VERSION ""

NS_ :

BS_:

BU_: ESM HIB HIP HIS SaGE CBC DASM DIAGNOST EBCM ECM EPS ESC ESL ETM HALF HCP IC OCM ORC PTS RF_HUB SCCM SGW

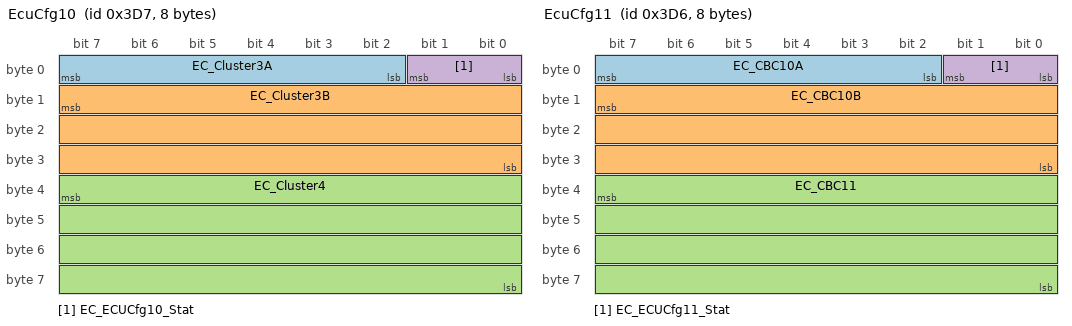
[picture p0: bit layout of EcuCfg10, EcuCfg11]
BO_ 983 EcuCfg10: 8 CBC
 SG_ EC_Cluster3A : 2|6@1+ (1,0) [0|0] ""  RF_HUB,SGW
 SG_ EC_Cluster3B : 15|24@0+ (1,0) [0|0] ""  RF_HUB,SGW
 SG_ EC_Cluster4 : 39|32@0+ (1,0) [0|0] ""  RF_HUB,SGW
 SG_ EC_ECUCfg10_Stat : 0|2@1+ (1,0) [0|0] ""  IC,RF_HUB,SGW

BO_ 982 EcuCfg11: 8 CBC
 SG_ EC_CBC10A : 2|6@1+ (1,0) [0|0] ""  RF_HUB,SGW
 SG_ EC_CBC10B : 15|24@0+ (1,0) [0|0] ""  RF_HUB,SGW
 SG_ EC_CBC11 : 39|32@0+ (1,0) [0|0] ""  RF_HUB,SGW
 SG_ EC_ECUCfg11_Stat : 0|2@1+ (1,0) [0|0] ""  RF_HUB,SGW

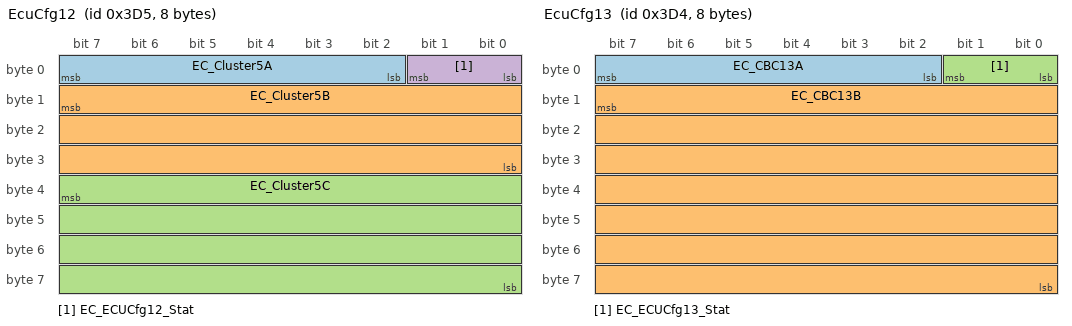
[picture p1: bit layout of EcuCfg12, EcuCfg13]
BO_ 981 EcuCfg12: 8 CBC
 SG_ EC_Cluster5A : 2|6@1+ (1,0) [0|0] ""  RF_HUB,SGW
 SG_ EC_Cluster5B : 15|24@0+ (1,0) [0|0] ""  RF_HUB,SGW
 SG_ EC_Cluster5C : 39|32@0+ (1,0) [0|0] ""  RF_HUB,SGW
 SG_ EC_ECUCfg12_Stat : 0|2@1+ (1,0) [0|0] ""  IC,RF_HUB,SGW

BO_ 980 EcuCfg13: 8 CBC
 SG_ EC_CBC13A : 2|6@1+ (1,0) [0|0] ""  RF_HUB,SGW
 SG_ EC_CBC13B : 15|56@0+ (1,0) [0|0] ""  RF_HUB,SGW
 SG_ EC_ECUCfg13_Stat : 0|2@1+ (1,0) [0|0] ""  RF_HUB,SGW

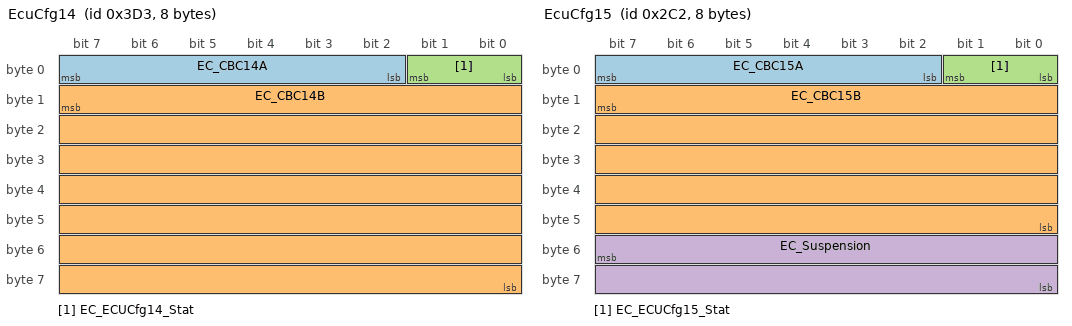
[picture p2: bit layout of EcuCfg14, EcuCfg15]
BO_ 979 EcuCfg14: 8 CBC
 SG_ EC_CBC14A : 2|6@1+ (1,0) [0|0] ""  RF_HUB,SGW
 SG_ EC_CBC14B : 15|56@0+ (1,0) [0|0] ""  RF_HUB,SGW
 SG_ EC_ECUCfg14_Stat : 0|2@1+ (1,0) [0|0] ""  RF_HUB,SGW

BO_ 706 EcuCfg15: 8 CBC
 SG_ EC_CBC15A : 2|6@1+ (1,0) [0|0] ""  RF_HUB,SGW
 SG_ EC_CBC15B : 15|40@0+ (1,0) [0|0] ""  RF_HUB,SGW
 SG_ EC_ECUCfg15_Stat : 0|2@1+ (1,0) [0|0] ""  RF_HUB,SGW
 SG_ EC_Suspension : 55|16@0+ (1,0) [0|0] ""  RF_HUB,SGW

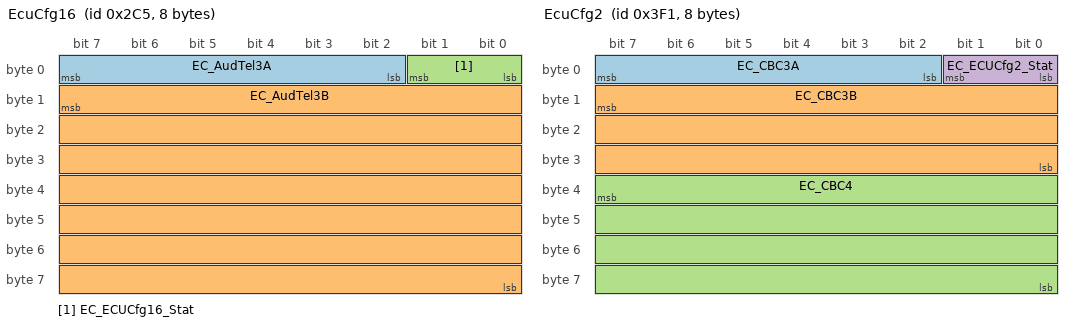
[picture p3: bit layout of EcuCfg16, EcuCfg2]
BO_ 709 EcuCfg16: 8 CBC
 SG_ EC_AudTel3A : 2|6@1+ (1,0) [0|0] ""  RF_HUB,SGW
 SG_ EC_AudTel3B : 15|56@0+ (1,0) [0|0] ""  RF_HUB,SGW
 SG_ EC_ECUCfg16_Stat : 0|2@1+ (1,0) [0|0] ""  RF_HUB,SGW

BO_ 710 EcuCfg17: 8 CBC
 SG_ EC_ECUCfg17_Stat : 0|2@1+ (1,0) [0|0] ""  PTS,RF_HUB,SGW
 SG_ EC_PTS : 56|8@1+ (1,0) [0|0] ""  PTS,RF_HUB,SGW

BO_ 1009 EcuCfg2: 8 CBC
 SG_ EC_CBC3A : 2|6@1+ (1,0) [0|0] ""  RF_HUB,SGW
 SG_ EC_CBC3B : 15|24@0+ (1,0) [0|0] ""  RF_HUB,SGW
 SG_ EC_CBC4 : 39|32@0+ (1,0) [0|0] ""  RF_HUB,SGW
 SG_ EC_ECUCfg2_Stat : 0|2@1+ (1,0) [0|0] ""  RF_HUB,SGW

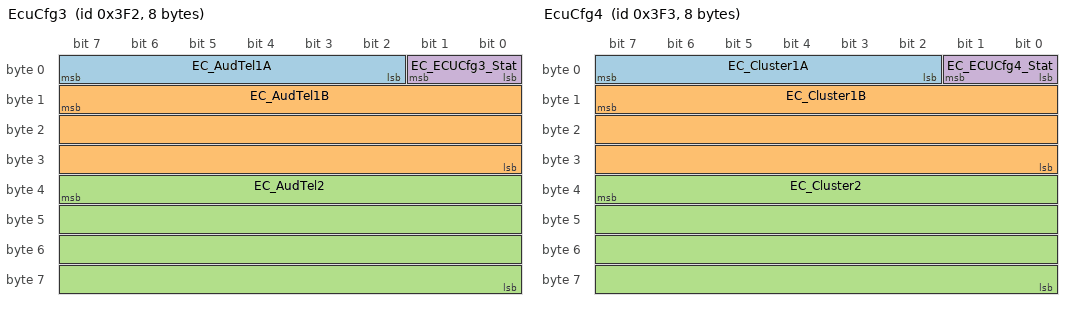
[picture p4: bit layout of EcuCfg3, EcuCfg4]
BO_ 1010 EcuCfg3: 8 CBC
 SG_ EC_AudTel1A : 2|6@1+ (1,0) [0|0] ""  RF_HUB,SGW
 SG_ EC_AudTel1B : 15|24@0+ (1,0) [0|0] ""  RF_HUB,SGW
 SG_ EC_AudTel2 : 39|32@0+ (1,0) [0|0] ""  RF_HUB,SGW
 SG_ EC_ECUCfg3_Stat : 0|2@1+ (1,0) [0|0] ""  RF_HUB,SGW

BO_ 1011 EcuCfg4: 8 CBC
 SG_ EC_Cluster1A : 2|6@1+ (1,0) [0|0] ""  IC,RF_HUB,SGW
 SG_ EC_Cluster1B : 15|24@0+ (1,0) [0|0] ""  IC,RF_HUB,SGW
 SG_ EC_Cluster2 : 39|32@0+ (1,0) [0|0] ""  RF_HUB,SGW
 SG_ EC_ECUCfg4_Stat : 0|2@1+ (1,0) [0|0] ""  IC,RF_HUB,SGW

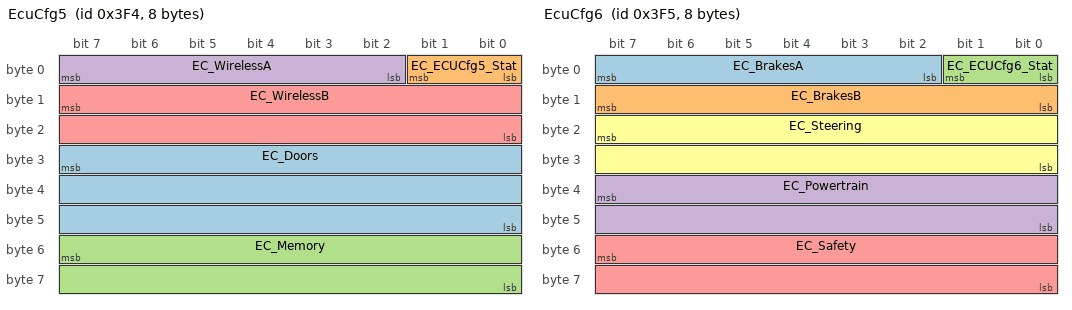
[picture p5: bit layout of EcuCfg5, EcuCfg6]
BO_ 1012 EcuCfg5: 8 CBC
 SG_ EC_Doors : 31|24@0+ (1,0) [0|0] ""  RF_HUB,SGW
 SG_ EC_ECUCfg5_Stat : 0|2@1+ (1,0) [0|0] ""  OCM,RF_HUB,SGW
 SG_ EC_Memory : 55|16@0+ (1,0) [0|0] ""  OCM,RF_HUB,SGW
 SG_ EC_WirelessA : 2|6@1+ (1,0) [0|0] ""  RF_HUB,SGW
 SG_ EC_WirelessB : 15|16@0+ (1,0) [0|0] ""  RF_HUB,SGW

BO_ 1013 EcuCfg6: 8 CBC
 SG_ EC_BrakesA : 2|6@1+ (1,0) [0|0] ""  ESC,RF_HUB,SGW
 SG_ EC_BrakesB : 8|8@1+ (1,0) [0|0] ""  ESC,RF_HUB,SGW
 SG_ EC_ECUCfg6_Stat : 0|2@1+ (1,0) [0|0] ""  ECM,EPS,ESC,ORC,RF_HUB,SGW
 SG_ EC_Powertrain : 39|16@0+ (1,0) [0|0] ""  RF_HUB,SGW
 SG_ EC_Safety : 55|16@0+ (1,0) [0|0] ""  ORC,RF_HUB,SGW
 SG_ EC_Steering : 23|16@0+ (1,0) [0|0] ""  HIB,EPS,RF_HUB,SGW

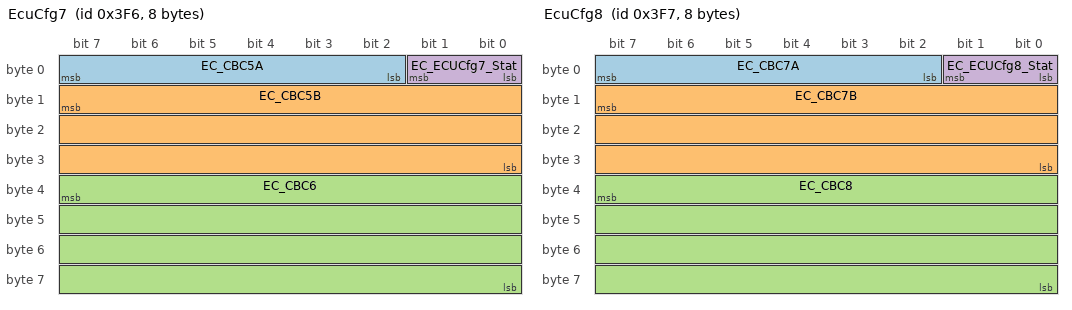
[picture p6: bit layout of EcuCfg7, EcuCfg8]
BO_ 1014 EcuCfg7: 8 CBC
 SG_ EC_CBC5A : 2|6@1+ (1,0) [0|0] ""  RF_HUB,SGW
 SG_ EC_CBC5B : 15|24@0+ (1,0) [0|0] ""  RF_HUB,SGW
 SG_ EC_CBC6 : 39|32@0+ (1,0) [0|0] ""  RF_HUB,SGW
 SG_ EC_ECUCfg7_Stat : 0|2@1+ (1,0) [0|0] ""  RF_HUB,SGW

BO_ 1015 EcuCfg8: 8 CBC
 SG_ EC_CBC7A : 2|6@1+ (1,0) [0|0] ""  RF_HUB,SGW
 SG_ EC_CBC7B : 15|24@0+ (1,0) [0|0] ""  RF_HUB,SGW
 SG_ EC_CBC8 : 39|32@0+ (1,0) [0|0] ""  RF_HUB,SGW
 SG_ EC_ECUCfg8_Stat : 0|2@1+ (1,0) [0|0] ""  RF_HUB,SGW

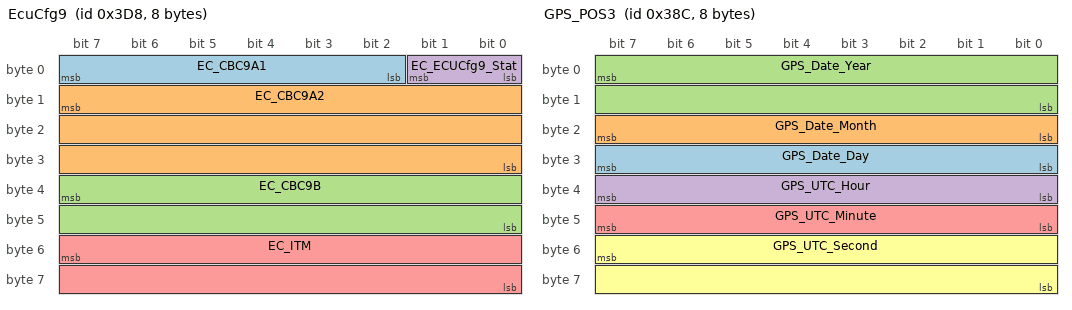
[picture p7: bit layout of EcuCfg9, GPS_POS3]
BO_ 984 EcuCfg9: 8 CBC
 SG_ EC_CBC9A1 : 2|6@1+ (1,0) [0|0] ""  RF_HUB,SGW
 SG_ EC_CBC9A2 : 15|24@0+ (1,0) [0|0] ""  RF_HUB,SGW
 SG_ EC_CBC9B : 39|16@0+ (1,0) [0|0] ""  RF_HUB,SGW
 SG_ EC_ECUCfg9_Stat : 0|2@1+ (1,0) [0|0] ""  RF_HUB,SGW
 SG_ EC_ITM : 55|16@0+ (1,0) [0|0] ""  RF_HUB,SGW

BO_ 908 GPS_POS3: 8 CBC
 SG_ GPS_Date_Day : 24|8@1+ (1,0) [1|31] "Days"  HCP,SGW
 SG_ GPS_Date_Month : 16|8@1+ (1,0) [1|12] "Months"  HCP,SGW
 SG_ GPS_Date_Year : 7|16@0+ (1,0) [0|65534] "Years"  HCP,SGW
 SG_ GPS_UTC_Hour : 32|8@1+ (1,0) [0|23] "h"  HCP,SGW
 SG_ GPS_UTC_Minute : 40|8@1+ (1,0) [0|59] "min"  HCP,SGW
 SG_ GPS_UTC_Second : 55|16@0+ (0.01,0) [0|59.99] "s"  HCP,SGW

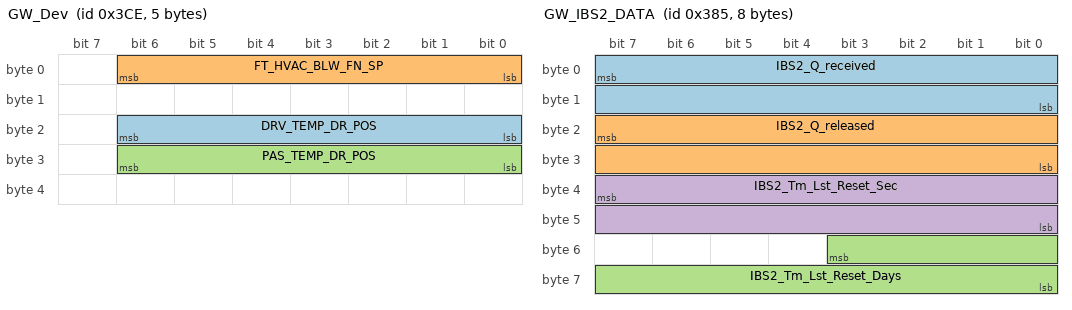
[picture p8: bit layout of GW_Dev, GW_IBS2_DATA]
BO_ 974 GW_Dev: 5 CBC
 SG_ DRV_TEMP_DR_POS : 16|7@1+ (1,0) [0|100] "%"  ECM,HCP,SGW
 SG_ FT_HVAC_BLW_FN_SP : 0|7@1+ (1,0) [0|100] "Bars"  ECM,SGW
 SG_ PAS_TEMP_DR_POS : 24|7@1+ (1,0) [0|100] "%"  HCP,SGW

BO_ 901 GW_IBS2_DATA: 8 CBC
 SG_ IBS2_Q_received : 7|16@0+ (0.125,0) [0|8191.75] "Ah"  SGW
 SG_ IBS2_Q_released : 23|16@0+ (0.125,0) [0|8191.75] "Ah"  SGW
 SG_ IBS2_Tm_Lst_Reset_Days : 51|12@0+ (1,0) [0|4094] "Days"  SGW
 SG_ IBS2_Tm_Lst_Reset_Sec : 39|16@0+ (2,0) [0|86398] "sec"  SGW

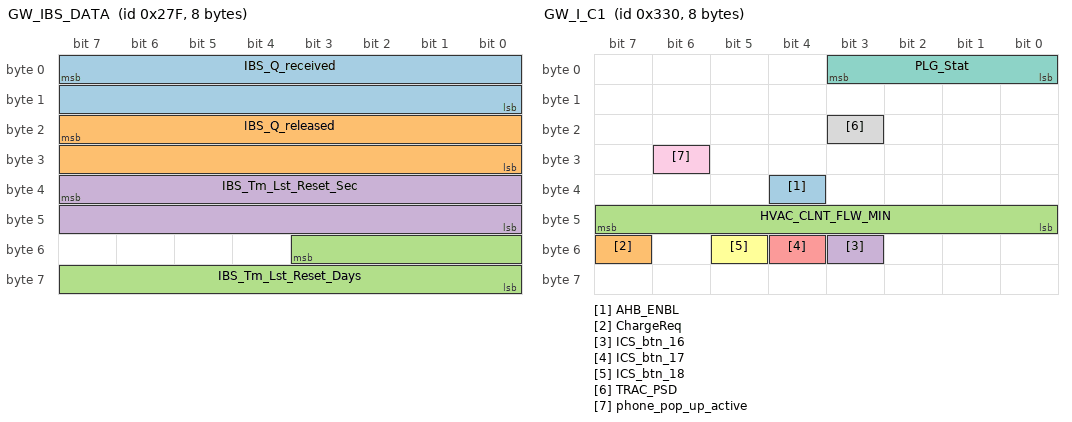
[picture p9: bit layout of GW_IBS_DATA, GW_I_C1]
BO_ 639 GW_IBS_DATA: 8 CBC
 SG_ IBS_Q_received : 7|16@0+ (0.125,0) [0|8191.75] "Ah"  SGW
 SG_ IBS_Q_released : 23|16@0+ (0.125,0) [0|8191.75] "Ah"  SGW
 SG_ IBS_Tm_Lst_Reset_Days : 51|12@0+ (1,0) [0|4094] "Days"  SGW
 SG_ IBS_Tm_Lst_Reset_Sec : 39|16@0+ (2,0) [0|86398] "sec"  SGW

BO_ 816 GW_I_C1: 8 CBC
 SG_ AHB_ENBL : 36|1@1+ (1,0) [0|0] ""  SGW
 SG_ ChargeReq : 55|1@1+ (1,0) [0|0] ""  HCP,IC,SGW
 SG_ HVAC_CLNT_FLW_MIN : 40|8@1+ (0.521555,0) [0.521555|131.953415] "LpM"  SGW
 SG_ ICS_btn_16 : 51|1@1+ (1,0) [0|0] ""  PTS,SGW
 SG_ ICS_btn_17 : 52|1@1+ (1,0) [0|0] ""  PTS,SGW
 SG_ ICS_btn_18 : 53|1@1+ (1,0) [0|0] ""  HIB,HALF,SGW
 SG_ PLG_Stat : 0|4@1+ (1,0) [0|0] ""  IC,SGW
 SG_ TRAC_PSD : 19|1@1+ (1,0) [0|0] ""  ESC,IC,SGW
 SG_ phone_pop_up_active : 30|1@1+ (1,0) [0|0] ""  IC,SGW

BO_ 853 GW_LIN_I_C1: 8 CBC
 SG_ IBS_IBATT_QUIESCENT : 56|8@1+ (0.00390625,0) [0|0.984375] "Amp"  SGW

BO_ 854 GW_LIN_I_C1_IBS2: 8 CBC
 SG_ IBS2_IBATT_QUIESCENT : 56|8@1+ (0.00390625,0) [0|0.984375] "Amp"  SGW

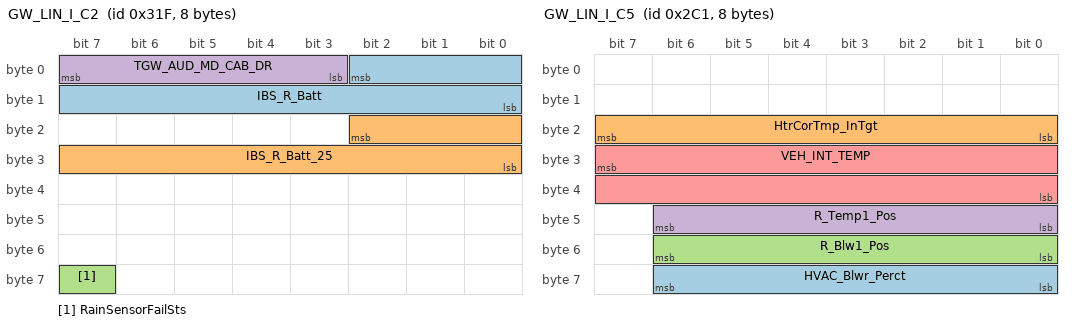
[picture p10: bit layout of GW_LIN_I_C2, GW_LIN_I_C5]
BO_ 799 GW_LIN_I_C2: 8 CBC
 SG_ IBS_R_Batt : 2|11@0+ (0.05,0) [0|20] "mOhm"  SGW
 SG_ IBS_R_Batt_25 : 18|11@0+ (0.05,0) [0|20] "mOhm"  SGW
 SG_ RainSensorFailSts : 63|1@1+ (1,0) [0|0] ""  IC,SGW
 SG_ TGW_AUD_MD_CAB_DR : 3|5@1+ (1,0) [0|0] ""  IC,SGW

BO_ 798 GW_LIN_I_C2_IBS2: 8 CBC
 SG_ IBS2_R_Batt : 2|11@0+ (0.05,0) [0|20] "mOhm"  SGW
 SG_ IBS2_R_Batt_25 : 18|11@0+ (0.05,0) [0|20] "mOhm"  SGW

BO_ 817 GW_LIN_I_C3: 8 CBC
 SG_ PSD_LT_DisplayStat : 56|4@1+ (1,0) [0|0] ""  IC,SGW
 SG_ PSD_RT_DisplayStat : 60|4@1+ (1,0) [0|0] ""  IC,SGW

BO_ 579 GW_LIN_I_C4: 8 CBC
 SG_ Phone_Popup_setting_active : 55|1@1+ (1,0) [0|0] ""  IC,SGW
 SG_ TGW_AUD_MD2_CAB_DR : 24|6@1+ (1,0) [0|0] ""  IC,SGW

BO_ 705 GW_LIN_I_C5: 8 CBC
 SG_ HVAC_Blwr_Perct : 56|7@1+ (1,0) [0|100] "%"  HCP,SGW
 SG_ HtrCorTmp_InTgt : 16|8@1+ (1,-40) [-40|214] "°C"  HCP,SGW
 SG_ R_Blw1_Pos : 48|7@1+ (1,0) [0|100] "%"  HCP,SGW
 SG_ R_Temp1_Pos : 40|7@1+ (1,0) [0|100] "%"  HCP,SGW
 SG_ VEH_INT_TEMP : 31|16@0+ (0.01,-40) [-40|85] "°C"  HCP,SGW

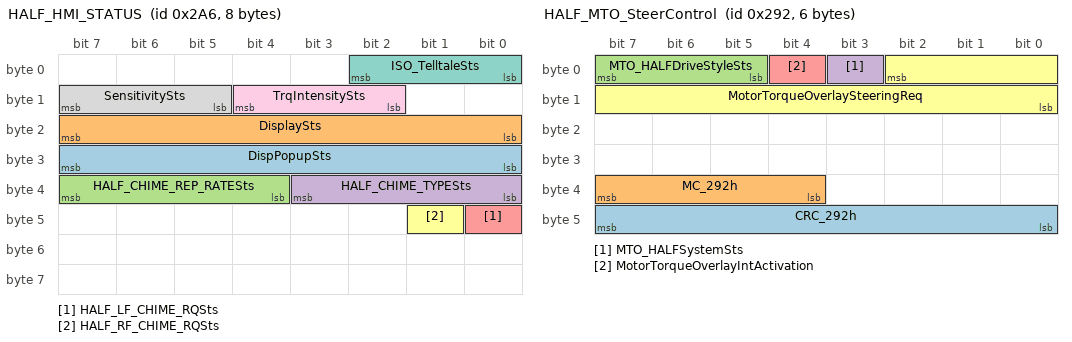
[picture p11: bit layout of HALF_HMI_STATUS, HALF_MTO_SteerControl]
BO_ 678 HALF_HMI_STATUS: 8 HALF
 SG_ DispPopupSts : 24|8@1+ (1,0) [0|0] ""  IC,ORC,SGW
 SG_ DisplaySts : 16|8@1+ (1,0) [0|0] ""  IC,ORC,SGW
 SG_ HALF_CHIME_REP_RATESts : 36|4@1+ (1,0) [0|15] ""  CBC,SGW
 SG_ HALF_CHIME_TYPESts : 32|4@1+ (1,0) [0|0] ""  CBC,SGW
 SG_ HALF_LF_CHIME_RQSts : 40|1@1+ (1,0) [0|0] ""  CBC,SGW
 SG_ HALF_RF_CHIME_RQSts : 41|1@1+ (1,0) [0|0] ""  CBC,SGW
 SG_ ISO_TelltaleSts : 0|3@1+ (1,0) [0|0] ""  IC,ORC,SGW
 SG_ SensitivitySts : 13|3@1+ (1,0) [0|0] ""  IC,SGW
 SG_ TrqIntensitySts : 10|3@1+ (1,0) [0|0] ""  IC,SGW

BO_ 658 HALF_MTO_SteerControl: 6 HALF
 SG_ CRC_292h : 40|8@1+ (1,0) [0|0] ""  EPS,SGW
 SG_ MC_292h : 36|4@1+ (1,0) [0|15] ""  EPS,SGW
 SG_ MTO_HALFDriveStyleSts : 5|3@1+ (1,0) [0|0] ""  EPS,SGW
 SG_ MTO_HALFSystemSts : 3|1@1+ (1,0) [0|0] ""  EPS,SGW
 SG_ MotorTorqueOverlayIntActivation : 4|1@1+ (1,0) [0|0] ""  EPS,SGW
 SG_ MotorTorqueOverlaySteeringReq : 2|11@0+ (0.001953125,-2) [-2|1.998047] "Nm"  EPS,SGW

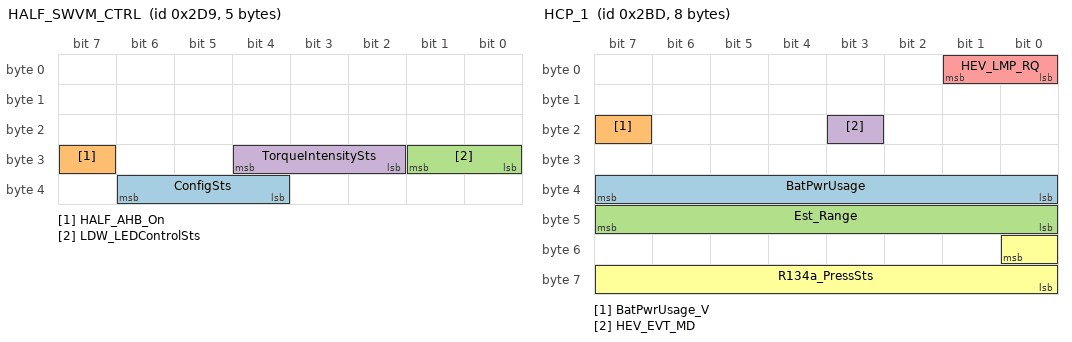
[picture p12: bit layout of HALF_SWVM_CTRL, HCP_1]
BO_ 729 HALF_SWVM_CTRL: 5 HALF
 SG_ ConfigSts : 36|3@1+ (1,0) [0|0] ""  CBC,SGW
 SG_ HALF_AHB_On : 31|1@1+ (1,0) [0|0] ""  CBC,SGW
 SG_ LDW_LEDControlSts : 24|2@1+ (1,0) [0|0] ""  CBC,SGW
 SG_ TorqueIntensitySts : 26|3@1+ (1,0) [0|0] ""  CBC,SGW

BO_ 701 HCP_1: 8 HCP
 SG_ BatPwrUsage : 32|8@1+ (1,-125) [-125|130] "kW"  IC,SGW
 SG_ BatPwrUsage_V : 23|1@1+ (1,0) [0|0] ""  IC,SGW
 SG_ Est_Range : 40|8@1+ (1,0) [0|254] "km"  ETM,IC,SGW
 SG_ HEV_EVT_MD : 19|1@1+ (1,0) [0|0] ""  HIB,CBC,DASM,ETM,IC,SGW
 SG_ HEV_LMP_RQ : 0|2@1+ (1,0) [0|0] ""  ETM,IC,ORC,SGW
 SG_ R134a_PressSts : 48|9@0+ (0.1,0) [0|40] "bar"  CBC,SGW

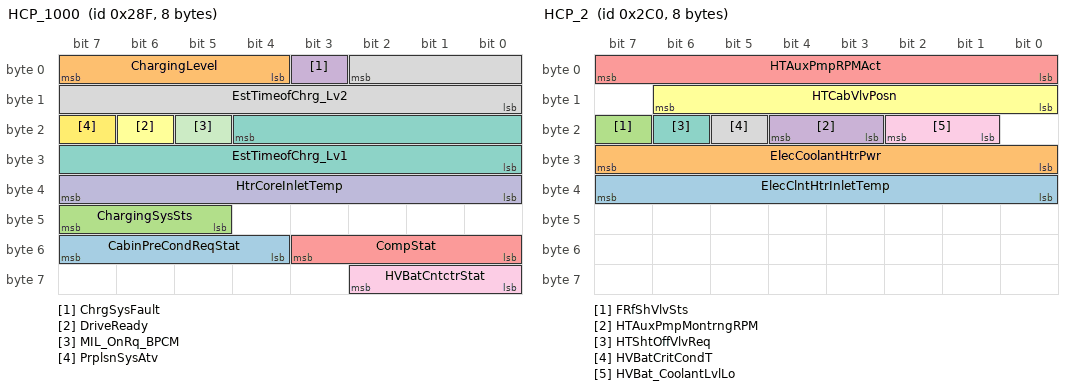
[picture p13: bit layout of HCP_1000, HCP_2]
BO_ 655 HCP_1000: 8 HCP
 SG_ CabinPreCondReqStat : 52|4@1+ (1,0) [0|0] ""  ETM,SGW
 SG_ ChargingLevel : 4|4@1+ (1,0) [0|0] ""  CBC,ETM,IC,SGW
 SG_ ChargingSysSts : 45|3@1+ (1,0) [0|0] ""  ETM,IC,SGW
 SG_ ChrgSysFault : 3|1@1+ (1,0) [0|0] ""  ETM,IC,SGW
 SG_ CompStat : 48|4@1+ (1,0) [0|0] ""  CBC,SGW
 SG_ DriveReady : 22|1@1+ (1,0) [0|0] ""  HIB,CBC,DASM,IC,SGW
 SG_ EstTimeofChrg_Lv1 : 20|13@0+ (1,0) [0|8190] "min"  ETM,IC,SGW
 SG_ EstTimeofChrg_Lv2 : 2|11@0+ (1,0) [0|2046] "min"  ETM,IC,SGW
 SG_ HVBatCntctrStat : 56|3@1+ (1,0) [0|0] ""  IC,SGW
 SG_ HtrCoreInletTemp : 32|8@1+ (1,-40) [-40|214] "°C"  CBC,ECM,SGW
 SG_ MIL_OnRq_BPCM : 21|1@1+ (1,0) [0|0] ""  IC,SGW
 SG_ PrplsnSysAtv : 23|1@1+ (1,0) [0|0] ""  CBC,ECM,EPS,ESC,ETM,HCP,IC,PTS,RF_HUB,SGW

BO_ 704 HCP_2: 8 HCP
 SG_ ElecClntHtrInletTemp : 32|8@1+ (1,-40) [-40|214] "°C"  ECM,SGW
 SG_ ElecCoolantHtrPwr : 24|8@1+ (0.04,0) [0|10.16] "kW"  CBC,ECM,SGW
 SG_ FRfShVlvSts : 23|1@1+ (1,0) [0|0] ""  CBC,SGW
 SG_ HTAuxPmpMontrngRPM : 19|2@1+ (1,0) [0|0] ""  ECM,SGW
 SG_ HTAuxPmpRPMAct : 0|8@1+ (24,0) [0|6096] "rpm"  CBC,ECM,SGW
 SG_ HTCabVlvPosn : 8|7@1+ (1,0) [0|100] "%"  CBC,ECM,SGW
 SG_ HTShtOffVlvReq : 22|1@1+ (1,0) [0|0] ""  CBC,ECM,SGW
 SG_ HVBatCritCondT : 21|1@1+ (1,0) [0|0] ""  CBC,SGW
 SG_ HVBat_CoolantLvlLo : 17|2@1+ (1,0) [0|0] ""  IC,SGW

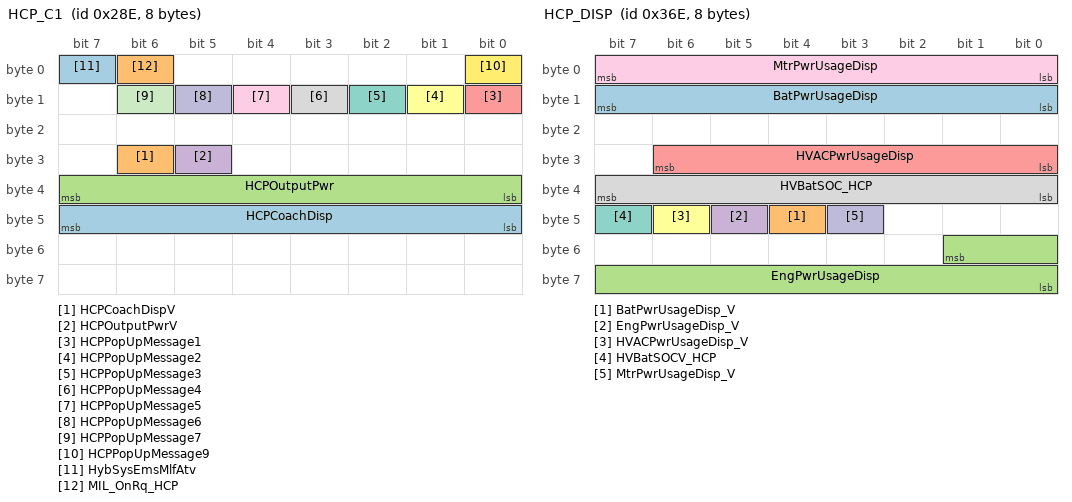
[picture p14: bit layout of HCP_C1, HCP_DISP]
BO_ 654 HCP_C1: 8 HCP
 SG_ HCPCoachDisp : 40|8@1+ (1,-100) [-100|100] "%"  IC,SGW
 SG_ HCPCoachDispV : 30|1@1+ (1,0) [0|0] ""  IC,SGW
 SG_ HCPOutputPwr : 32|8@1+ (1,-100) [-100|100] "%"  IC,SGW
 SG_ HCPOutputPwrV : 29|1@1+ (1,0) [0|0] ""  IC,SGW
 SG_ HCPPopUpMessage1 : 8|1@1+ (1,0) [0|0] ""  IC,SGW
 SG_ HCPPopUpMessage2 : 9|1@1+ (1,0) [0|0] ""  IC,SGW
 SG_ HCPPopUpMessage3 : 10|1@1+ (1,0) [0|0] ""  IC,SGW
 SG_ HCPPopUpMessage4 : 11|1@1+ (1,0) [0|0] ""  IC,SGW
 SG_ HCPPopUpMessage5 : 12|1@1+ (1,0) [0|0] ""  IC,SGW
 SG_ HCPPopUpMessage6 : 13|1@1+ (1,0) [0|0] ""  IC,SGW
 SG_ HCPPopUpMessage7 : 14|1@1+ (1,0) [0|0] ""  IC,SGW
 SG_ HCPPopUpMessage9 : 0|1@1+ (1,0) [0|0] ""  IC,SGW
 SG_ HybSysEmsMlfAtv : 7|1@1+ (1,0) [0|0] ""  SGW
 SG_ MIL_OnRq_HCP : 6|1@1+ (1,0) [0|0] ""  ECM,SGW

BO_ 878 HCP_DISP: 8 HCP
 SG_ BatPwrUsageDisp : 8|8@1+ (1,-125) [-125|130] "kW"  ETM,SGW
 SG_ BatPwrUsageDisp_V : 44|1@1+ (1,0) [0|0] ""  ETM,SGW
 SG_ EngPwrUsageDisp : 49|10@0+ (1,0) [0|1023] "kW"  ETM,IC,SGW
 SG_ EngPwrUsageDisp_V : 45|1@1+ (1,0) [0|0] ""  ETM,IC,SGW
 SG_ HVACPwrUsageDisp : 24|7@1+ (1,0) [0|127] "kW"  ETM,SGW
 SG_ HVACPwrUsageDisp_V : 46|1@1+ (1,0) [0|0] ""  ETM,SGW
 SG_ HVBatSOCV_HCP : 47|1@1+ (1,0) [0|0] ""  ETM,IC,SGW
 SG_ HVBatSOC_HCP : 32|8@1+ (0.3922,0) [0|100] "%"  ETM,IC,SGW
 SG_ MtrPwrUsageDisp : 0|8@1+ (1,-125) [-125|130] "kW"  IC,SGW
 SG_ MtrPwrUsageDisp_V : 43|1@1+ (1,0) [0|0] ""  IC,SGW

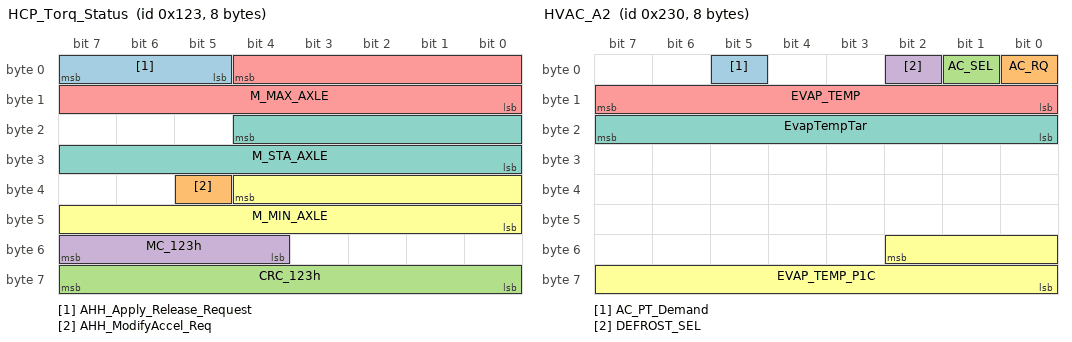
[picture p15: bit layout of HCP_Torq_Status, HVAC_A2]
BO_ 291 HCP_Torq_Status: 8 HCP
 SG_ AHH_Apply_Release_Request : 5|3@1+ (1,0) [0|0] ""  ESC,SGW
 SG_ AHH_ModifyAccel_Req : 37|1@1+ (1,0) [0|0] ""  ECM,SGW
 SG_ CRC_123h : 56|8@1+ (1,0) [0|255] ""  HIB,DASM,ESC,SGW
 SG_ MC_123h : 52|4@1+ (1,0) [0|15] ""  HIB,DASM,ESC,SGW
 SG_ M_MAX_AXLE : 4|13@0+ (4,-7767) [-7767|24993] ""  HIB,DASM,ESC,SGW
 SG_ M_MIN_AXLE : 36|13@0+ (4,-7767) [-7767|24993] ""  HIB,DASM,ESC,SGW
 SG_ M_STA_AXLE : 20|13@0+ (4,-7767) [-7767|24993] ""  HIB,DASM,ECM,ESC,ORC,SGW

BO_ 560 HVAC_A2: 8 CBC
 SG_ AC_PT_Demand : 5|1@1+ (1,0) [0|0] ""  ECM,SGW
 SG_ AC_RQ : 0|1@1+ (1,0) [0|0] ""  HCP,SGW
 SG_ AC_SEL : 1|1@1+ (1,0) [0|0] ""  SGW
 SG_ DEFROST_SEL : 2|1@1+ (1,0) [0|0] ""  HCP,SGW
 SG_ EVAP_TEMP : 8|8@1+ (0.5,-20) [-20|107] "°C"  HCP,SGW
 SG_ EVAP_TEMP_P1C : 50|11@0+ (0.1,-40) [-40|85] "°C"  HCP,SGW
 SG_ EvapTempTar : 16|8@1+ (0.5,-20) [-20|107] "°C"  HCP,SGW

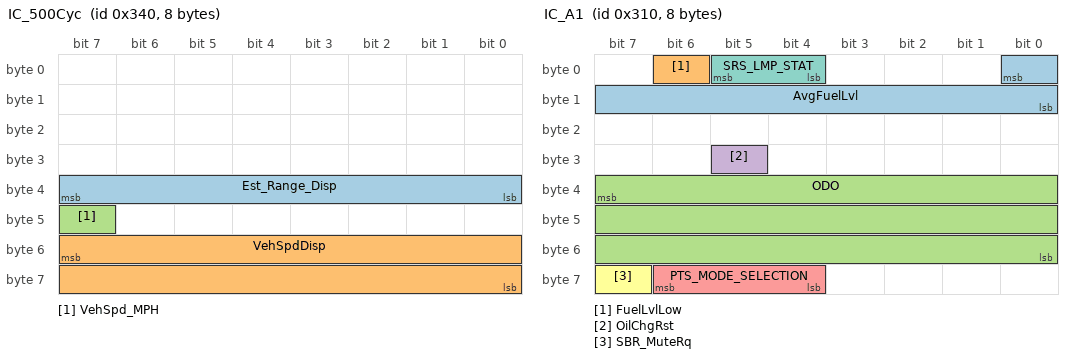
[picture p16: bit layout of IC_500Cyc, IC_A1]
BO_ 832 IC_500Cyc: 8 IC
 SG_ Est_Range_Disp : 32|8@1+ (1,0) [0|254] ""  ETM,SGW
 SG_ VehSpdDisp : 55|16@0+ (1,0) [0|65534] ""  CBC,SGW
 SG_ VehSpd_MPH : 47|1@1+ (1,0) [0|0] ""  CBC,SGW

BO_ 784 IC_A1: 8 IC
 SG_ AvgFuelLvl : 0|9@0+ (0.5,0) [0|255] "liters"  CBC,ETM,SGW
 SG_ FuelLvlLow : 6|1@1+ (1,0) [0|0] ""  CBC,ECM,ETM,SGW
 SG_ ODO : 39|24@0+ (0.1,0) [0|1677721.4] "km"  HIB,CBC,DASM,EBCM,ECM,EPS,ESC,ESL,HALF,HCP,OCM,ORC,PTS,RF_HUB,SCCM,SGW
 SG_ OilChgRst : 29|1@1+ (1,0) [0|0] ""  ECM,SGW
 SG_ PTS_MODE_SELECTION : 60|3@1+ (1,0) [0|0] ""  PTS,SGW
 SG_ SBR_MuteRq : 63|1@1+ (1,0) [0|0] ""  CBC,SGW
 SG_ SRS_LMP_STAT : 4|2@1+ (1,0) [0|0] ""  ETM,ORC,SGW

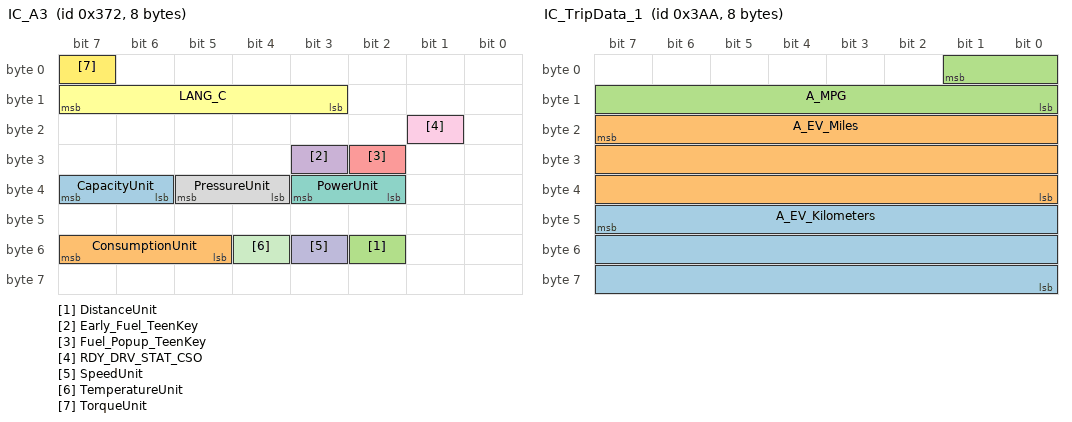
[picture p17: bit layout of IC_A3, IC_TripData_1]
BO_ 882 IC_A3: 8 IC
 SG_ CapacityUnit : 38|2@1+ (1,0) [0|0] ""  CBC,SGW
 SG_ ConsumptionUnit : 53|3@1+ (1,0) [0|0] ""  CBC,SGW
 SG_ DistanceUnit : 50|1@1+ (1,0) [0|0] ""  CBC,SGW
 SG_ Early_Fuel_TeenKey : 27|1@1+ (1,0) [0|0] ""  CBC,SGW
 SG_ Fuel_Popup_TeenKey : 26|1@1+ (1,0) [0|0] ""  CBC,SGW
 SG_ LANG_C : 11|5@1+ (1,0) [0|0] ""  CBC,SGW
 SG_ PowerUnit : 34|2@1+ (1,0) [0|0] ""  CBC,SGW
 SG_ PressureUnit : 36|2@1+ (1,0) [0|0] ""  CBC,SGW
 SG_ RDY_DRV_STAT_CSO : 17|1@1+ (1,0) [0|0] ""  CBC,SGW
 SG_ SpeedUnit : 51|1@1+ (1,0) [0|0] ""  HIB,CBC,DASM,ECM,SGW
 SG_ TemperatureUnit : 52|1@1+ (1,0) [0|0] ""  CBC,SGW
 SG_ TorqueUnit : 7|1@1+ (1,0) [0|0] ""  CBC,SGW

BO_ 782 IC_A5: 8 IC
 SG_ Gas_Range : 1|10@0+ (1,0) [0|1022] "km"  CBC,ETM,SGW
 SG_ Total_Range : 18|11@0+ (1,0) [0|2046] "km"  CBC,ETM,SGW

BO_ 938 IC_TripData_1: 8 IC
 SG_ A_EV_Kilometers : 47|24@0+ (0.1,0) [0|16093.3] "km"  ETM,SGW
 SG_ A_EV_Miles : 23|24@0+ (0.1,0) [0|9999.9] "Mile"  ETM,SGW
 SG_ A_MPG : 1|10@0+ (0.1,0) [0|99.9] "MPG"  ETM,SGW

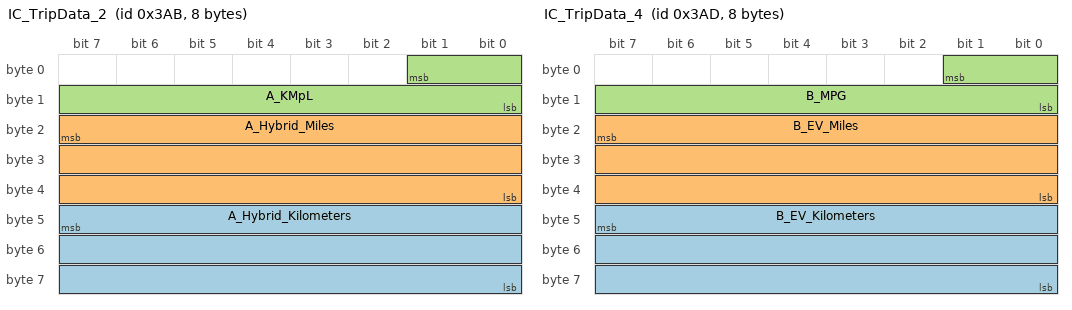
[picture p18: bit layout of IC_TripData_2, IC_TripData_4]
BO_ 939 IC_TripData_2: 8 IC
 SG_ A_Hybrid_Kilometers : 47|24@0+ (0.1,0) [0|16093.3] "km"  ETM,SGW
 SG_ A_Hybrid_Miles : 23|24@0+ (0.1,0) [0|9999.9] "Mile"  ETM,SGW
 SG_ A_KMpL : 1|10@0+ (0.1,0) [0|99.9] "kmpl"  ETM,SGW

BO_ 940 IC_TripData_3: 8 IC
 SG_ A_Total_Dist_Kilometers : 47|24@0+ (0.1,0) [0|16093.3] "km"  ETM,SGW
 SG_ A_Total_Dist_Miles : 23|24@0+ (0.1,0) [0|9999.9] "Mile"  ETM,SGW

BO_ 941 IC_TripData_4: 8 IC
 SG_ B_EV_Kilometers : 47|24@0+ (0.1,0) [0|16093.3] "km"  ETM,SGW
 SG_ B_EV_Miles : 23|24@0+ (0.1,0) [0|9999.9] "Mile"  ETM,SGW
 SG_ B_MPG : 1|10@0+ (0.1,0) [0|99.9] "MPG"  ETM,SGW

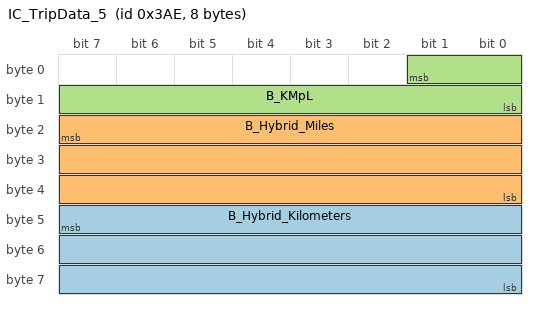
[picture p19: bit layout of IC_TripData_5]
BO_ 942 IC_TripData_5: 8 IC
 SG_ B_Hybrid_Kilometers : 47|24@0+ (0.1,0) [0|16093.3] "km"  ETM,SGW
 SG_ B_Hybrid_Miles : 23|24@0+ (0.1,0) [0|9999.9] "Mile"  ETM,SGW
 SG_ B_KMpL : 1|10@0+ (0.1,0) [0|99.9] "kmpl"  ETM,SGW

CM_ SG_ 983 EC_Cluster3A "Instrument cluster ecu configuration 3A";
CM_ SG_ 983 EC_Cluster3B "Instrument cluster ecu configuration 3B";
CM_ SG_ 983 EC_Cluster4 "Instrument cluster ecu configuration 4";
CM_ SG_ 983 EC_ECUCfg10_Stat "ECU Configuration messages status 10";
CM_ SG_ 982 EC_CBC10A "CBC ecu configuration 10A";
CM_ SG_ 982 EC_CBC10B "CBC ecu configuration 10B";
CM_ SG_ 982 EC_CBC11 "CBC ecu configuration 11";
CM_ SG_ 982 EC_ECUCfg11_Stat "ECU Configuration messages status 11";
CM_ SG_ 981 EC_Cluster5A "Instrument cluster ecu configuration 5A";
CM_ SG_ 981 EC_Cluster5B "Instrument cluster ecu configuration 5B";
CM_ SG_ 981 EC_Cluster5C "Instrument cluster ecu configuration 5C";
CM_ SG_ 981 EC_ECUCfg12_Stat "ECU Configuration messages status 12";
CM_ SG_ 980 EC_CBC13A "CBC ecu configuration 13A";
CM_ SG_ 980 EC_CBC13B "CBC ecu configuration 13B";
CM_ SG_ 980 EC_ECUCfg13_Stat "ECU Configuration messages status 13";
CM_ SG_ 979 EC_CBC14A "CBC ecu configuration 14A";
CM_ SG_ 979 EC_CBC14B "CBC ecu configuration 14B";
CM_ SG_ 979 EC_ECUCfg14_Stat "ECU Configuration messages status 14";
CM_ SG_ 706 EC_CBC15A "CBC ecu configuration 15A";
CM_ SG_ 706 EC_CBC15B "CBC ecu configuration 15B";
CM_ SG_ 706 EC_ECUCfg15_Stat "ECU Configuration messages status 15";
CM_ SG_ 706 EC_Suspension "Suspension ecu configuration";
CM_ SG_ 709 EC_AudTel3A "Audio and telematics ecu configuration 3A";
CM_ SG_ 709 EC_AudTel3B "Audio and telematics ecu configuration 3B";
CM_ SG_ 709 EC_ECUCfg16_Stat "ECU Configuration messages status 16";
CM_ SG_ 710 EC_ECUCfg17_Stat "ECU Configuration messages status 17";
CM_ SG_ 710 EC_PTS "Park assist ecu configuration";
CM_ SG_ 1009 EC_CBC3A "CBC ecu configuration 3A";
CM_ SG_ 1009 EC_CBC3B "CBC ecu configuration 3B";
CM_ SG_ 1009 EC_CBC4 "CBC ecu configuration 4";
CM_ SG_ 1009 EC_ECUCfg2_Stat "ECU Configuration messages status 2";
CM_ SG_ 1010 EC_AudTel1A "Audio and telematics ecu configuration 1A";
CM_ SG_ 1010 EC_AudTel1B "Audio and telematics ecu configuration 1B";
CM_ SG_ 1010 EC_AudTel2 "Audio and telematics ecu configuration 2";
CM_ SG_ 1010 EC_ECUCfg3_Stat "ECU Configuration messages status 3";
CM_ SG_ 1011 EC_Cluster1A "Instrument cluster ecu configuration 1A";
CM_ SG_ 1011 EC_Cluster1B "Instrument cluster ecu configuration 1B";
CM_ SG_ 1011 EC_Cluster2 "Instrument cluster ecu configuration 2";
CM_ SG_ 1011 EC_ECUCfg4_Stat "ECU Configuration messages status 4";
CM_ SG_ 1012 EC_Doors "Doors ecu configuration";
CM_ SG_ 1012 EC_ECUCfg5_Stat "ECU Configuration messages status 5";
CM_ SG_ 1012 EC_Memory "Memory ecu configuration";
CM_ SG_ 1012 EC_WirelessA "Wireless ecu configurationA";
CM_ SG_ 1012 EC_WirelessB "Wireless ecu configurationB";
CM_ SG_ 1013 EC_BrakesA "Brake system ecu configurationA";
CM_ SG_ 1013 EC_BrakesB "Brake system ecu configurationB";
CM_ SG_ 1013 EC_ECUCfg6_Stat "ECU Configuration messages status 6";
CM_ SG_ 1013 EC_Powertrain "Powertrain ecu configuration";
CM_ SG_ 1013 EC_Safety "Safety ecu configuration";
CM_ SG_ 1013 EC_Steering "Steering ecu configuration";
CM_ SG_ 1014 EC_CBC5A "CBC ecu configuration 5A";
CM_ SG_ 1014 EC_CBC5B "CBC ecu configuration 5B";
CM_ SG_ 1014 EC_CBC6 "CBC ecu configuration 6";
CM_ SG_ 1014 EC_ECUCfg7_Stat "ECU Configuration messages status 7";
CM_ SG_ 1015 EC_CBC7A "CBC ecu configuration 7A";
CM_ SG_ 1015 EC_CBC7B "CBC ecu configuration 7B";
CM_ SG_ 1015 EC_CBC8 "CBC ecu configuration 8";
CM_ SG_ 1015 EC_ECUCfg8_Stat "ECU Configuration messages status 8";
CM_ SG_ 984 EC_CBC9A1 "CBC configuration 9A1";
CM_ SG_ 984 EC_CBC9A2 "CBC configuration 9A2";
CM_ SG_ 984 EC_CBC9B "CBC configuration 9B";
CM_ SG_ 984 EC_ECUCfg9_Stat "ECU Configuration messages status 9";
CM_ SG_ 984 EC_ITM "ITM ecu configuration";
CM_ SG_ 908 GPS_Date_Day "GPS date day";
CM_ SG_ 908 GPS_Date_Month "GPS date month";
CM_ SG_ 908 GPS_Date_Year "GPS date year";
CM_ SG_ 908 GPS_UTC_Hour "GPS UTC hour";
CM_ SG_ 908 GPS_UTC_Minute "GPS UTC minute";
CM_ SG_ 908 GPS_UTC_Second "GPS UTC second";
CM_ SG_ 974 DRV_TEMP_DR_POS "Driver temperature door postion";
CM_ SG_ 974 FT_HVAC_BLW_FN_SP "Front HVAC blower fan speed status in 'bars'";
CM_ SG_ 974 PAS_TEMP_DR_POS "Passenger temperature door postion";
CM_ SG_ 901 IBS2_Q_received "LifeTime charge received - 2nd batt";
CM_ SG_ 901 IBS2_Q_released "Lifetime charge released - 2nd batt";
CM_ SG_ 901 IBS2_Tm_Lst_Reset_Days "Accumulated time since last reset in days - 2nd batt";
CM_ SG_ 901 IBS2_Tm_Lst_Reset_Sec "Accumulated time since last reset in seconds - 2nd batt";
CM_ SG_ 639 IBS_Q_received "LifeTime charge received";
CM_ SG_ 639 IBS_Q_released "Lifetime charge released";
CM_ SG_ 639 IBS_Tm_Lst_Reset_Days "Accumulated time since last reset in days";
CM_ SG_ 639 IBS_Tm_Lst_Reset_Sec "Accumulated time since last reset in seconds";
CM_ SG_ 816 AHB_ENBL "Auto highbeam enable";
CM_ SG_ 816 ChargeReq "Request for scheduled charge; Charge now = [1]";
CM_ SG_ 816 HVAC_CLNT_FLW_MIN "HVAC coolant flow minimum request";
CM_ SG_ 816 ICS_btn_16 "PPA pressed";
CM_ SG_ 816 ICS_btn_17 "PTS Off pressed";
CM_ SG_ 816 ICS_btn_18 "LDW Off pressed";
CM_ SG_ 816 PLG_Stat "Power liftgate status";
CM_ SG_ 816 TRAC_PSD "Traction on/off button pressed; [0] = Not Pressed, [1] = Pressed";
CM_ SG_ 816 phone_pop_up_active "Phone pop up is active; True = [1]";
CM_ SG_ 853 IBS_IBATT_QUIESCENT "Battery quiescent current";
CM_ SG_ 854 IBS2_IBATT_QUIESCENT "Battery 2 quiescent current";
CM_ SG_ 799 IBS_R_Batt "Calculated battery resistance";
CM_ SG_ 799 IBS_R_Batt_25 "Batt resistance at 100% SOC and 25 degC";
CM_ SG_ 799 RainSensorFailSts "Fail present = 1";
CM_ SG_ 799 TGW_AUD_MD_CAB_DR "TGW audio mode for Cabin/Driver";
CM_ SG_ 798 IBS2_R_Batt "Calculated secondary battery resistance";
CM_ SG_ 798 IBS2_R_Batt_25 "Secondary batt resistance at 100% SOC and 25 degC";
CM_ SG_ 817 PSD_LT_DisplayStat "Left power sliding door display status";
CM_ SG_ 817 PSD_RT_DisplayStat "Right power sliding door display status";
CM_ SG_ 579 Phone_Popup_setting_active "Phone call status popup active or not, Active=1";
CM_ SG_ 579 TGW_AUD_MD2_CAB_DR "TGW additional audio modes for Cabin/Driver";
CM_ SG_ 705 HVAC_Blwr_Perct "HVAC blower PWM percentage for service mode";
CM_ SG_ 705 HtrCorTmp_InTgt "Heater core temp target";
CM_ SG_ 705 R_Blw1_Pos "Rear blower 1 position";
CM_ SG_ 705 R_Temp1_Pos "Rear temperature 1 position";
CM_ SG_ 705 VEH_INT_TEMP "Vehicle interior temperature";
CM_ SG_ 678 DispPopupSts "LDW message status in cluster";
CM_ SG_ 678 DisplaySts "LDW display status in cluster";
CM_ SG_ 678 HALF_CHIME_REP_RATESts "LDW chime repetition rate; Continuous = [0]";
CM_ SG_ 678 HALF_CHIME_TYPESts "LDW chime type";
CM_ SG_ 678 HALF_LF_CHIME_RQSts "LDW chime request for left side; true = [1]";
CM_ SG_ 678 HALF_RF_CHIME_RQSts "LDW chime request for right side; true = [1]";
CM_ SG_ 678 ISO_TelltaleSts "LDW telltale status in cluster";
CM_ SG_ 678 SensitivitySts "LDW sensitivity level for display in cluster";
CM_ SG_ 678 TrqIntensitySts "LDW torque intesity level for display in cluster";
CM_ SG_ 658 CRC_292h "CRC-checksum byte 1 to 5 according to SAE J1850";
CM_ SG_ 658 MC_292h "Message counter";
CM_ SG_ 658 MTO_HALFDriveStyleSts "HaLF drive style status acknowledgement";
CM_ SG_ 658 MTO_HALFSystemSts "HaLF system status; Faulted = [1]";
CM_ SG_ 658 MotorTorqueOverlayIntActivation "Torques overlay interface activation; Active = [1]";
CM_ SG_ 658 MotorTorqueOverlaySteeringReq "HaLF torque overlay steering request";
CM_ SG_ 729 ConfigSts "LDW sensitivity level";
CM_ SG_ 729 HALF_AHB_On "Auto high beam on request from the HALF ECU";
CM_ SG_ 729 LDW_LEDControlSts "LDW switch LED status";
CM_ SG_ 729 TorqueIntensitySts "LDW Torque Intesity Level";
CM_ SG_ 701 BatPwrUsage ".";
CM_ SG_ 701 BatPwrUsage_V ".";
CM_ SG_ 701 Est_Range "Estimated electric range sent to HMI";
CM_ SG_ 701 HEV_EVT_MD "The system is in EVT mode; Hybrid mode = [0], EV Mode = [1]";
CM_ SG_ 701 HEV_LMP_RQ "HEV service lamp request";
CM_ SG_ 701 R134a_PressSts "Refrigerant pressure (R134a or R1234YF)";
CM_ SG_ 655 CabinPreCondReqStat "Cabin Preconditioning Request Status";
CM_ SG_ 655 ChargingLevel "Charging level and type.";
CM_ SG_ 655 ChargingSysSts "Charging System status";
CM_ SG_ 655 ChrgSysFault "Charging System Fault status";
CM_ SG_ 655 CompStat "comppressor state";
CM_ SG_ 655 DriveReady "Ready to Drive, [1] = Vehicle is allowed to shift out of park or neutral";
CM_ SG_ 655 EstTimeofChrg_Lv1 "Estimated Time to charge on Level 1";
CM_ SG_ 655 EstTimeofChrg_Lv2 "Estimated Time to charge on Level 2";
CM_ SG_ 655 HVBatCntctrStat "HV Battery pack contactor state";
CM_ SG_ 655 HtrCoreInletTemp "Heater Core Inlet Temp";
CM_ SG_ 655 MIL_OnRq_BPCM "MIL Lamp request from BPCM.";
CM_ SG_ 655 PrplsnSysAtv "Propulsion system active, [1] = active";
CM_ SG_ 704 ElecClntHtrInletTemp "Electric Coolant Heater Inlet Temperature";
CM_ SG_ 704 ElecCoolantHtrPwr "Electric Coolant Heater Power";
CM_ SG_ 704 FRfShVlvSts "Front Refrigerant Shutoff Valve Status";
CM_ SG_ 704 HTAuxPmpMontrngRPM "High Temp Aux Pump RPM monitoring active";
CM_ SG_ 704 HTAuxPmpRPMAct "High Temp Aux Pump Status";
CM_ SG_ 704 HTCabVlvPosn "High Temp Cabin Valve position";
CM_ SG_ 704 HTShtOffVlvReq "High temp shut off valve request; [0] = Open, [1] = Closed";
CM_ SG_ 704 HVBatCritCondT "High Voltage Battery Temperature Critical Condition, [1] = True";
CM_ SG_ 704 HVBat_CoolantLvlLo "Battery coolant level low";
CM_ SG_ 654 HCPCoachDisp "Percentage output acceleration & deceleration to support Efficiency Coaching HMI";
CM_ SG_ 654 HCPCoachDispV "Acceleration & deceleration to support Efficiency Coaching validtiy, 0 = Valid, 1 = Invalid";
CM_ SG_ 654 HCPOutputPwr "Percentage output power from HCP for HMI";
CM_ SG_ 654 HCPOutputPwrV "Percentage output power from HCP for HMI validity, 0 = Valid, 1 = Invalid";
CM_ SG_ 654 HCPPopUpMessage1 "Vehicle speed may be limited; True = [1]";
CM_ SG_ 654 HCPPopUpMessage2 "Plug in vehicle to keep battery warm; True = [1]";
CM_ SG_ 654 HCPPopUpMessage3 "Remote start canceled - hv battery temperature; True = [1]";
CM_ SG_ 654 HCPPopUpMessage4 "Turn on vehicle to use climate controls; True = [1]";
CM_ SG_ 654 HCPPopUpMessage5 "Please check plug status before driving; True = [1]";
CM_ SG_ 654 HCPPopUpMessage6 "There may be a problem with the charging unit; True = [1]";
CM_ SG_ 654 HCPPopUpMessage7 "Please leave key in run - battery conditioning needed; True = [1]";
CM_ SG_ 654 HCPPopUpMessage9 "Stop safely. Vehicle will shut off soon; True = [1]";
CM_ SG_ 654 HybSysEmsMlfAtv "Emissions Related Malfunction Active";
CM_ SG_ 654 MIL_OnRq_HCP "MIL on request from the HCP";
CM_ SG_ 878 BatPwrUsageDisp "Battery power usage for HMI, in KW";
CM_ SG_ 878 BatPwrUsageDisp_V "Validity bit for signal BatPwrUsageDisp, 0=Valid";
CM_ SG_ 878 EngPwrUsageDisp "Engine power usage for HMI, in KW";
CM_ SG_ 878 EngPwrUsageDisp_V "Validity bit for signal EngPwrUsageDisp, 0=Valid";
CM_ SG_ 878 HVACPwrUsageDisp "HVAC power usage for HMI, in KW";
CM_ SG_ 878 HVACPwrUsageDisp_V "Validity bit for signal HVACPwrUsageDisp, 0=Valid";
CM_ SG_ 878 HVBatSOCV_HCP "High voltage battery state of charge validity: invalid = [1]";
CM_ SG_ 878 HVBatSOC_HCP "High voltage battery state of charge";
CM_ SG_ 878 MtrPwrUsageDisp "Motor power usage for HMI, in KW";
CM_ SG_ 878 MtrPwrUsageDisp_V "Validity bit for signal MtrPwrUsageDisp, 0=Valid";
CM_ SG_ 291 AHH_Apply_Release_Request "AHH apply/release request";
CM_ SG_ 291 AHH_ModifyAccel_Req "AHH modify accel request; True = [1]";
CM_ SG_ 291 CRC_123h "CRC-checksum byte 1 to 7 according to SAE J1850";
CM_ SG_ 291 MC_123h "Message counter";
CM_ SG_ 291 M_MAX_AXLE "Maximum axle torque";
CM_ SG_ 291 M_MIN_AXLE "Minimum axle torque";
CM_ SG_ 291 M_STA_AXLE "Static axle torque";
CM_ SG_ 560 AC_PT_Demand "Maximum A/C demand to powertrain";
CM_ SG_ 560 AC_RQ "A/C clutch request; [1] = A/C Clutch requested; 0 = A/C Clutch not requested";
CM_ SG_ 560 AC_SEL "Customer has selected A/C; [1] = A/C selected; 0 = A/C not selected";
CM_ SG_ 560 DEFROST_SEL "Defrost select switch";
CM_ SG_ 560 EVAP_TEMP "AC evaporator temperature";
CM_ SG_ 560 EVAP_TEMP_P1C "AC evap temp point one C";
CM_ SG_ 560 EvapTempTar "Evaporator temperature target";
CM_ SG_ 832 Est_Range_Disp "Estimated electric range for display";
CM_ SG_ 832 VehSpdDisp "Vehicle speed - displayed";
CM_ SG_ 832 VehSpd_MPH "Vehicle speed signal is in miles per hour format";
CM_ SG_ 784 AvgFuelLvl "Average filtered fuel level in liters";
CM_ SG_ 784 FuelLvlLow "Fuel level low";
CM_ SG_ 784 ODO "Odometer";
CM_ SG_ 784 OilChgRst "Oil change reminder reset request";
CM_ SG_ 784 PTS_MODE_SELECTION "Park assist maneuver selection for PTS";
CM_ SG_ 784 SBR_MuteRq "Seatbelt reminder audio mute request; Mute = [1]";
CM_ SG_ 784 SRS_LMP_STAT "Airbag indicator lamp status";
CM_ SG_ 882 CapacityUnit "Fuel capacity units";
CM_ SG_ 882 ConsumptionUnit "Fuel consumption units";
CM_ SG_ 882 DistanceUnit "Distance (odometer) units; Miles = [1]";
CM_ SG_ 882 Early_Fuel_TeenKey "Teen Key Early fuel warning response, Active = [1]";
CM_ SG_ 882 Fuel_Popup_TeenKey "Teen Key Fuel Popup setting response, Active = [1]";
CM_ SG_ 882 LANG_C "Language preference (5 bit)";
CM_ SG_ 882 PowerUnit "Power units";
CM_ SG_ 882 PressureUnit "Pressure units";
CM_ SG_ 882 RDY_DRV_STAT_CSO "Ready to drive popup status enable/disable; Disabled = [1]";
CM_ SG_ 882 SpeedUnit "Speed (speedometer) units; Miles = [1]";
CM_ SG_ 882 TemperatureUnit "Temperature units; Farenheit = [1]";
CM_ SG_ 882 TorqueUnit "Torque units; Foot Pounds (ft-lb) = [1]";
CM_ SG_ 782 Gas_Range "Gas range or DTE";
CM_ SG_ 782 Total_Range "Total range or DTE";
CM_ SG_ 938 A_EV_Kilometers "Trip A EV distance in kilometers";
CM_ SG_ 938 A_EV_Miles "Trip A EV distance in US miles";
CM_ SG_ 938 A_MPG "Trip A Combined fuel economy in US MPG";
CM_ SG_ 939 A_Hybrid_Kilometers "Trip A hybrid distance in kilometers";
CM_ SG_ 939 A_Hybrid_Miles "Trip A hybrid distance in US miles";
CM_ SG_ 939 A_KMpL "Trip A Combined fuel economy in Km/L";
CM_ SG_ 940 A_Total_Dist_Kilometers "Trip A total distance in kilometers";
CM_ SG_ 940 A_Total_Dist_Miles "Trip A total distance in US miles";
CM_ SG_ 941 B_EV_Kilometers "Trip B EV distance in kilometers";
CM_ SG_ 941 B_EV_Miles "Trip B EV distance in US miles";
CM_ SG_ 941 B_MPG "Trip B Combined fuel economy in US MPG";
CM_ SG_ 942 B_Hybrid_Kilometers "Trip B hybrid distance in kilometers";
CM_ SG_ 942 B_Hybrid_Miles "Trip B hybrid distance in US miles";
CM_ SG_ 942 B_KMpL "Trip B Combined fuel economy in Km/L";
BA_DEF_ BO_  "App-Botschaft" ENUM  "nein","ja";
BA_DEF_ BO_  "CanMsgMinLen" INT 0 8;
BA_DEF_ BO_  "DiagRequest" ENUM  "nein","ja";
BA_DEF_ BO_  "DiagResponse" ENUM  "nein","ja";
BA_DEF_ BO_  "DiagState" ENUM  "nein","ja";
BA_DEF_ BO_  "GenMsgCycleTime" INT 0 65535;
BA_DEF_ BO_  "GenMsgCycleTimeActive" INT 0 65535;
BA_DEF_ BO_  "GenMsgDelayTime" INT 0 65535;
BA_DEF_ BO_  "GenMsgNrOfRepetitions" INT 0 65535;
BA_DEF_ BO_  "GenMsgSendType" ENUM  "cyclicX","spontanX","cyclicIfActiveX","spontanWithDelay","cyclicAndSpontanX","cyclicAndSpontanWithDelay","spontanWithRepitition","cyclicIfActiveAndSpontanWD","cyclicIfActiveFast","cyclicWithRepeatOnDemand","none";
BA_DEF_ BO_  "GenMsgStartDelayTime" INT 0 65535;
BA_DEF_ BO_  "GenMsgStartValue" STRING ;
BA_DEF_ BO_  "NWM-Botschaft" ENUM  "nein","ja";
BA_DEF_ BO_  "TpTxIndex" INT 0 99;
BA_DEF_ SG_  "FlexKomComment" STRING ;
BA_DEF_ SG_  "FlexKomIsMotorola" ENUM  "nein","ja";
BA_DEF_ SG_  "FlexKomSID" INT 0 2147483647;
BA_DEF_ SG_  "FlexKomSigLaenge" INT 0 64;
BA_DEF_ SG_  "FlexKomSigName" STRING ;
BA_DEF_ SG_  "FlexKomSigStartPos" INT 0 63;
BA_DEF_ SG_  "FlexKomSigStartValue" STRING ;
BA_DEF_ SG_  "GenSigCycleTime" INT 0 65535;
BA_DEF_ SG_  "GenSigCycleTimeActive" INT 0 65535;
BA_DEF_ SG_  "GenSigSendType" ENUM  "cyclicX","spontanX","cyclicIfActiveX","spontanWithDelay","cyclicAndSpontanX","cyclicAndSpontanWithDelay","spontanWithRepitition","cyclicIfActiveAndSpontanWD","cyclicIfActiveFast","cyclicWithRepeatOnDemand","none";
BA_DEF_ SG_  "GenSigSNA" STRING ;
BA_DEF_ SG_  "GenSigStartValue" HEX 0 2147483648;
BA_DEF_ SG_  "GenSigTimeout_CBC" INT 0 65535;
BA_DEF_ SG_  "GenSigTimeout_EPS" INT 0 65535;
BA_DEF_ SG_  "GenSigTimeout_ESC" INT 0 65535;
BA_DEF_ SG_  "GenSigTimeout_ESL" INT 0 65535;
BA_DEF_ SG_  "GenSigTimeout_RHSC2" INT 0 65535;
BA_DEF_ SG_  "GenSigTimeout_ETM" INT 0 65535;
BA_DEF_ SG_  "GenSigTimeout_HaLF" INT 0 65535;
BA_DEF_ SG_  "GenSigTimeout_IC" INT 0 65535;
BA_DEF_ SG_  "GenSigTimeout_OCM" INT 0 65535;
BA_DEF_ SG_  "GenSigTimeout_ORC" INT 0 65535;
BA_DEF_ SG_  "GenSigTimeout_PTS" INT 0 65535;
BA_DEF_ SG_  "GenSigTimeout_RF_HUB" INT 0 65535;
BA_DEF_ SG_  "GenSigTimeout_SCCM" INT 0 65535;
BA_DEF_ SG_  "RID" STRING ;
BA_DEF_DEF_  "App-Botschaft" "nein";
BA_DEF_DEF_  "CanMsgMinLen" 0;
BA_DEF_DEF_  "DiagRequest" "nein";
BA_DEF_DEF_  "DiagResponse" "nein";
BA_DEF_DEF_  "DiagState" "nein";
BA_DEF_DEF_  "GenMsgCycleTime" 0;
BA_DEF_DEF_  "GenMsgCycleTimeActive" 0;
BA_DEF_DEF_  "GenMsgDelayTime" 0;
BA_DEF_DEF_  "GenMsgNrOfRepetitions" 0;
BA_DEF_DEF_  "GenMsgSendType" "cyclicX";
BA_DEF_DEF_  "GenMsgStartDelayTime" 0;
BA_DEF_DEF_  "GenMsgStartValue" "";
BA_DEF_DEF_  "NWM-Botschaft" "nein";
BA_DEF_DEF_  "TpTxIndex" 0;
BA_DEF_DEF_  "FlexKomComment" "";
BA_DEF_DEF_  "FlexKomIsMotorola" "nein";
BA_DEF_DEF_  "FlexKomSID" 0;
BA_DEF_DEF_  "FlexKomSigLaenge" 0;
BA_DEF_DEF_  "FlexKomSigName" "";
BA_DEF_DEF_  "FlexKomSigStartPos" 0;
BA_DEF_DEF_  "FlexKomSigStartValue" "";
BA_DEF_DEF_  "GenSigCycleTime" 0;
BA_DEF_DEF_  "GenSigCycleTimeActive" 0;
BA_DEF_DEF_  "GenSigSendType" "cyclicX";
BA_DEF_DEF_  "GenSigSNA" "";
BA_DEF_DEF_  "GenSigStartValue" 0;
BA_DEF_DEF_  "GenSigTimeout_CBC" 0;
BA_DEF_DEF_  "GenSigTimeout_EPS" 0;
BA_DEF_DEF_  "GenSigTimeout_ESC" 0;
BA_DEF_DEF_  "GenSigTimeout_ESL" 0;
BA_DEF_DEF_  "GenSigTimeout_RHSC2" 0;
BA_DEF_DEF_  "GenSigTimeout_ETM" 0;
BA_DEF_DEF_  "GenSigTimeout_HaLF" 0;
BA_DEF_DEF_  "GenSigTimeout_IC" 0;
BA_DEF_DEF_  "GenSigTimeout_OCM" 0;
BA_DEF_DEF_  "GenSigTimeout_ORC" 0;
BA_DEF_DEF_  "GenSigTimeout_PTS" 0;
BA_DEF_DEF_  "GenSigTimeout_RF_HUB" 0;
BA_DEF_DEF_  "GenSigTimeout_SCCM" 0;
BA_DEF_DEF_  "RID" "";
BA_ "GenMsgCycleTime" BO_ 983 2000;
BA_ "GenMsgDelayTime" BO_ 983 20;
BA_ "GenMsgNrOfRepetitions" BO_ 983 2;
BA_ "GenMsgSendType" BO_ 983 5;
BA_ "GenMsgStartDelayTime" BO_ 983 100;
BA_ "GenMsgStartValue" BO_ 983 "0300000000000000h";
BA_ "GenMsgCycleTime" BO_ 982 2000;
BA_ "GenMsgDelayTime" BO_ 982 20;
BA_ "GenMsgNrOfRepetitions" BO_ 982 2;
BA_ "GenMsgStartDelayTime" BO_ 982 130;
BA_ "GenMsgStartValue" BO_ 982 "0300000000000000h";
BA_ "GenMsgCycleTime" BO_ 981 2000;
BA_ "GenMsgDelayTime" BO_ 981 20;
BA_ "GenMsgNrOfRepetitions" BO_ 981 2;
BA_ "GenMsgSendType" BO_ 981 5;
BA_ "GenMsgStartDelayTime" BO_ 981 120;
BA_ "GenMsgStartValue" BO_ 981 "0300000000000000h";
BA_ "GenMsgCycleTime" BO_ 980 2000;
BA_ "GenMsgDelayTime" BO_ 980 20;
BA_ "GenMsgNrOfRepetitions" BO_ 980 2;
BA_ "GenMsgStartDelayTime" BO_ 980 130;
BA_ "GenMsgStartValue" BO_ 980 "0300000000000000h";
BA_ "GenMsgCycleTime" BO_ 979 2000;
BA_ "GenMsgDelayTime" BO_ 979 20;
BA_ "GenMsgNrOfRepetitions" BO_ 979 2;
BA_ "GenMsgStartDelayTime" BO_ 979 130;
BA_ "GenMsgStartValue" BO_ 979 "0300000000000000h";
BA_ "GenMsgCycleTime" BO_ 706 2000;
BA_ "GenMsgDelayTime" BO_ 706 20;
BA_ "GenMsgNrOfRepetitions" BO_ 706 2;
BA_ "GenMsgSendType" BO_ 706 5;
BA_ "GenMsgStartValue" BO_ 706 "0300000000000000h";
BA_ "GenMsgCycleTime" BO_ 709 2000;
BA_ "GenMsgDelayTime" BO_ 709 20;
BA_ "GenMsgNrOfRepetitions" BO_ 709 2;
BA_ "GenMsgSendType" BO_ 709 5;
BA_ "GenMsgStartValue" BO_ 709 "0300000000000000h";
BA_ "GenMsgCycleTime" BO_ 710 2000;
BA_ "GenMsgDelayTime" BO_ 710 20;
BA_ "GenMsgNrOfRepetitions" BO_ 710 2;
BA_ "GenMsgSendType" BO_ 710 5;
BA_ "GenMsgStartValue" BO_ 710 "0300000000000000h";
BA_ "GenMsgCycleTime" BO_ 1009 2000;
BA_ "GenMsgDelayTime" BO_ 1009 20;
BA_ "GenMsgNrOfRepetitions" BO_ 1009 2;
BA_ "GenMsgStartDelayTime" BO_ 1009 150;
BA_ "GenMsgStartValue" BO_ 1009 "0300000000000000h";
BA_ "GenMsgCycleTime" BO_ 1010 2000;
BA_ "GenMsgDelayTime" BO_ 1010 20;
BA_ "GenMsgNrOfRepetitions" BO_ 1010 2;
BA_ "GenMsgSendType" BO_ 1010 5;
BA_ "GenMsgStartDelayTime" BO_ 1010 30;
BA_ "GenMsgStartValue" BO_ 1010 "0300000000000000h";
BA_ "GenMsgCycleTime" BO_ 1011 2000;
BA_ "GenMsgDelayTime" BO_ 1011 20;
BA_ "GenMsgNrOfRepetitions" BO_ 1011 2;
BA_ "GenMsgSendType" BO_ 1011 5;
BA_ "GenMsgStartDelayTime" BO_ 1011 40;
BA_ "GenMsgStartValue" BO_ 1011 "0300000000000000h";
BA_ "GenMsgCycleTime" BO_ 1012 2000;
BA_ "GenMsgDelayTime" BO_ 1012 20;
BA_ "GenMsgNrOfRepetitions" BO_ 1012 2;
BA_ "GenMsgSendType" BO_ 1012 5;
BA_ "GenMsgStartDelayTime" BO_ 1012 50;
BA_ "GenMsgStartValue" BO_ 1012 "0300000000000000h";
BA_ "GenMsgCycleTime" BO_ 1013 2000;
BA_ "GenMsgDelayTime" BO_ 1013 20;
BA_ "GenMsgNrOfRepetitions" BO_ 1013 2;
BA_ "GenMsgSendType" BO_ 1013 5;
BA_ "GenMsgStartDelayTime" BO_ 1013 60;
BA_ "GenMsgStartValue" BO_ 1013 "0300000000000000h";
BA_ "GenMsgCycleTime" BO_ 1014 2000;
BA_ "GenMsgDelayTime" BO_ 1014 20;
BA_ "GenMsgNrOfRepetitions" BO_ 1014 2;
BA_ "GenMsgStartDelayTime" BO_ 1014 150;
BA_ "GenMsgStartValue" BO_ 1014 "0300000000000000h";
BA_ "GenMsgCycleTime" BO_ 1015 2000;
BA_ "GenMsgDelayTime" BO_ 1015 20;
BA_ "GenMsgNrOfRepetitions" BO_ 1015 2;
BA_ "GenMsgStartDelayTime" BO_ 1015 80;
BA_ "GenMsgStartValue" BO_ 1015 "0300000000000000h";
BA_ "GenMsgCycleTime" BO_ 984 2000;
BA_ "GenMsgDelayTime" BO_ 984 20;
BA_ "GenMsgNrOfRepetitions" BO_ 984 2;
BA_ "GenMsgStartDelayTime" BO_ 984 90;
BA_ "GenMsgStartValue" BO_ 984 "0300000000000000h";
BA_ "GenMsgCycleTime" BO_ 908 1000;
BA_ "GenMsgDelayTime" BO_ 908 20;
BA_ "GenMsgNrOfRepetitions" BO_ 908 2;
BA_ "GenMsgStartValue" BO_ 908 "FFFFFFFFFFFFFFFFh";
BA_ "GenMsgCycleTime" BO_ 974 1000;
BA_ "GenMsgDelayTime" BO_ 974 20;
BA_ "GenMsgNrOfRepetitions" BO_ 974 2;
BA_ "GenMsgSendType" BO_ 974 5;
BA_ "GenMsgStartDelayTime" BO_ 974 70;
BA_ "GenMsgStartValue" BO_ 974 "7F0F7F7F7Fh";
BA_ "GenMsgCycleTime" BO_ 901 1000;
BA_ "GenMsgDelayTime" BO_ 901 20;
BA_ "GenMsgNrOfRepetitions" BO_ 901 2;
BA_ "GenMsgStartDelayTime" BO_ 901 90;
BA_ "GenMsgStartValue" BO_ 901 "FFFFFFFF00000000h";
BA_ "GenMsgCycleTime" BO_ 639 1000;
BA_ "GenMsgDelayTime" BO_ 639 20;
BA_ "GenMsgNrOfRepetitions" BO_ 639 2;
BA_ "GenMsgStartDelayTime" BO_ 639 90;
BA_ "GenMsgStartValue" BO_ 639 "FFFFFFFF00000000h";
BA_ "GenMsgCycleTime" BO_ 816 1000;
BA_ "GenMsgDelayTime" BO_ 816 20;
BA_ "GenMsgNrOfRepetitions" BO_ 816 2;
BA_ "GenMsgSendType" BO_ 816 5;
BA_ "GenMsgStartDelayTime" BO_ 816 80;
BA_ "GenMsgStartValue" BO_ 816 "3000071EC0FF8000h";
BA_ "GenMsgCycleTime" BO_ 853 1000;
BA_ "GenMsgDelayTime" BO_ 853 20;
BA_ "GenMsgNrOfRepetitions" BO_ 853 2;
BA_ "GenMsgSendType" BO_ 853 5;
BA_ "GenMsgStartDelayTime" BO_ 853 100;
BA_ "GenMsgStartValue" BO_ 853 "F0FF0300000C00FFh";
BA_ "GenMsgCycleTime" BO_ 854 1000;
BA_ "GenMsgDelayTime" BO_ 854 20;
BA_ "GenMsgNrOfRepetitions" BO_ 854 2;
BA_ "GenMsgSendType" BO_ 854 5;
BA_ "GenMsgStartDelayTime" BO_ 854 100;
BA_ "GenMsgStartValue" BO_ 854 "F0FF0300000C00FFh";
BA_ "GenMsgCycleTime" BO_ 799 1000;
BA_ "GenMsgDelayTime" BO_ 799 20;
BA_ "GenMsgNrOfRepetitions" BO_ 799 2;
BA_ "GenMsgSendType" BO_ 799 5;
BA_ "GenMsgStartDelayTime" BO_ 799 130;
BA_ "GenMsgStartValue" BO_ 799 "07FF07FF00000004h";
BA_ "GenMsgCycleTime" BO_ 798 1000;
BA_ "GenMsgDelayTime" BO_ 798 20;
BA_ "GenMsgNrOfRepetitions" BO_ 798 2;
BA_ "GenMsgSendType" BO_ 798 5;
BA_ "GenMsgStartDelayTime" BO_ 798 130;
BA_ "GenMsgStartValue" BO_ 798 "07FF07FF00000004h";
BA_ "GenMsgCycleTime" BO_ 817 1000;
BA_ "GenMsgDelayTime" BO_ 817 20;
BA_ "GenMsgNrOfRepetitions" BO_ 817 2;
BA_ "GenMsgSendType" BO_ 817 5;
BA_ "GenMsgStartValue" BO_ 817 "00000000001E0000h";
BA_ "GenMsgCycleTime" BO_ 579 1000;
BA_ "GenMsgDelayTime" BO_ 579 20;
BA_ "GenMsgNrOfRepetitions" BO_ 579 2;
BA_ "GenMsgSendType" BO_ 579 5;
BA_ "GenMsgStartValue" BO_ 579 "000000007F7F7F7Fh";
BA_ "GenMsgCycleTime" BO_ 705 1000;
BA_ "GenMsgDelayTime" BO_ 705 20;
BA_ "GenMsgNrOfRepetitions" BO_ 705 2;
BA_ "GenMsgSendType" BO_ 705 5;
BA_ "GenMsgStartValue" BO_ 705 "0000FFFFFF7F7F7Fh";
BA_ "GenMsgCycleTime" BO_ 678 250;
BA_ "GenMsgDelayTime" BO_ 678 20;
BA_ "GenMsgNrOfRepetitions" BO_ 678 2;
BA_ "GenMsgStartValue" BO_ 678 "0000000000000000h";
BA_ "GenMsgCycleTime" BO_ 658 10;
BA_ "GenMsgDelayTime" BO_ 658 20;
BA_ "GenMsgNrOfRepetitions" BO_ 658 2;
BA_ "GenMsgStartValue" BO_ 658 "0000000000FFh";
BA_ "GenMsgCycleTime" BO_ 729 100;
BA_ "GenMsgDelayTime" BO_ 729 20;
BA_ "GenMsgNrOfRepetitions" BO_ 729 2;
BA_ "GenMsgSendType" BO_ 729 5;
BA_ "GenMsgStartValue" BO_ 729 "0000000020h";
BA_ "GenMsgCycleTime" BO_ 701 100;
BA_ "GenMsgDelayTime" BO_ 701 20;
BA_ "GenMsgNrOfRepetitions" BO_ 701 2;
BA_ "GenMsgStartValue" BO_ 701 "7BFF0B0000FF01FFh";
BA_ "GenMsgCycleTime" BO_ 655 1000;
BA_ "GenMsgDelayTime" BO_ 655 20;
BA_ "GenMsgNrOfRepetitions" BO_ 655 2;
BA_ "GenMsgSendType" BO_ 655 5;
BA_ "GenMsgStartValue" BO_ 655 "0000000000000000h";
BA_ "GenMsgCycleTime" BO_ 704 1000;
BA_ "GenMsgDelayTime" BO_ 704 20;
BA_ "GenMsgNrOfRepetitions" BO_ 704 2;
BA_ "GenMsgSendType" BO_ 704 5;
BA_ "GenMsgStartValue" BO_ 704 "00001E0000000000h";
BA_ "GenMsgCycleTime" BO_ 654 100;
BA_ "GenMsgDelayTime" BO_ 654 20;
BA_ "GenMsgNrOfRepetitions" BO_ 654 2;
BA_ "GenMsgStartValue" BO_ 654 "0000000064640000h";
BA_ "GenMsgCycleTime" BO_ 878 500;
BA_ "GenMsgDelayTime" BO_ 878 20;
BA_ "GenMsgNrOfRepetitions" BO_ 878 2;
BA_ "GenMsgStartValue" BO_ 878 "0000000000000000h";
BA_ "GenMsgCycleTime" BO_ 291 10;
BA_ "GenMsgDelayTime" BO_ 291 20;
BA_ "GenMsgNrOfRepetitions" BO_ 291 2;
BA_ "GenMsgStartValue" BO_ 291 "00000000000000FFh";
BA_ "GenMsgCycleTime" BO_ 560 500;
BA_ "GenMsgDelayTime" BO_ 560 20;
BA_ "GenMsgNrOfRepetitions" BO_ 560 2;
BA_ "GenMsgSendType" BO_ 560 5;
BA_ "GenMsgStartValue" BO_ 560 "08000000h";
BA_ "GenMsgCycleTime" BO_ 832 500;
BA_ "GenMsgDelayTime" BO_ 832 20;
BA_ "GenMsgNrOfRepetitions" BO_ 832 2;
BA_ "GenMsgStartValue" BO_ 832 "FFFF0FFF0000FFFFh";
BA_ "GenMsgCycleTime" BO_ 784 1000;
BA_ "GenMsgDelayTime" BO_ 784 20;
BA_ "GenMsgNrOfRepetitions" BO_ 784 2;
BA_ "GenMsgSendType" BO_ 784 5;
BA_ "GenMsgStartValue" BO_ 784 "01FF0000FFFFFF07h";
BA_ "GenMsgCycleTime" BO_ 882 1000;
BA_ "GenMsgDelayTime" BO_ 882 20;
BA_ "GenMsgNrOfRepetitions" BO_ 882 2;
BA_ "GenMsgSendType" BO_ 882 5;
BA_ "GenMsgStartValue" BO_ 882 "00F8FCF001FE01FEh";
BA_ "GenMsgCycleTime" BO_ 782 1000;
BA_ "GenMsgDelayTime" BO_ 782 20;
BA_ "GenMsgNrOfRepetitions" BO_ 782 2;
BA_ "GenMsgSendType" BO_ 782 5;
BA_ "GenMsgStartValue" BO_ 782 "03FF07FF00000000h";
BA_ "GenMsgCycleTime" BO_ 938 1000;
BA_ "GenMsgDelayTime" BO_ 938 20;
BA_ "GenMsgNrOfRepetitions" BO_ 938 2;
BA_ "GenMsgStartValue" BO_ 938 "0000000000000000h";
BA_ "GenMsgCycleTime" BO_ 939 1000;
BA_ "GenMsgDelayTime" BO_ 939 20;
BA_ "GenMsgNrOfRepetitions" BO_ 939 2;
BA_ "GenMsgStartDelayTime" BO_ 939 50;
BA_ "GenMsgStartValue" BO_ 939 "0000000000000000h";
BA_ "GenMsgCycleTime" BO_ 940 1000;
BA_ "GenMsgDelayTime" BO_ 940 20;
BA_ "GenMsgNrOfRepetitions" BO_ 940 2;
BA_ "GenMsgStartDelayTime" BO_ 940 100;
BA_ "GenMsgStartValue" BO_ 940 "0000000000000000h";
BA_ "GenMsgCycleTime" BO_ 941 1000;
BA_ "GenMsgDelayTime" BO_ 941 20;
BA_ "GenMsgNrOfRepetitions" BO_ 941 2;
BA_ "GenMsgStartDelayTime" BO_ 941 150;
BA_ "GenMsgStartValue" BO_ 941 "0000000000000000h";
BA_ "GenMsgCycleTime" BO_ 942 1000;
BA_ "GenMsgDelayTime" BO_ 942 20;
BA_ "GenMsgNrOfRepetitions" BO_ 942 2;
BA_ "GenMsgStartDelayTime" BO_ 942 200;
BA_ "GenMsgStartValue" BO_ 942 "0000000000000000h";
BA_ "FlexKomComment" SG_ 983 EC_Cluster3A "Instrument cluster ecu configuration 3";
BA_ "FlexKomIsMotorola" SG_ 983 EC_Cluster3A 1;
BA_ "FlexKomSID" SG_ 983 EC_Cluster3A 1307;
BA_ "FlexKomSigLaenge" SG_ 983 EC_Cluster3A 32;
BA_ "FlexKomSigName" SG_ 983 EC_Cluster3A "EC_Cluster3";
BA_ "FlexKomSigStartPos" SG_ 983 EC_Cluster3A 7;
BA_ "FlexKomSigStartValue" SG_ 983 EC_Cluster3A "00000000h";
BA_ "GenSigCycleTime" SG_ 983 EC_Cluster3A 2000;
BA_ "GenSigSendType" SG_ 983 EC_Cluster3A 5;
BA_ "GenSigSNA" SG_ 983 EC_Cluster3A "0h";
BA_ "GenSigTimeout_IC" SG_ 983 EC_Cluster3A 21000;
BA_ "FlexKomComment" SG_ 983 EC_Cluster3B "Instrument cluster ecu configuration 3";
BA_ "FlexKomIsMotorola" SG_ 983 EC_Cluster3B 1;
BA_ "FlexKomSID" SG_ 983 EC_Cluster3B 1307;
BA_ "FlexKomSigLaenge" SG_ 983 EC_Cluster3B 32;
BA_ "FlexKomSigName" SG_ 983 EC_Cluster3B "EC_Cluster3";
BA_ "FlexKomSigStartPos" SG_ 983 EC_Cluster3B 7;
BA_ "FlexKomSigStartValue" SG_ 983 EC_Cluster3B "00000000h";
BA_ "GenSigCycleTime" SG_ 983 EC_Cluster3B 2000;
BA_ "GenSigSendType" SG_ 983 EC_Cluster3B 5;
BA_ "GenSigSNA" SG_ 983 EC_Cluster3B "0h";
BA_ "GenSigTimeout_IC" SG_ 983 EC_Cluster3B 21000;
BA_ "FlexKomComment" SG_ 983 EC_Cluster4 "Instrument cluster ecu configuration 4";
BA_ "FlexKomIsMotorola" SG_ 983 EC_Cluster4 1;
BA_ "FlexKomSID" SG_ 983 EC_Cluster4 1306;
BA_ "FlexKomSigLaenge" SG_ 983 EC_Cluster4 32;
BA_ "FlexKomSigName" SG_ 983 EC_Cluster4 "EC_Cluster4";
BA_ "FlexKomSigStartPos" SG_ 983 EC_Cluster4 39;
BA_ "FlexKomSigStartValue" SG_ 983 EC_Cluster4 "00000000h";
BA_ "GenSigCycleTime" SG_ 983 EC_Cluster4 2000;
BA_ "GenSigSendType" SG_ 983 EC_Cluster4 5;
BA_ "GenSigSNA" SG_ 983 EC_Cluster4 "0h";
BA_ "GenSigTimeout_IC" SG_ 983 EC_Cluster4 21000;
BA_ "FlexKomComment" SG_ 983 EC_ECUCfg10_Stat "ECU Configuration messages status 10";
BA_ "FlexKomIsMotorola" SG_ 983 EC_ECUCfg10_Stat 1;
BA_ "FlexKomSID" SG_ 983 EC_ECUCfg10_Stat 1303;
BA_ "FlexKomSigLaenge" SG_ 983 EC_ECUCfg10_Stat 2;
BA_ "FlexKomSigName" SG_ 983 EC_ECUCfg10_Stat "EC_ECUCfg10_Stat";
BA_ "FlexKomSigStartPos" SG_ 983 EC_ECUCfg10_Stat 1;
BA_ "FlexKomSigStartValue" SG_ 983 EC_ECUCfg10_Stat "03h";
BA_ "GenSigCycleTime" SG_ 983 EC_ECUCfg10_Stat 2000;
BA_ "GenSigSendType" SG_ 983 EC_ECUCfg10_Stat 5;
BA_ "GenSigSNA" SG_ 983 EC_ECUCfg10_Stat "3h";
BA_ "GenSigStartValue" SG_ 983 EC_ECUCfg10_Stat 3;
BA_ "GenSigTimeout_IC" SG_ 983 EC_ECUCfg10_Stat 21000;
BA_ "FlexKomComment" SG_ 982 EC_CBC10A "CBC ecu configuration 10";
BA_ "FlexKomIsMotorola" SG_ 982 EC_CBC10A 1;
BA_ "FlexKomSID" SG_ 982 EC_CBC10A 1709;
BA_ "FlexKomSigLaenge" SG_ 982 EC_CBC10A 32;
BA_ "FlexKomSigName" SG_ 982 EC_CBC10A "EC_CBC10";
BA_ "FlexKomSigStartPos" SG_ 982 EC_CBC10A 7;
BA_ "FlexKomSigStartValue" SG_ 982 EC_CBC10A "00000000h";
BA_ "GenSigCycleTime" SG_ 982 EC_CBC10A 2000;
BA_ "GenSigSNA" SG_ 982 EC_CBC10A "0h";
BA_ "FlexKomComment" SG_ 982 EC_CBC10B "CBC ecu configuration 10";
BA_ "FlexKomIsMotorola" SG_ 982 EC_CBC10B 1;
BA_ "FlexKomSID" SG_ 982 EC_CBC10B 1709;
BA_ "FlexKomSigLaenge" SG_ 982 EC_CBC10B 32;
BA_ "FlexKomSigName" SG_ 982 EC_CBC10B "EC_CBC10";
BA_ "FlexKomSigStartPos" SG_ 982 EC_CBC10B 7;
BA_ "FlexKomSigStartValue" SG_ 982 EC_CBC10B "00000000h";
BA_ "GenSigCycleTime" SG_ 982 EC_CBC10B 2000;
BA_ "GenSigSNA" SG_ 982 EC_CBC10B "0h";
BA_ "FlexKomComment" SG_ 982 EC_CBC11 "CBC ecu configuration 11";
BA_ "FlexKomIsMotorola" SG_ 982 EC_CBC11 1;
BA_ "FlexKomSID" SG_ 982 EC_CBC11 1710;
BA_ "FlexKomSigLaenge" SG_ 982 EC_CBC11 32;
BA_ "FlexKomSigName" SG_ 982 EC_CBC11 "EC_CBC11";
BA_ "FlexKomSigStartPos" SG_ 982 EC_CBC11 39;
BA_ "FlexKomSigStartValue" SG_ 982 EC_CBC11 "00000000h";
BA_ "GenSigCycleTime" SG_ 982 EC_CBC11 2000;
BA_ "GenSigSNA" SG_ 982 EC_CBC11 "0h";
BA_ "FlexKomComment" SG_ 982 EC_ECUCfg11_Stat "ECU Configuration messages status 11";
BA_ "FlexKomIsMotorola" SG_ 982 EC_ECUCfg11_Stat 1;
BA_ "FlexKomSID" SG_ 982 EC_ECUCfg11_Stat 1708;
BA_ "FlexKomSigLaenge" SG_ 982 EC_ECUCfg11_Stat 2;
BA_ "FlexKomSigName" SG_ 982 EC_ECUCfg11_Stat "EC_ECUCfg11_Stat";
BA_ "FlexKomSigStartPos" SG_ 982 EC_ECUCfg11_Stat 1;
BA_ "FlexKomSigStartValue" SG_ 982 EC_ECUCfg11_Stat "03h";
BA_ "GenSigCycleTime" SG_ 982 EC_ECUCfg11_Stat 2000;
BA_ "GenSigSNA" SG_ 982 EC_ECUCfg11_Stat "3h";
BA_ "GenSigStartValue" SG_ 982 EC_ECUCfg11_Stat 3;
BA_ "FlexKomComment" SG_ 981 EC_Cluster5A "Instrument cluster ecu configuration 5";
BA_ "FlexKomIsMotorola" SG_ 981 EC_Cluster5A 1;
BA_ "FlexKomSID" SG_ 981 EC_Cluster5A 1835;
BA_ "FlexKomSigLaenge" SG_ 981 EC_Cluster5A 64;
BA_ "FlexKomSigName" SG_ 981 EC_Cluster5A "EC_Cluster5";
BA_ "FlexKomSigStartPos" SG_ 981 EC_Cluster5A 7;
BA_ "FlexKomSigStartValue" SG_ 981 EC_Cluster5A "0000000000000000h";
BA_ "GenSigCycleTime" SG_ 981 EC_Cluster5A 2000;
BA_ "GenSigSendType" SG_ 981 EC_Cluster5A 5;
BA_ "GenSigSNA" SG_ 981 EC_Cluster5A "0h";
BA_ "GenSigTimeout_IC" SG_ 981 EC_Cluster5A 21000;
BA_ "GenSigTimeout_RF_HUB" SG_ 981 EC_Cluster5A 21000;
BA_ "FlexKomComment" SG_ 981 EC_Cluster5B "Instrument cluster ecu configuration 5";
BA_ "FlexKomIsMotorola" SG_ 981 EC_Cluster5B 1;
BA_ "FlexKomSID" SG_ 981 EC_Cluster5B 1835;
BA_ "FlexKomSigLaenge" SG_ 981 EC_Cluster5B 64;
BA_ "FlexKomSigName" SG_ 981 EC_Cluster5B "EC_Cluster5";
BA_ "FlexKomSigStartPos" SG_ 981 EC_Cluster5B 7;
BA_ "FlexKomSigStartValue" SG_ 981 EC_Cluster5B "0000000000000000h";
BA_ "GenSigCycleTime" SG_ 981 EC_Cluster5B 2000;
BA_ "GenSigSendType" SG_ 981 EC_Cluster5B 5;
BA_ "GenSigSNA" SG_ 981 EC_Cluster5B "0h";
BA_ "GenSigTimeout_IC" SG_ 981 EC_Cluster5B 21000;
BA_ "GenSigTimeout_RF_HUB" SG_ 981 EC_Cluster5B 21000;
BA_ "FlexKomComment" SG_ 981 EC_Cluster5C "Instrument cluster ecu configuration 5";
BA_ "FlexKomIsMotorola" SG_ 981 EC_Cluster5C 1;
BA_ "FlexKomSID" SG_ 981 EC_Cluster5C 1835;
BA_ "FlexKomSigLaenge" SG_ 981 EC_Cluster5C 64;
BA_ "FlexKomSigName" SG_ 981 EC_Cluster5C "EC_Cluster5";
BA_ "FlexKomSigStartPos" SG_ 981 EC_Cluster5C 7;
BA_ "FlexKomSigStartValue" SG_ 981 EC_Cluster5C "0000000000000000h";
BA_ "GenSigCycleTime" SG_ 981 EC_Cluster5C 2000;
BA_ "GenSigSendType" SG_ 981 EC_Cluster5C 5;
BA_ "GenSigSNA" SG_ 981 EC_Cluster5C "0h";
BA_ "GenSigTimeout_IC" SG_ 981 EC_Cluster5C 21000;
BA_ "GenSigTimeout_RF_HUB" SG_ 981 EC_Cluster5C 21000;
BA_ "FlexKomComment" SG_ 981 EC_ECUCfg12_Stat "ECU Configuration messages status 12";
BA_ "FlexKomIsMotorola" SG_ 981 EC_ECUCfg12_Stat 1;
BA_ "FlexKomSID" SG_ 981 EC_ECUCfg12_Stat 1834;
BA_ "FlexKomSigLaenge" SG_ 981 EC_ECUCfg12_Stat 2;
BA_ "FlexKomSigName" SG_ 981 EC_ECUCfg12_Stat "EC_ECUCfg12_Stat";
BA_ "FlexKomSigStartPos" SG_ 981 EC_ECUCfg12_Stat 1;
BA_ "FlexKomSigStartValue" SG_ 981 EC_ECUCfg12_Stat "03h";
BA_ "GenSigCycleTime" SG_ 981 EC_ECUCfg12_Stat 2000;
BA_ "GenSigSendType" SG_ 981 EC_ECUCfg12_Stat 5;
BA_ "GenSigSNA" SG_ 981 EC_ECUCfg12_Stat "3h";
BA_ "GenSigStartValue" SG_ 981 EC_ECUCfg12_Stat 3;
BA_ "GenSigTimeout_IC" SG_ 981 EC_ECUCfg12_Stat 21000;
BA_ "GenSigTimeout_RF_HUB" SG_ 981 EC_ECUCfg12_Stat 21000;
BA_ "FlexKomComment" SG_ 980 EC_CBC13A "CBC ecu configuration 13";
BA_ "FlexKomIsMotorola" SG_ 980 EC_CBC13A 1;
BA_ "FlexKomSID" SG_ 980 EC_CBC13A 1990;
BA_ "FlexKomSigLaenge" SG_ 980 EC_CBC13A 64;
BA_ "FlexKomSigName" SG_ 980 EC_CBC13A "EC_CBC13";
BA_ "FlexKomSigStartPos" SG_ 980 EC_CBC13A 7;
BA_ "FlexKomSigStartValue" SG_ 980 EC_CBC13A "0000000000000000h";
BA_ "GenSigCycleTime" SG_ 980 EC_CBC13A 2000;
BA_ "GenSigSNA" SG_ 980 EC_CBC13A "0h";
BA_ "FlexKomComment" SG_ 980 EC_CBC13B "CBC ecu configuration 13";
BA_ "FlexKomIsMotorola" SG_ 980 EC_CBC13B 1;
BA_ "FlexKomSID" SG_ 980 EC_CBC13B 1990;
BA_ "FlexKomSigLaenge" SG_ 980 EC_CBC13B 64;
BA_ "FlexKomSigName" SG_ 980 EC_CBC13B "EC_CBC13";
BA_ "FlexKomSigStartPos" SG_ 980 EC_CBC13B 7;
BA_ "FlexKomSigStartValue" SG_ 980 EC_CBC13B "0000000000000000h";
BA_ "GenSigCycleTime" SG_ 980 EC_CBC13B 2000;
BA_ "GenSigSNA" SG_ 980 EC_CBC13B "0h";
BA_ "FlexKomComment" SG_ 980 EC_ECUCfg13_Stat "ECU Configuration messages status 13";
BA_ "FlexKomIsMotorola" SG_ 980 EC_ECUCfg13_Stat 1;
BA_ "FlexKomSID" SG_ 980 EC_ECUCfg13_Stat 1868;
BA_ "FlexKomSigLaenge" SG_ 980 EC_ECUCfg13_Stat 2;
BA_ "FlexKomSigName" SG_ 980 EC_ECUCfg13_Stat "EC_ECUCfg13_Stat";
BA_ "FlexKomSigStartPos" SG_ 980 EC_ECUCfg13_Stat 1;
BA_ "FlexKomSigStartValue" SG_ 980 EC_ECUCfg13_Stat "03h";
BA_ "GenSigCycleTime" SG_ 980 EC_ECUCfg13_Stat 2000;
BA_ "GenSigSNA" SG_ 980 EC_ECUCfg13_Stat "3h";
BA_ "GenSigStartValue" SG_ 980 EC_ECUCfg13_Stat 3;
BA_ "FlexKomComment" SG_ 979 EC_CBC14A "CBC ecu configuration 14";
BA_ "FlexKomIsMotorola" SG_ 979 EC_CBC14A 1;
BA_ "FlexKomSID" SG_ 979 EC_CBC14A 1951;
BA_ "FlexKomSigLaenge" SG_ 979 EC_CBC14A 64;
BA_ "FlexKomSigName" SG_ 979 EC_CBC14A "EC_CBC14";
BA_ "FlexKomSigStartPos" SG_ 979 EC_CBC14A 7;
BA_ "FlexKomSigStartValue" SG_ 979 EC_CBC14A "0000000000000000h";
BA_ "GenSigCycleTime" SG_ 979 EC_CBC14A 2000;
BA_ "GenSigSNA" SG_ 979 EC_CBC14A "0h";
BA_ "FlexKomComment" SG_ 979 EC_CBC14B "CBC ecu configuration 14";
BA_ "FlexKomIsMotorola" SG_ 979 EC_CBC14B 1;
BA_ "FlexKomSID" SG_ 979 EC_CBC14B 1951;
BA_ "FlexKomSigLaenge" SG_ 979 EC_CBC14B 64;
BA_ "FlexKomSigName" SG_ 979 EC_CBC14B "EC_CBC14";
BA_ "FlexKomSigStartPos" SG_ 979 EC_CBC14B 7;
BA_ "FlexKomSigStartValue" SG_ 979 EC_CBC14B "0000000000000000h";
BA_ "GenSigCycleTime" SG_ 979 EC_CBC14B 2000;
BA_ "GenSigSNA" SG_ 979 EC_CBC14B "0h";
BA_ "FlexKomComment" SG_ 979 EC_ECUCfg14_Stat "ECU Configuration messages status 14";
BA_ "FlexKomIsMotorola" SG_ 979 EC_ECUCfg14_Stat 1;
BA_ "FlexKomSID" SG_ 979 EC_ECUCfg14_Stat 1950;
BA_ "FlexKomSigLaenge" SG_ 979 EC_ECUCfg14_Stat 2;
BA_ "FlexKomSigName" SG_ 979 EC_ECUCfg14_Stat "EC_ECUCfg14_Stat";
BA_ "FlexKomSigStartPos" SG_ 979 EC_ECUCfg14_Stat 1;
BA_ "FlexKomSigStartValue" SG_ 979 EC_ECUCfg14_Stat "03h";
BA_ "GenSigCycleTime" SG_ 979 EC_ECUCfg14_Stat 2000;
BA_ "GenSigSNA" SG_ 979 EC_ECUCfg14_Stat "3h";
BA_ "GenSigStartValue" SG_ 979 EC_ECUCfg14_Stat 3;
BA_ "FlexKomComment" SG_ 706 EC_CBC15A "CBC ecu configuration 15";
BA_ "FlexKomIsMotorola" SG_ 706 EC_CBC15A 1;
BA_ "FlexKomSID" SG_ 706 EC_CBC15A 2072;
BA_ "FlexKomSigLaenge" SG_ 706 EC_CBC15A 48;
BA_ "FlexKomSigName" SG_ 706 EC_CBC15A "EC_CBC15";
BA_ "FlexKomSigStartPos" SG_ 706 EC_CBC15A 7;
BA_ "FlexKomSigStartValue" SG_ 706 EC_CBC15A "000000000000h";
BA_ "GenSigCycleTime" SG_ 706 EC_CBC15A 2000;
BA_ "GenSigSendType" SG_ 706 EC_CBC15A 5;
BA_ "GenSigSNA" SG_ 706 EC_CBC15A "0h";
BA_ "FlexKomComment" SG_ 706 EC_CBC15B "CBC ecu configuration 15";
BA_ "FlexKomIsMotorola" SG_ 706 EC_CBC15B 1;
BA_ "FlexKomSID" SG_ 706 EC_CBC15B 2072;
BA_ "FlexKomSigLaenge" SG_ 706 EC_CBC15B 48;
BA_ "FlexKomSigName" SG_ 706 EC_CBC15B "EC_CBC15";
BA_ "FlexKomSigStartPos" SG_ 706 EC_CBC15B 7;
BA_ "FlexKomSigStartValue" SG_ 706 EC_CBC15B "000000000000h";
BA_ "GenSigCycleTime" SG_ 706 EC_CBC15B 2000;
BA_ "GenSigSendType" SG_ 706 EC_CBC15B 5;
BA_ "GenSigSNA" SG_ 706 EC_CBC15B "0h";
BA_ "FlexKomComment" SG_ 706 EC_ECUCfg15_Stat "ECU Configuration messages status 15";
BA_ "FlexKomIsMotorola" SG_ 706 EC_ECUCfg15_Stat 1;
BA_ "FlexKomSID" SG_ 706 EC_ECUCfg15_Stat 2071;
BA_ "FlexKomSigLaenge" SG_ 706 EC_ECUCfg15_Stat 2;
BA_ "FlexKomSigName" SG_ 706 EC_ECUCfg15_Stat "EC_ECUCfg15_Stat";
BA_ "FlexKomSigStartPos" SG_ 706 EC_ECUCfg15_Stat 1;
BA_ "FlexKomSigStartValue" SG_ 706 EC_ECUCfg15_Stat "03h";
BA_ "GenSigCycleTime" SG_ 706 EC_ECUCfg15_Stat 2000;
BA_ "GenSigSendType" SG_ 706 EC_ECUCfg15_Stat 5;
BA_ "GenSigSNA" SG_ 706 EC_ECUCfg15_Stat "3h";
BA_ "GenSigStartValue" SG_ 706 EC_ECUCfg15_Stat 3;
BA_ "FlexKomComment" SG_ 706 EC_Suspension "Suspension ecu configuration";
BA_ "FlexKomIsMotorola" SG_ 706 EC_Suspension 1;
BA_ "FlexKomSID" SG_ 706 EC_Suspension 891;
BA_ "FlexKomSigLaenge" SG_ 706 EC_Suspension 16;
BA_ "FlexKomSigName" SG_ 706 EC_Suspension "EC_Suspension";
BA_ "FlexKomSigStartPos" SG_ 706 EC_Suspension 55;
BA_ "FlexKomSigStartValue" SG_ 706 EC_Suspension "0000h";
BA_ "GenSigCycleTime" SG_ 706 EC_Suspension 2000;
BA_ "GenSigSendType" SG_ 706 EC_Suspension 5;
BA_ "GenSigSNA" SG_ 706 EC_Suspension "0h";
BA_ "FlexKomComment" SG_ 709 EC_AudTel3A "Audio and telematics ecu configuration 3";
BA_ "FlexKomIsMotorola" SG_ 709 EC_AudTel3A 1;
BA_ "FlexKomSID" SG_ 709 EC_AudTel3A 2288;
BA_ "FlexKomSigLaenge" SG_ 709 EC_AudTel3A 64;
BA_ "FlexKomSigName" SG_ 709 EC_AudTel3A "EC_AudTel3";
BA_ "FlexKomSigStartPos" SG_ 709 EC_AudTel3A 7;
BA_ "FlexKomSigStartValue" SG_ 709 EC_AudTel3A "0000000000000000h";
BA_ "GenSigCycleTime" SG_ 709 EC_AudTel3A 2000;
BA_ "GenSigSendType" SG_ 709 EC_AudTel3A 5;
BA_ "GenSigSNA" SG_ 709 EC_AudTel3A "0h";
BA_ "FlexKomComment" SG_ 709 EC_AudTel3B "Audio and telematics ecu configuration 3";
BA_ "FlexKomIsMotorola" SG_ 709 EC_AudTel3B 1;
BA_ "FlexKomSID" SG_ 709 EC_AudTel3B 2288;
BA_ "FlexKomSigLaenge" SG_ 709 EC_AudTel3B 64;
BA_ "FlexKomSigName" SG_ 709 EC_AudTel3B "EC_AudTel3";
BA_ "FlexKomSigStartPos" SG_ 709 EC_AudTel3B 7;
BA_ "FlexKomSigStartValue" SG_ 709 EC_AudTel3B "0000000000000000h";
BA_ "GenSigCycleTime" SG_ 709 EC_AudTel3B 2000;
BA_ "GenSigSendType" SG_ 709 EC_AudTel3B 5;
BA_ "GenSigSNA" SG_ 709 EC_AudTel3B "0h";
BA_ "FlexKomComment" SG_ 709 EC_ECUCfg16_Stat "ECU Configuration messages status 16";
BA_ "FlexKomIsMotorola" SG_ 709 EC_ECUCfg16_Stat 1;
BA_ "FlexKomSID" SG_ 709 EC_ECUCfg16_Stat 2286;
BA_ "FlexKomSigLaenge" SG_ 709 EC_ECUCfg16_Stat 2;
BA_ "FlexKomSigName" SG_ 709 EC_ECUCfg16_Stat "EC_ECUCfg16_Stat";
BA_ "FlexKomSigStartPos" SG_ 709 EC_ECUCfg16_Stat 1;
BA_ "FlexKomSigStartValue" SG_ 709 EC_ECUCfg16_Stat "03h";
BA_ "GenSigCycleTime" SG_ 709 EC_ECUCfg16_Stat 2000;
BA_ "GenSigSendType" SG_ 709 EC_ECUCfg16_Stat 5;
BA_ "GenSigSNA" SG_ 709 EC_ECUCfg16_Stat "3h";
BA_ "GenSigStartValue" SG_ 709 EC_ECUCfg16_Stat 3;
BA_ "FlexKomComment" SG_ 710 EC_ECUCfg17_Stat "ECU Configuration 17 packet";
BA_ "FlexKomIsMotorola" SG_ 710 EC_ECUCfg17_Stat 1;
BA_ "FlexKomSID" SG_ 710 EC_ECUCfg17_Stat 2478;
BA_ "FlexKomSigLaenge" SG_ 710 EC_ECUCfg17_Stat 64;
BA_ "FlexKomSigName" SG_ 710 EC_ECUCfg17_Stat "EcuCfg17Pkt";
BA_ "FlexKomSigStartPos" SG_ 710 EC_ECUCfg17_Stat 7;
BA_ "FlexKomSigStartValue" SG_ 710 EC_ECUCfg17_Stat "0300000000000000h";
BA_ "GenSigCycleTime" SG_ 710 EC_ECUCfg17_Stat 2000;
BA_ "GenSigSendType" SG_ 710 EC_ECUCfg17_Stat 5;
BA_ "GenSigSNA" SG_ 710 EC_ECUCfg17_Stat "3h";
BA_ "GenSigStartValue" SG_ 710 EC_ECUCfg17_Stat 3;
BA_ "GenSigTimeout_PTS" SG_ 710 EC_ECUCfg17_Stat 21000;
BA_ "FlexKomComment" SG_ 710 EC_PTS "ECU Configuration 17 packet";
BA_ "FlexKomIsMotorola" SG_ 710 EC_PTS 1;
BA_ "FlexKomSID" SG_ 710 EC_PTS 2478;
BA_ "FlexKomSigLaenge" SG_ 710 EC_PTS 64;
BA_ "FlexKomSigName" SG_ 710 EC_PTS "EcuCfg17Pkt";
BA_ "FlexKomSigStartPos" SG_ 710 EC_PTS 7;
BA_ "FlexKomSigStartValue" SG_ 710 EC_PTS "0300000000000000h";
BA_ "GenSigCycleTime" SG_ 710 EC_PTS 2000;
BA_ "GenSigSendType" SG_ 710 EC_PTS 5;
BA_ "GenSigSNA" SG_ 710 EC_PTS "0h";
BA_ "GenSigTimeout_PTS" SG_ 710 EC_PTS 21000;
BA_ "FlexKomComment" SG_ 1009 EC_CBC3A "CBC ecu configuration 3";
BA_ "FlexKomIsMotorola" SG_ 1009 EC_CBC3A 1;
BA_ "FlexKomSID" SG_ 1009 EC_CBC3A 901;
BA_ "FlexKomSigLaenge" SG_ 1009 EC_CBC3A 32;
BA_ "FlexKomSigName" SG_ 1009 EC_CBC3A "EC_CBC3";
BA_ "FlexKomSigStartPos" SG_ 1009 EC_CBC3A 7;
BA_ "FlexKomSigStartValue" SG_ 1009 EC_CBC3A "00000000h";
BA_ "GenSigCycleTime" SG_ 1009 EC_CBC3A 2000;
BA_ "GenSigSNA" SG_ 1009 EC_CBC3A "0h";
BA_ "FlexKomComment" SG_ 1009 EC_CBC3B "CBC ecu configuration 3";
BA_ "FlexKomIsMotorola" SG_ 1009 EC_CBC3B 1;
BA_ "FlexKomSID" SG_ 1009 EC_CBC3B 901;
BA_ "FlexKomSigLaenge" SG_ 1009 EC_CBC3B 32;
BA_ "FlexKomSigName" SG_ 1009 EC_CBC3B "EC_CBC3";
BA_ "FlexKomSigStartPos" SG_ 1009 EC_CBC3B 7;
BA_ "FlexKomSigStartValue" SG_ 1009 EC_CBC3B "00000000h";
BA_ "GenSigCycleTime" SG_ 1009 EC_CBC3B 2000;
BA_ "GenSigSNA" SG_ 1009 EC_CBC3B "0h";
BA_ "FlexKomComment" SG_ 1009 EC_CBC4 "CBC ecu configuration 4";
BA_ "FlexKomIsMotorola" SG_ 1009 EC_CBC4 1;
BA_ "FlexKomSID" SG_ 1009 EC_CBC4 902;
BA_ "FlexKomSigLaenge" SG_ 1009 EC_CBC4 32;
BA_ "FlexKomSigName" SG_ 1009 EC_CBC4 "EC_CBC4";
BA_ "FlexKomSigStartPos" SG_ 1009 EC_CBC4 39;
BA_ "FlexKomSigStartValue" SG_ 1009 EC_CBC4 "00000000h";
BA_ "GenSigCycleTime" SG_ 1009 EC_CBC4 2000;
BA_ "GenSigSNA" SG_ 1009 EC_CBC4 "0h";
BA_ "FlexKomComment" SG_ 1009 EC_ECUCfg2_Stat "ECU Configuration messages status 2";
BA_ "FlexKomIsMotorola" SG_ 1009 EC_ECUCfg2_Stat 1;
BA_ "FlexKomSID" SG_ 1009 EC_ECUCfg2_Stat 1059;
BA_ "FlexKomSigLaenge" SG_ 1009 EC_ECUCfg2_Stat 2;
BA_ "FlexKomSigName" SG_ 1009 EC_ECUCfg2_Stat "EC_ECUCfg2_Stat";
BA_ "FlexKomSigStartPos" SG_ 1009 EC_ECUCfg2_Stat 1;
BA_ "FlexKomSigStartValue" SG_ 1009 EC_ECUCfg2_Stat "03h";
BA_ "GenSigCycleTime" SG_ 1009 EC_ECUCfg2_Stat 2000;
BA_ "GenSigSNA" SG_ 1009 EC_ECUCfg2_Stat "3h";
BA_ "GenSigStartValue" SG_ 1009 EC_ECUCfg2_Stat 3;
BA_ "FlexKomComment" SG_ 1010 EC_AudTel1A "Audio and telematics ecu configuration 1";
BA_ "FlexKomIsMotorola" SG_ 1010 EC_AudTel1A 1;
BA_ "FlexKomSID" SG_ 1010 EC_AudTel1A 897;
BA_ "FlexKomSigLaenge" SG_ 1010 EC_AudTel1A 32;
BA_ "FlexKomSigName" SG_ 1010 EC_AudTel1A "EC_AudTel1";
BA_ "FlexKomSigStartPos" SG_ 1010 EC_AudTel1A 7;
BA_ "FlexKomSigStartValue" SG_ 1010 EC_AudTel1A "00000000h";
BA_ "GenSigCycleTime" SG_ 1010 EC_AudTel1A 2000;
BA_ "GenSigSendType" SG_ 1010 EC_AudTel1A 5;
BA_ "GenSigSNA" SG_ 1010 EC_AudTel1A "0h";
BA_ "FlexKomComment" SG_ 1010 EC_AudTel1B "Audio and telematics ecu configuration 1";
BA_ "FlexKomIsMotorola" SG_ 1010 EC_AudTel1B 1;
BA_ "FlexKomSID" SG_ 1010 EC_AudTel1B 897;
BA_ "FlexKomSigLaenge" SG_ 1010 EC_AudTel1B 32;
BA_ "FlexKomSigName" SG_ 1010 EC_AudTel1B "EC_AudTel1";
BA_ "FlexKomSigStartPos" SG_ 1010 EC_AudTel1B 7;
BA_ "FlexKomSigStartValue" SG_ 1010 EC_AudTel1B "00000000h";
BA_ "GenSigCycleTime" SG_ 1010 EC_AudTel1B 2000;
BA_ "GenSigSendType" SG_ 1010 EC_AudTel1B 5;
BA_ "GenSigSNA" SG_ 1010 EC_AudTel1B "0h";
BA_ "FlexKomComment" SG_ 1010 EC_AudTel2 "Audio and telematics ecu configuration 2";
BA_ "FlexKomIsMotorola" SG_ 1010 EC_AudTel2 1;
BA_ "FlexKomSID" SG_ 1010 EC_AudTel2 898;
BA_ "FlexKomSigLaenge" SG_ 1010 EC_AudTel2 32;
BA_ "FlexKomSigName" SG_ 1010 EC_AudTel2 "EC_AudTel2";
BA_ "FlexKomSigStartPos" SG_ 1010 EC_AudTel2 39;
BA_ "FlexKomSigStartValue" SG_ 1010 EC_AudTel2 "00000000h";
BA_ "GenSigCycleTime" SG_ 1010 EC_AudTel2 2000;
BA_ "GenSigSendType" SG_ 1010 EC_AudTel2 5;
BA_ "GenSigSNA" SG_ 1010 EC_AudTel2 "0h";
BA_ "FlexKomComment" SG_ 1010 EC_ECUCfg3_Stat "ECU Configuration messages status 3";
BA_ "FlexKomIsMotorola" SG_ 1010 EC_ECUCfg3_Stat 1;
BA_ "FlexKomSID" SG_ 1010 EC_ECUCfg3_Stat 1060;
BA_ "FlexKomSigLaenge" SG_ 1010 EC_ECUCfg3_Stat 2;
BA_ "FlexKomSigName" SG_ 1010 EC_ECUCfg3_Stat "EC_ECUCfg3_Stat";
BA_ "FlexKomSigStartPos" SG_ 1010 EC_ECUCfg3_Stat 1;
BA_ "FlexKomSigStartValue" SG_ 1010 EC_ECUCfg3_Stat "03h";
BA_ "GenSigCycleTime" SG_ 1010 EC_ECUCfg3_Stat 2000;
BA_ "GenSigSendType" SG_ 1010 EC_ECUCfg3_Stat 5;
BA_ "GenSigSNA" SG_ 1010 EC_ECUCfg3_Stat "3h";
BA_ "GenSigStartValue" SG_ 1010 EC_ECUCfg3_Stat 3;
BA_ "FlexKomComment" SG_ 1011 EC_Cluster1A "Instrument cluster ecu configuration 1";
BA_ "FlexKomIsMotorola" SG_ 1011 EC_Cluster1A 1;
BA_ "FlexKomSID" SG_ 1011 EC_Cluster1A 896;
BA_ "FlexKomSigLaenge" SG_ 1011 EC_Cluster1A 32;
BA_ "FlexKomSigName" SG_ 1011 EC_Cluster1A "EC_Cluster1";
BA_ "FlexKomSigStartPos" SG_ 1011 EC_Cluster1A 7;
BA_ "FlexKomSigStartValue" SG_ 1011 EC_Cluster1A "00000000h";
BA_ "GenSigCycleTime" SG_ 1011 EC_Cluster1A 2000;
BA_ "GenSigSendType" SG_ 1011 EC_Cluster1A 5;
BA_ "GenSigSNA" SG_ 1011 EC_Cluster1A "0h";
BA_ "GenSigTimeout_IC" SG_ 1011 EC_Cluster1A 21000;
BA_ "FlexKomComment" SG_ 1011 EC_Cluster1B "Instrument cluster ecu configuration 1";
BA_ "FlexKomIsMotorola" SG_ 1011 EC_Cluster1B 1;
BA_ "FlexKomSID" SG_ 1011 EC_Cluster1B 896;
BA_ "FlexKomSigLaenge" SG_ 1011 EC_Cluster1B 32;
BA_ "FlexKomSigName" SG_ 1011 EC_Cluster1B "EC_Cluster1";
BA_ "FlexKomSigStartPos" SG_ 1011 EC_Cluster1B 7;
BA_ "FlexKomSigStartValue" SG_ 1011 EC_Cluster1B "00000000h";
BA_ "GenSigCycleTime" SG_ 1011 EC_Cluster1B 2000;
BA_ "GenSigSendType" SG_ 1011 EC_Cluster1B 5;
BA_ "GenSigSNA" SG_ 1011 EC_Cluster1B "0h";
BA_ "GenSigTimeout_IC" SG_ 1011 EC_Cluster1B 21000;
BA_ "FlexKomComment" SG_ 1011 EC_Cluster2 "Instrument cluster ecu configuration 2";
BA_ "FlexKomIsMotorola" SG_ 1011 EC_Cluster2 1;
BA_ "FlexKomSID" SG_ 1011 EC_Cluster2 903;
BA_ "FlexKomSigLaenge" SG_ 1011 EC_Cluster2 32;
BA_ "FlexKomSigName" SG_ 1011 EC_Cluster2 "EC_Cluster2";
BA_ "FlexKomSigStartPos" SG_ 1011 EC_Cluster2 39;
BA_ "FlexKomSigStartValue" SG_ 1011 EC_Cluster2 "00000000h";
BA_ "GenSigCycleTime" SG_ 1011 EC_Cluster2 2000;
BA_ "GenSigSendType" SG_ 1011 EC_Cluster2 5;
BA_ "GenSigSNA" SG_ 1011 EC_Cluster2 "0h";
BA_ "GenSigTimeout_IC" SG_ 1011 EC_Cluster2 21000;
BA_ "FlexKomComment" SG_ 1011 EC_ECUCfg4_Stat "ECU Configuration messages status 4";
BA_ "FlexKomIsMotorola" SG_ 1011 EC_ECUCfg4_Stat 1;
BA_ "FlexKomSID" SG_ 1011 EC_ECUCfg4_Stat 1061;
BA_ "FlexKomSigLaenge" SG_ 1011 EC_ECUCfg4_Stat 2;
BA_ "FlexKomSigName" SG_ 1011 EC_ECUCfg4_Stat "EC_ECUCfg4_Stat";
BA_ "FlexKomSigStartPos" SG_ 1011 EC_ECUCfg4_Stat 1;
BA_ "FlexKomSigStartValue" SG_ 1011 EC_ECUCfg4_Stat "03h";
BA_ "GenSigCycleTime" SG_ 1011 EC_ECUCfg4_Stat 2000;
BA_ "GenSigSendType" SG_ 1011 EC_ECUCfg4_Stat 5;
BA_ "GenSigSNA" SG_ 1011 EC_ECUCfg4_Stat "3h";
BA_ "GenSigStartValue" SG_ 1011 EC_ECUCfg4_Stat 3;
BA_ "GenSigTimeout_IC" SG_ 1011 EC_ECUCfg4_Stat 21000;
BA_ "FlexKomComment" SG_ 1012 EC_Doors "Doors ecu configuration";
BA_ "FlexKomIsMotorola" SG_ 1012 EC_Doors 1;
BA_ "FlexKomSID" SG_ 1012 EC_Doors 893;
BA_ "FlexKomSigLaenge" SG_ 1012 EC_Doors 24;
BA_ "FlexKomSigName" SG_ 1012 EC_Doors "EC_Doors";
BA_ "FlexKomSigStartPos" SG_ 1012 EC_Doors 31;
BA_ "FlexKomSigStartValue" SG_ 1012 EC_Doors "000000h";
BA_ "GenSigCycleTime" SG_ 1012 EC_Doors 2000;
BA_ "GenSigSendType" SG_ 1012 EC_Doors 5;
BA_ "GenSigSNA" SG_ 1012 EC_Doors "0h";
BA_ "FlexKomComment" SG_ 1012 EC_ECUCfg5_Stat "ECU Configuration messages status 5";
BA_ "FlexKomIsMotorola" SG_ 1012 EC_ECUCfg5_Stat 1;
BA_ "FlexKomSID" SG_ 1012 EC_ECUCfg5_Stat 1062;
BA_ "FlexKomSigLaenge" SG_ 1012 EC_ECUCfg5_Stat 2;
BA_ "FlexKomSigName" SG_ 1012 EC_ECUCfg5_Stat "EC_ECUCfg5_Stat";
BA_ "FlexKomSigStartPos" SG_ 1012 EC_ECUCfg5_Stat 1;
BA_ "FlexKomSigStartValue" SG_ 1012 EC_ECUCfg5_Stat "03h";
BA_ "GenSigCycleTime" SG_ 1012 EC_ECUCfg5_Stat 2000;
BA_ "GenSigSendType" SG_ 1012 EC_ECUCfg5_Stat 5;
BA_ "GenSigSNA" SG_ 1012 EC_ECUCfg5_Stat "3h";
BA_ "GenSigStartValue" SG_ 1012 EC_ECUCfg5_Stat 3;
BA_ "FlexKomComment" SG_ 1012 EC_Memory "Memory ecu configuration";
BA_ "FlexKomIsMotorola" SG_ 1012 EC_Memory 1;
BA_ "FlexKomSID" SG_ 1012 EC_Memory 894;
BA_ "FlexKomSigLaenge" SG_ 1012 EC_Memory 16;
BA_ "FlexKomSigName" SG_ 1012 EC_Memory "EC_Memory";
BA_ "FlexKomSigStartPos" SG_ 1012 EC_Memory 55;
BA_ "FlexKomSigStartValue" SG_ 1012 EC_Memory "0000h";
BA_ "GenSigCycleTime" SG_ 1012 EC_Memory 2000;
BA_ "GenSigSendType" SG_ 1012 EC_Memory 5;
BA_ "GenSigSNA" SG_ 1012 EC_Memory "0h";
BA_ "FlexKomComment" SG_ 1012 EC_WirelessA "Wireless ecu configuration";
BA_ "FlexKomIsMotorola" SG_ 1012 EC_WirelessA 1;
BA_ "FlexKomSID" SG_ 1012 EC_WirelessA 895;
BA_ "FlexKomSigLaenge" SG_ 1012 EC_WirelessA 24;
BA_ "FlexKomSigName" SG_ 1012 EC_WirelessA "EC_Wireless";
BA_ "FlexKomSigStartPos" SG_ 1012 EC_WirelessA 7;
BA_ "FlexKomSigStartValue" SG_ 1012 EC_WirelessA "000000h";
BA_ "GenSigCycleTime" SG_ 1012 EC_WirelessA 2000;
BA_ "GenSigSendType" SG_ 1012 EC_WirelessA 5;
BA_ "GenSigSNA" SG_ 1012 EC_WirelessA "0h";
BA_ "FlexKomComment" SG_ 1012 EC_WirelessB "Wireless ecu configuration";
BA_ "FlexKomIsMotorola" SG_ 1012 EC_WirelessB 1;
BA_ "FlexKomSID" SG_ 1012 EC_WirelessB 895;
BA_ "FlexKomSigLaenge" SG_ 1012 EC_WirelessB 24;
BA_ "FlexKomSigName" SG_ 1012 EC_WirelessB "EC_Wireless";
BA_ "FlexKomSigStartPos" SG_ 1012 EC_WirelessB 7;
BA_ "FlexKomSigStartValue" SG_ 1012 EC_WirelessB "000000h";
BA_ "GenSigCycleTime" SG_ 1012 EC_WirelessB 2000;
BA_ "GenSigSendType" SG_ 1012 EC_WirelessB 5;
BA_ "GenSigSNA" SG_ 1012 EC_WirelessB "0h";
BA_ "FlexKomComment" SG_ 1013 EC_BrakesA "Brake system ecu configuration";
BA_ "FlexKomIsMotorola" SG_ 1013 EC_BrakesA 1;
BA_ "FlexKomSID" SG_ 1013 EC_BrakesA 889;
BA_ "FlexKomSigLaenge" SG_ 1013 EC_BrakesA 16;
BA_ "FlexKomSigName" SG_ 1013 EC_BrakesA "EC_Brakes";
BA_ "FlexKomSigStartPos" SG_ 1013 EC_BrakesA 7;
BA_ "FlexKomSigStartValue" SG_ 1013 EC_BrakesA "0000h";
BA_ "GenSigCycleTime" SG_ 1013 EC_BrakesA 2000;
BA_ "GenSigSendType" SG_ 1013 EC_BrakesA 5;
BA_ "GenSigSNA" SG_ 1013 EC_BrakesA "0h";
BA_ "FlexKomComment" SG_ 1013 EC_BrakesB "Brake system ecu configuration";
BA_ "FlexKomIsMotorola" SG_ 1013 EC_BrakesB 1;
BA_ "FlexKomSID" SG_ 1013 EC_BrakesB 889;
BA_ "FlexKomSigLaenge" SG_ 1013 EC_BrakesB 16;
BA_ "FlexKomSigName" SG_ 1013 EC_BrakesB "EC_Brakes";
BA_ "FlexKomSigStartPos" SG_ 1013 EC_BrakesB 7;
BA_ "FlexKomSigStartValue" SG_ 1013 EC_BrakesB "0000h";
BA_ "GenSigCycleTime" SG_ 1013 EC_BrakesB 2000;
BA_ "GenSigSendType" SG_ 1013 EC_BrakesB 5;
BA_ "GenSigSNA" SG_ 1013 EC_BrakesB "0h";
BA_ "FlexKomComment" SG_ 1013 EC_ECUCfg6_Stat "ECU Configuration messages status 6";
BA_ "FlexKomIsMotorola" SG_ 1013 EC_ECUCfg6_Stat 1;
BA_ "FlexKomSID" SG_ 1013 EC_ECUCfg6_Stat 1063;
BA_ "FlexKomSigLaenge" SG_ 1013 EC_ECUCfg6_Stat 2;
BA_ "FlexKomSigName" SG_ 1013 EC_ECUCfg6_Stat "EC_ECUCfg6_Stat";
BA_ "FlexKomSigStartPos" SG_ 1013 EC_ECUCfg6_Stat 1;
BA_ "FlexKomSigStartValue" SG_ 1013 EC_ECUCfg6_Stat "03h";
BA_ "GenSigCycleTime" SG_ 1013 EC_ECUCfg6_Stat 2000;
BA_ "GenSigSendType" SG_ 1013 EC_ECUCfg6_Stat 5;
BA_ "GenSigSNA" SG_ 1013 EC_ECUCfg6_Stat "3h";
BA_ "GenSigStartValue" SG_ 1013 EC_ECUCfg6_Stat 3;
BA_ "GenSigTimeout_EPS" SG_ 1013 EC_ECUCfg6_Stat 21000;
BA_ "GenSigTimeout_ORC" SG_ 1013 EC_ECUCfg6_Stat 7000;
BA_ "RID" SG_ 1013 EC_ECUCfg6_Stat "9994";
BA_ "FlexKomComment" SG_ 1013 EC_Powertrain "Powertrain ecu configuration";
BA_ "FlexKomIsMotorola" SG_ 1013 EC_Powertrain 1;
BA_ "FlexKomSID" SG_ 1013 EC_Powertrain 890;
BA_ "FlexKomSigLaenge" SG_ 1013 EC_Powertrain 16;
BA_ "FlexKomSigName" SG_ 1013 EC_Powertrain "EC_Powertrain";
BA_ "FlexKomSigStartPos" SG_ 1013 EC_Powertrain 39;
BA_ "FlexKomSigStartValue" SG_ 1013 EC_Powertrain "0000h";
BA_ "GenSigCycleTime" SG_ 1013 EC_Powertrain 2000;
BA_ "GenSigSendType" SG_ 1013 EC_Powertrain 5;
BA_ "GenSigSNA" SG_ 1013 EC_Powertrain "0h";
BA_ "FlexKomComment" SG_ 1013 EC_Safety "Safety ecu configuration";
BA_ "FlexKomIsMotorola" SG_ 1013 EC_Safety 1;
BA_ "FlexKomSID" SG_ 1013 EC_Safety 892;
BA_ "FlexKomSigLaenge" SG_ 1013 EC_Safety 16;
BA_ "FlexKomSigName" SG_ 1013 EC_Safety "EC_Safety";
BA_ "FlexKomSigStartPos" SG_ 1013 EC_Safety 55;
BA_ "FlexKomSigStartValue" SG_ 1013 EC_Safety "0000h";
BA_ "GenSigCycleTime" SG_ 1013 EC_Safety 2000;
BA_ "GenSigSendType" SG_ 1013 EC_Safety 5;
BA_ "GenSigSNA" SG_ 1013 EC_Safety "0h";
BA_ "GenSigTimeout_ORC" SG_ 1013 EC_Safety 7000;
BA_ "FlexKomComment" SG_ 1013 EC_Steering "Steering ecu configuration";
BA_ "FlexKomIsMotorola" SG_ 1013 EC_Steering 1;
BA_ "FlexKomSID" SG_ 1013 EC_Steering 1982;
BA_ "FlexKomSigLaenge" SG_ 1013 EC_Steering 16;
BA_ "FlexKomSigName" SG_ 1013 EC_Steering "EC_Steering";
BA_ "FlexKomSigStartPos" SG_ 1013 EC_Steering 23;
BA_ "FlexKomSigStartValue" SG_ 1013 EC_Steering "0000h";
BA_ "GenSigCycleTime" SG_ 1013 EC_Steering 2000;
BA_ "GenSigSendType" SG_ 1013 EC_Steering 5;
BA_ "GenSigSNA" SG_ 1013 EC_Steering "0h";
BA_ "GenSigTimeout_EPS" SG_ 1013 EC_Steering 21000;
BA_ "GenSigTimeout_ORC" SG_ 1013 EC_Steering 7000;
BA_ "RID" SG_ 1013 EC_Steering "9770";
BA_ "FlexKomComment" SG_ 1014 EC_CBC5A "CBC ecu configuration 5";
BA_ "FlexKomIsMotorola" SG_ 1014 EC_CBC5A 1;
BA_ "FlexKomSID" SG_ 1014 EC_CBC5A 1105;
BA_ "FlexKomSigLaenge" SG_ 1014 EC_CBC5A 32;
BA_ "FlexKomSigName" SG_ 1014 EC_CBC5A "EC_CBC5";
BA_ "FlexKomSigStartPos" SG_ 1014 EC_CBC5A 7;
BA_ "FlexKomSigStartValue" SG_ 1014 EC_CBC5A "00000000h";
BA_ "GenSigCycleTime" SG_ 1014 EC_CBC5A 2000;
BA_ "GenSigSNA" SG_ 1014 EC_CBC5A "0h";
BA_ "FlexKomComment" SG_ 1014 EC_CBC5B "CBC ecu configuration 5";
BA_ "FlexKomIsMotorola" SG_ 1014 EC_CBC5B 1;
BA_ "FlexKomSID" SG_ 1014 EC_CBC5B 1105;
BA_ "FlexKomSigLaenge" SG_ 1014 EC_CBC5B 32;
BA_ "FlexKomSigName" SG_ 1014 EC_CBC5B "EC_CBC5";
BA_ "FlexKomSigStartPos" SG_ 1014 EC_CBC5B 7;
BA_ "FlexKomSigStartValue" SG_ 1014 EC_CBC5B "00000000h";
BA_ "GenSigCycleTime" SG_ 1014 EC_CBC5B 2000;
BA_ "GenSigSNA" SG_ 1014 EC_CBC5B "0h";
BA_ "FlexKomComment" SG_ 1014 EC_CBC6 "CBC ecu configuration 6";
BA_ "FlexKomIsMotorola" SG_ 1014 EC_CBC6 1;
BA_ "FlexKomSID" SG_ 1014 EC_CBC6 1103;
BA_ "FlexKomSigLaenge" SG_ 1014 EC_CBC6 32;
BA_ "FlexKomSigName" SG_ 1014 EC_CBC6 "EC_CBC6";
BA_ "FlexKomSigStartPos" SG_ 1014 EC_CBC6 39;
BA_ "FlexKomSigStartValue" SG_ 1014 EC_CBC6 "00000000h";
BA_ "GenSigCycleTime" SG_ 1014 EC_CBC6 2000;
BA_ "GenSigSNA" SG_ 1014 EC_CBC6 "0h";
BA_ "FlexKomComment" SG_ 1014 EC_ECUCfg7_Stat "ECU Configuration messages status 7";
BA_ "FlexKomIsMotorola" SG_ 1014 EC_ECUCfg7_Stat 1;
BA_ "FlexKomSID" SG_ 1014 EC_ECUCfg7_Stat 1102;
BA_ "FlexKomSigLaenge" SG_ 1014 EC_ECUCfg7_Stat 2;
BA_ "FlexKomSigName" SG_ 1014 EC_ECUCfg7_Stat "EC_ECUCfg7_Stat";
BA_ "FlexKomSigStartPos" SG_ 1014 EC_ECUCfg7_Stat 1;
BA_ "FlexKomSigStartValue" SG_ 1014 EC_ECUCfg7_Stat "03h";
BA_ "GenSigCycleTime" SG_ 1014 EC_ECUCfg7_Stat 2000;
BA_ "GenSigSNA" SG_ 1014 EC_ECUCfg7_Stat "3h";
BA_ "GenSigStartValue" SG_ 1014 EC_ECUCfg7_Stat 3;
BA_ "FlexKomComment" SG_ 1015 EC_CBC7A "CBC ecu configuration 7";
BA_ "FlexKomIsMotorola" SG_ 1015 EC_CBC7A 1;
BA_ "FlexKomSID" SG_ 1015 EC_CBC7A 1106;
BA_ "FlexKomSigLaenge" SG_ 1015 EC_CBC7A 32;
BA_ "FlexKomSigName" SG_ 1015 EC_CBC7A "EC_CBC7";
BA_ "FlexKomSigStartPos" SG_ 1015 EC_CBC7A 7;
BA_ "FlexKomSigStartValue" SG_ 1015 EC_CBC7A "00000000h";
BA_ "GenSigCycleTime" SG_ 1015 EC_CBC7A 2000;
BA_ "GenSigSNA" SG_ 1015 EC_CBC7A "0h";
BA_ "FlexKomComment" SG_ 1015 EC_CBC7B "CBC ecu configuration 7";
BA_ "FlexKomIsMotorola" SG_ 1015 EC_CBC7B 1;
BA_ "FlexKomSID" SG_ 1015 EC_CBC7B 1106;
BA_ "FlexKomSigLaenge" SG_ 1015 EC_CBC7B 32;
BA_ "FlexKomSigName" SG_ 1015 EC_CBC7B "EC_CBC7";
BA_ "FlexKomSigStartPos" SG_ 1015 EC_CBC7B 7;
BA_ "FlexKomSigStartValue" SG_ 1015 EC_CBC7B "00000000h";
BA_ "GenSigCycleTime" SG_ 1015 EC_CBC7B 2000;
BA_ "GenSigSNA" SG_ 1015 EC_CBC7B "0h";
BA_ "FlexKomComment" SG_ 1015 EC_CBC8 "CBC ecu configuration 8";
BA_ "FlexKomIsMotorola" SG_ 1015 EC_CBC8 1;
BA_ "FlexKomSID" SG_ 1015 EC_CBC8 1104;
BA_ "FlexKomSigLaenge" SG_ 1015 EC_CBC8 32;
BA_ "FlexKomSigName" SG_ 1015 EC_CBC8 "EC_CBC8";
BA_ "FlexKomSigStartPos" SG_ 1015 EC_CBC8 39;
BA_ "FlexKomSigStartValue" SG_ 1015 EC_CBC8 "00000000h";
BA_ "GenSigCycleTime" SG_ 1015 EC_CBC8 2000;
BA_ "GenSigSNA" SG_ 1015 EC_CBC8 "0h";
BA_ "FlexKomComment" SG_ 1015 EC_ECUCfg8_Stat "ECU Configuration messages status 8";
BA_ "FlexKomIsMotorola" SG_ 1015 EC_ECUCfg8_Stat 1;
BA_ "FlexKomSID" SG_ 1015 EC_ECUCfg8_Stat 1101;
BA_ "FlexKomSigLaenge" SG_ 1015 EC_ECUCfg8_Stat 2;
BA_ "FlexKomSigName" SG_ 1015 EC_ECUCfg8_Stat "EC_ECUCfg8_Stat";
BA_ "FlexKomSigStartPos" SG_ 1015 EC_ECUCfg8_Stat 1;
BA_ "FlexKomSigStartValue" SG_ 1015 EC_ECUCfg8_Stat "03h";
BA_ "GenSigCycleTime" SG_ 1015 EC_ECUCfg8_Stat 2000;
BA_ "GenSigSNA" SG_ 1015 EC_ECUCfg8_Stat "3h";
BA_ "GenSigStartValue" SG_ 1015 EC_ECUCfg8_Stat 3;
BA_ "FlexKomComment" SG_ 984 EC_CBC9A1 "CBC configuration 9A";
BA_ "FlexKomIsMotorola" SG_ 984 EC_CBC9A1 1;
BA_ "FlexKomSID" SG_ 984 EC_CBC9A1 1421;
BA_ "FlexKomSigLaenge" SG_ 984 EC_CBC9A1 32;
BA_ "FlexKomSigName" SG_ 984 EC_CBC9A1 "EC_CBC9A";
BA_ "FlexKomSigStartPos" SG_ 984 EC_CBC9A1 7;
BA_ "FlexKomSigStartValue" SG_ 984 EC_CBC9A1 "00000000h";
BA_ "GenSigCycleTime" SG_ 984 EC_CBC9A1 2000;
BA_ "GenSigSNA" SG_ 984 EC_CBC9A1 "0h";
BA_ "FlexKomComment" SG_ 984 EC_CBC9A2 "CBC configuration 9A";
BA_ "FlexKomIsMotorola" SG_ 984 EC_CBC9A2 1;
BA_ "FlexKomSID" SG_ 984 EC_CBC9A2 1421;
BA_ "FlexKomSigLaenge" SG_ 984 EC_CBC9A2 32;
BA_ "FlexKomSigName" SG_ 984 EC_CBC9A2 "EC_CBC9A";
BA_ "FlexKomSigStartPos" SG_ 984 EC_CBC9A2 7;
BA_ "FlexKomSigStartValue" SG_ 984 EC_CBC9A2 "00000000h";
BA_ "GenSigCycleTime" SG_ 984 EC_CBC9A2 2000;
BA_ "GenSigSNA" SG_ 984 EC_CBC9A2 "0h";
BA_ "FlexKomComment" SG_ 984 EC_CBC9B "CBC configuration 9B";
BA_ "FlexKomIsMotorola" SG_ 984 EC_CBC9B 1;
BA_ "FlexKomSID" SG_ 984 EC_CBC9B 1422;
BA_ "FlexKomSigLaenge" SG_ 984 EC_CBC9B 16;
BA_ "FlexKomSigName" SG_ 984 EC_CBC9B "EC_CBC9B";
BA_ "FlexKomSigStartPos" SG_ 984 EC_CBC9B 39;
BA_ "FlexKomSigStartValue" SG_ 984 EC_CBC9B "0000h";
BA_ "GenSigCycleTime" SG_ 984 EC_CBC9B 2000;
BA_ "GenSigSNA" SG_ 984 EC_CBC9B "0h";
BA_ "FlexKomComment" SG_ 984 EC_ECUCfg9_Stat "ECU Configuration messages status 9";
BA_ "FlexKomIsMotorola" SG_ 984 EC_ECUCfg9_Stat 1;
BA_ "FlexKomSID" SG_ 984 EC_ECUCfg9_Stat 1215;
BA_ "FlexKomSigLaenge" SG_ 984 EC_ECUCfg9_Stat 2;
BA_ "FlexKomSigName" SG_ 984 EC_ECUCfg9_Stat "EC_ECUCfg9_Stat";
BA_ "FlexKomSigStartPos" SG_ 984 EC_ECUCfg9_Stat 1;
BA_ "FlexKomSigStartValue" SG_ 984 EC_ECUCfg9_Stat "03h";
BA_ "GenSigCycleTime" SG_ 984 EC_ECUCfg9_Stat 2000;
BA_ "GenSigSNA" SG_ 984 EC_ECUCfg9_Stat "3h";
BA_ "GenSigStartValue" SG_ 984 EC_ECUCfg9_Stat 3;
BA_ "FlexKomComment" SG_ 984 EC_ITM "ITM ecu configuration";
BA_ "FlexKomIsMotorola" SG_ 984 EC_ITM 1;
BA_ "FlexKomSID" SG_ 984 EC_ITM 1219;
BA_ "FlexKomSigLaenge" SG_ 984 EC_ITM 16;
BA_ "FlexKomSigName" SG_ 984 EC_ITM "EC_ITM";
BA_ "FlexKomSigStartPos" SG_ 984 EC_ITM 55;
BA_ "FlexKomSigStartValue" SG_ 984 EC_ITM "0000h";
BA_ "GenSigCycleTime" SG_ 984 EC_ITM 2000;
BA_ "GenSigSNA" SG_ 984 EC_ITM "0h";
BA_ "FlexKomComment" SG_ 908 GPS_Date_Day "GPS Date and UTC";
BA_ "FlexKomIsMotorola" SG_ 908 GPS_Date_Day 1;
BA_ "FlexKomSID" SG_ 908 GPS_Date_Day 566;
BA_ "FlexKomSigLaenge" SG_ 908 GPS_Date_Day 64;
BA_ "FlexKomSigName" SG_ 908 GPS_Date_Day "GPS_Date_UTC";
BA_ "FlexKomSigStartPos" SG_ 908 GPS_Date_Day 7;
BA_ "FlexKomSigStartValue" SG_ 908 GPS_Date_Day "FFFFFFFFFFFFFFFFh";
BA_ "GenSigCycleTime" SG_ 908 GPS_Date_Day 1000;
BA_ "GenSigSNA" SG_ 908 GPS_Date_Day "FFh";
BA_ "GenSigStartValue" SG_ 908 GPS_Date_Day 255;
BA_ "RID" SG_ 908 GPS_Date_Day "2897";
BA_ "FlexKomComment" SG_ 908 GPS_Date_Month "GPS Date and UTC";
BA_ "FlexKomIsMotorola" SG_ 908 GPS_Date_Month 1;
BA_ "FlexKomSID" SG_ 908 GPS_Date_Month 566;
BA_ "FlexKomSigLaenge" SG_ 908 GPS_Date_Month 64;
BA_ "FlexKomSigName" SG_ 908 GPS_Date_Month "GPS_Date_UTC";
BA_ "FlexKomSigStartPos" SG_ 908 GPS_Date_Month 7;
BA_ "FlexKomSigStartValue" SG_ 908 GPS_Date_Month "FFFFFFFFFFFFFFFFh";
BA_ "GenSigCycleTime" SG_ 908 GPS_Date_Month 1000;
BA_ "GenSigSNA" SG_ 908 GPS_Date_Month "FFh";
BA_ "GenSigStartValue" SG_ 908 GPS_Date_Month 255;
BA_ "RID" SG_ 908 GPS_Date_Month "2895";
BA_ "FlexKomComment" SG_ 908 GPS_Date_Year "GPS Date and UTC";
BA_ "FlexKomIsMotorola" SG_ 908 GPS_Date_Year 1;
BA_ "FlexKomSID" SG_ 908 GPS_Date_Year 566;
BA_ "FlexKomSigLaenge" SG_ 908 GPS_Date_Year 64;
BA_ "FlexKomSigName" SG_ 908 GPS_Date_Year "GPS_Date_UTC";
BA_ "FlexKomSigStartPos" SG_ 908 GPS_Date_Year 7;
BA_ "FlexKomSigStartValue" SG_ 908 GPS_Date_Year "FFFFFFFFFFFFFFFFh";
BA_ "GenSigCycleTime" SG_ 908 GPS_Date_Year 1000;
BA_ "GenSigSNA" SG_ 908 GPS_Date_Year "FFFFh";
BA_ "GenSigStartValue" SG_ 908 GPS_Date_Year 65535;
BA_ "RID" SG_ 908 GPS_Date_Year "2896";
BA_ "FlexKomComment" SG_ 908 GPS_UTC_Hour "GPS Date and UTC";
BA_ "FlexKomIsMotorola" SG_ 908 GPS_UTC_Hour 1;
BA_ "FlexKomSID" SG_ 908 GPS_UTC_Hour 566;
BA_ "FlexKomSigLaenge" SG_ 908 GPS_UTC_Hour 64;
BA_ "FlexKomSigName" SG_ 908 GPS_UTC_Hour "GPS_Date_UTC";
BA_ "FlexKomSigStartPos" SG_ 908 GPS_UTC_Hour 7;
BA_ "FlexKomSigStartValue" SG_ 908 GPS_UTC_Hour "FFFFFFFFFFFFFFFFh";
BA_ "GenSigCycleTime" SG_ 908 GPS_UTC_Hour 1000;
BA_ "GenSigSNA" SG_ 908 GPS_UTC_Hour "FFh";
BA_ "GenSigStartValue" SG_ 908 GPS_UTC_Hour 255;
BA_ "RID" SG_ 908 GPS_UTC_Hour "2899";
BA_ "FlexKomComment" SG_ 908 GPS_UTC_Minute "GPS Date and UTC";
BA_ "FlexKomIsMotorola" SG_ 908 GPS_UTC_Minute 1;
BA_ "FlexKomSID" SG_ 908 GPS_UTC_Minute 566;
BA_ "FlexKomSigLaenge" SG_ 908 GPS_UTC_Minute 64;
BA_ "FlexKomSigName" SG_ 908 GPS_UTC_Minute "GPS_Date_UTC";
BA_ "FlexKomSigStartPos" SG_ 908 GPS_UTC_Minute 7;
BA_ "FlexKomSigStartValue" SG_ 908 GPS_UTC_Minute "FFFFFFFFFFFFFFFFh";
BA_ "GenSigCycleTime" SG_ 908 GPS_UTC_Minute 1000;
BA_ "GenSigSNA" SG_ 908 GPS_UTC_Minute "FFh";
BA_ "GenSigStartValue" SG_ 908 GPS_UTC_Minute 255;
BA_ "RID" SG_ 908 GPS_UTC_Minute "2902";
BA_ "FlexKomComment" SG_ 908 GPS_UTC_Second "GPS Date and UTC";
BA_ "FlexKomIsMotorola" SG_ 908 GPS_UTC_Second 1;
BA_ "FlexKomSID" SG_ 908 GPS_UTC_Second 566;
BA_ "FlexKomSigLaenge" SG_ 908 GPS_UTC_Second 64;
BA_ "FlexKomSigName" SG_ 908 GPS_UTC_Second "GPS_Date_UTC";
BA_ "FlexKomSigStartPos" SG_ 908 GPS_UTC_Second 7;
BA_ "FlexKomSigStartValue" SG_ 908 GPS_UTC_Second "FFFFFFFFFFFFFFFFh";
BA_ "GenSigCycleTime" SG_ 908 GPS_UTC_Second 1000;
BA_ "GenSigSNA" SG_ 908 GPS_UTC_Second "FFFFh";
BA_ "GenSigStartValue" SG_ 908 GPS_UTC_Second 65535;
BA_ "RID" SG_ 908 GPS_UTC_Second "2898";
BA_ "FlexKomComment" SG_ 974 DRV_TEMP_DR_POS "Temporary development packet - route signals from ";
BA_ "FlexKomIsMotorola" SG_ 974 DRV_TEMP_DR_POS 1;
BA_ "FlexKomSID" SG_ 974 DRV_TEMP_DR_POS 1445;
BA_ "FlexKomSigLaenge" SG_ 974 DRV_TEMP_DR_POS 40;
BA_ "FlexKomSigName" SG_ 974 DRV_TEMP_DR_POS "GW_Dev";
BA_ "FlexKomSigStartPos" SG_ 974 DRV_TEMP_DR_POS 7;
BA_ "FlexKomSigStartValue" SG_ 974 DRV_TEMP_DR_POS "7F0F7F7F7Fh";
BA_ "GenSigCycleTime" SG_ 974 DRV_TEMP_DR_POS 1000;
BA_ "GenSigSendType" SG_ 974 DRV_TEMP_DR_POS 5;
BA_ "GenSigSNA" SG_ 974 DRV_TEMP_DR_POS "7Fh";
BA_ "GenSigStartValue" SG_ 974 DRV_TEMP_DR_POS 127;
BA_ "RID" SG_ 974 DRV_TEMP_DR_POS "1232";
BA_ "FlexKomComment" SG_ 974 FT_HVAC_BLW_FN_SP "Temporary development packet - route signals from ";
BA_ "FlexKomIsMotorola" SG_ 974 FT_HVAC_BLW_FN_SP 1;
BA_ "FlexKomSID" SG_ 974 FT_HVAC_BLW_FN_SP 1445;
BA_ "FlexKomSigLaenge" SG_ 974 FT_HVAC_BLW_FN_SP 40;
BA_ "FlexKomSigName" SG_ 974 FT_HVAC_BLW_FN_SP "GW_Dev";
BA_ "FlexKomSigStartPos" SG_ 974 FT_HVAC_BLW_FN_SP 7;
BA_ "FlexKomSigStartValue" SG_ 974 FT_HVAC_BLW_FN_SP "7F0F7F7F7Fh";
BA_ "GenSigCycleTime" SG_ 974 FT_HVAC_BLW_FN_SP 1000;
BA_ "GenSigSendType" SG_ 974 FT_HVAC_BLW_FN_SP 5;
BA_ "GenSigSNA" SG_ 974 FT_HVAC_BLW_FN_SP "7Fh";
BA_ "GenSigStartValue" SG_ 974 FT_HVAC_BLW_FN_SP 127;
BA_ "GenSigTimeout_IC" SG_ 974 FT_HVAC_BLW_FN_SP 10500;
BA_ "RID" SG_ 974 FT_HVAC_BLW_FN_SP "1070";
BA_ "FlexKomComment" SG_ 974 PAS_TEMP_DR_POS "Temporary development packet - route signals from ";
BA_ "FlexKomIsMotorola" SG_ 974 PAS_TEMP_DR_POS 1;
BA_ "FlexKomSID" SG_ 974 PAS_TEMP_DR_POS 1445;
BA_ "FlexKomSigLaenge" SG_ 974 PAS_TEMP_DR_POS 40;
BA_ "FlexKomSigName" SG_ 974 PAS_TEMP_DR_POS "GW_Dev";
BA_ "FlexKomSigStartPos" SG_ 974 PAS_TEMP_DR_POS 7;
BA_ "FlexKomSigStartValue" SG_ 974 PAS_TEMP_DR_POS "7F0F7F7F7Fh";
BA_ "GenSigCycleTime" SG_ 974 PAS_TEMP_DR_POS 1000;
BA_ "GenSigSendType" SG_ 974 PAS_TEMP_DR_POS 5;
BA_ "GenSigSNA" SG_ 974 PAS_TEMP_DR_POS "7Fh";
BA_ "GenSigStartValue" SG_ 974 PAS_TEMP_DR_POS 127;
BA_ "RID" SG_ 974 PAS_TEMP_DR_POS "1205";
BA_ "FlexKomComment" SG_ 901 IBS2_Q_received "LIN to CAN C IBS2 data";
BA_ "FlexKomIsMotorola" SG_ 901 IBS2_Q_received 1;
BA_ "FlexKomSID" SG_ 901 IBS2_Q_received 9208;
BA_ "FlexKomSigLaenge" SG_ 901 IBS2_Q_received 64;
BA_ "FlexKomSigName" SG_ 901 IBS2_Q_received "GW_IBS2_DataPkt";
BA_ "FlexKomSigStartPos" SG_ 901 IBS2_Q_received 7;
BA_ "FlexKomSigStartValue" SG_ 901 IBS2_Q_received "FFFFFFFF00000000h";
BA_ "GenSigCycleTime" SG_ 901 IBS2_Q_received 1000;
BA_ "GenSigSNA" SG_ 901 IBS2_Q_received "FFFFh";
BA_ "GenSigStartValue" SG_ 901 IBS2_Q_received 65535;
BA_ "RID" SG_ 901 IBS2_Q_received "9954";
BA_ "FlexKomComment" SG_ 901 IBS2_Q_released "LIN to CAN C IBS2 data";
BA_ "FlexKomIsMotorola" SG_ 901 IBS2_Q_released 1;
BA_ "FlexKomSID" SG_ 901 IBS2_Q_released 9208;
BA_ "FlexKomSigLaenge" SG_ 901 IBS2_Q_released 64;
BA_ "FlexKomSigName" SG_ 901 IBS2_Q_released "GW_IBS2_DataPkt";
BA_ "FlexKomSigStartPos" SG_ 901 IBS2_Q_released 7;
BA_ "FlexKomSigStartValue" SG_ 901 IBS2_Q_released "FFFFFFFF00000000h";
BA_ "GenSigCycleTime" SG_ 901 IBS2_Q_released 1000;
BA_ "GenSigSNA" SG_ 901 IBS2_Q_released "FFFFh";
BA_ "GenSigStartValue" SG_ 901 IBS2_Q_released 65535;
BA_ "RID" SG_ 901 IBS2_Q_released "9955";
BA_ "FlexKomComment" SG_ 901 IBS2_Tm_Lst_Reset_Days "LIN to CAN C IBS2 data";
BA_ "FlexKomIsMotorola" SG_ 901 IBS2_Tm_Lst_Reset_Days 1;
BA_ "FlexKomSID" SG_ 901 IBS2_Tm_Lst_Reset_Days 9208;
BA_ "FlexKomSigLaenge" SG_ 901 IBS2_Tm_Lst_Reset_Days 64;
BA_ "FlexKomSigName" SG_ 901 IBS2_Tm_Lst_Reset_Days "GW_IBS2_DataPkt";
BA_ "FlexKomSigStartPos" SG_ 901 IBS2_Tm_Lst_Reset_Days 7;
BA_ "FlexKomSigStartValue" SG_ 901 IBS2_Tm_Lst_Reset_Days "FFFFFFFF00000000h";
BA_ "GenSigCycleTime" SG_ 901 IBS2_Tm_Lst_Reset_Days 1000;
BA_ "GenSigSNA" SG_ 901 IBS2_Tm_Lst_Reset_Days "FFFh";
BA_ "RID" SG_ 901 IBS2_Tm_Lst_Reset_Days "9960";
BA_ "FlexKomComment" SG_ 901 IBS2_Tm_Lst_Reset_Sec "LIN to CAN C IBS2 data";
BA_ "FlexKomIsMotorola" SG_ 901 IBS2_Tm_Lst_Reset_Sec 1;
BA_ "FlexKomSID" SG_ 901 IBS2_Tm_Lst_Reset_Sec 9208;
BA_ "FlexKomSigLaenge" SG_ 901 IBS2_Tm_Lst_Reset_Sec 64;
BA_ "FlexKomSigName" SG_ 901 IBS2_Tm_Lst_Reset_Sec "GW_IBS2_DataPkt";
BA_ "FlexKomSigStartPos" SG_ 901 IBS2_Tm_Lst_Reset_Sec 7;
BA_ "FlexKomSigStartValue" SG_ 901 IBS2_Tm_Lst_Reset_Sec "FFFFFFFF00000000h";
BA_ "GenSigCycleTime" SG_ 901 IBS2_Tm_Lst_Reset_Sec 1000;
BA_ "GenSigSNA" SG_ 901 IBS2_Tm_Lst_Reset_Sec "FFFFh";
BA_ "RID" SG_ 901 IBS2_Tm_Lst_Reset_Sec "9959";
BA_ "FlexKomComment" SG_ 639 IBS_Q_received "LIN to CAN C IBS data";
BA_ "FlexKomIsMotorola" SG_ 639 IBS_Q_received 1;
BA_ "FlexKomSID" SG_ 639 IBS_Q_received 1855;
BA_ "FlexKomSigLaenge" SG_ 639 IBS_Q_received 64;
BA_ "FlexKomSigName" SG_ 639 IBS_Q_received "GW_IBS_DataPkt";
BA_ "FlexKomSigStartPos" SG_ 639 IBS_Q_received 7;
BA_ "FlexKomSigStartValue" SG_ 639 IBS_Q_received "FFFFFFFF00000000h";
BA_ "GenSigCycleTime" SG_ 639 IBS_Q_received 1000;
BA_ "GenSigSNA" SG_ 639 IBS_Q_received "FFFFh";
BA_ "GenSigStartValue" SG_ 639 IBS_Q_received 65535;
BA_ "RID" SG_ 639 IBS_Q_received "1817";
BA_ "FlexKomComment" SG_ 639 IBS_Q_released "LIN to CAN C IBS data";
BA_ "FlexKomIsMotorola" SG_ 639 IBS_Q_released 1;
BA_ "FlexKomSID" SG_ 639 IBS_Q_released 1855;
BA_ "FlexKomSigLaenge" SG_ 639 IBS_Q_released 64;
BA_ "FlexKomSigName" SG_ 639 IBS_Q_released "GW_IBS_DataPkt";
BA_ "FlexKomSigStartPos" SG_ 639 IBS_Q_released 7;
BA_ "FlexKomSigStartValue" SG_ 639 IBS_Q_released "FFFFFFFF00000000h";
BA_ "GenSigCycleTime" SG_ 639 IBS_Q_released 1000;
BA_ "GenSigSNA" SG_ 639 IBS_Q_released "FFFFh";
BA_ "GenSigStartValue" SG_ 639 IBS_Q_released 65535;
BA_ "RID" SG_ 639 IBS_Q_released "1815";
BA_ "FlexKomComment" SG_ 639 IBS_Tm_Lst_Reset_Days "LIN to CAN C IBS data";
BA_ "FlexKomIsMotorola" SG_ 639 IBS_Tm_Lst_Reset_Days 1;
BA_ "FlexKomSID" SG_ 639 IBS_Tm_Lst_Reset_Days 1855;
BA_ "FlexKomSigLaenge" SG_ 639 IBS_Tm_Lst_Reset_Days 64;
BA_ "FlexKomSigName" SG_ 639 IBS_Tm_Lst_Reset_Days "GW_IBS_DataPkt";
BA_ "FlexKomSigStartPos" SG_ 639 IBS_Tm_Lst_Reset_Days 7;
BA_ "FlexKomSigStartValue" SG_ 639 IBS_Tm_Lst_Reset_Days "FFFFFFFF00000000h";
BA_ "GenSigCycleTime" SG_ 639 IBS_Tm_Lst_Reset_Days 1000;
BA_ "GenSigSNA" SG_ 639 IBS_Tm_Lst_Reset_Days "FFFh";
BA_ "RID" SG_ 639 IBS_Tm_Lst_Reset_Days "1807";
BA_ "FlexKomComment" SG_ 639 IBS_Tm_Lst_Reset_Sec "LIN to CAN C IBS data";
BA_ "FlexKomIsMotorola" SG_ 639 IBS_Tm_Lst_Reset_Sec 1;
BA_ "FlexKomSID" SG_ 639 IBS_Tm_Lst_Reset_Sec 1855;
BA_ "FlexKomSigLaenge" SG_ 639 IBS_Tm_Lst_Reset_Sec 64;
BA_ "FlexKomSigName" SG_ 639 IBS_Tm_Lst_Reset_Sec "GW_IBS_DataPkt";
BA_ "FlexKomSigStartPos" SG_ 639 IBS_Tm_Lst_Reset_Sec 7;
BA_ "FlexKomSigStartValue" SG_ 639 IBS_Tm_Lst_Reset_Sec "FFFFFFFF00000000h";
BA_ "GenSigCycleTime" SG_ 639 IBS_Tm_Lst_Reset_Sec 1000;
BA_ "GenSigSNA" SG_ 639 IBS_Tm_Lst_Reset_Sec "FFFFh";
BA_ "RID" SG_ 639 IBS_Tm_Lst_Reset_Sec "1826";
BA_ "FlexKomComment" SG_ 816 AHB_ENBL "Auto highbeam enable";
BA_ "FlexKomIsMotorola" SG_ 816 AHB_ENBL 1;
BA_ "FlexKomSID" SG_ 816 AHB_ENBL 733;
BA_ "FlexKomSigLaenge" SG_ 816 AHB_ENBL 1;
BA_ "FlexKomSigName" SG_ 816 AHB_ENBL "AHB_ENBL";
BA_ "FlexKomSigStartPos" SG_ 816 AHB_ENBL 36;
BA_ "FlexKomSigStartValue" SG_ 816 AHB_ENBL "00h";
BA_ "GenSigCycleTime" SG_ 816 AHB_ENBL 1000;
BA_ "GenSigSendType" SG_ 816 AHB_ENBL 5;
BA_ "GenSigSNA" SG_ 816 AHB_ENBL "0h";
BA_ "GenSigTimeout_IC" SG_ 816 AHB_ENBL 10500;
BA_ "FlexKomComment" SG_ 816 ChargeReq "Request for scheduled charge; Charge now = [1]";
BA_ "FlexKomIsMotorola" SG_ 816 ChargeReq 1;
BA_ "FlexKomSID" SG_ 816 ChargeReq 2418;
BA_ "FlexKomSigLaenge" SG_ 816 ChargeReq 1;
BA_ "FlexKomSigName" SG_ 816 ChargeReq "ChargeReq";
BA_ "FlexKomSigStartPos" SG_ 816 ChargeReq 55;
BA_ "FlexKomSigStartValue" SG_ 816 ChargeReq "01h";
BA_ "GenSigCycleTime" SG_ 816 ChargeReq 1000;
BA_ "GenSigSendType" SG_ 816 ChargeReq 5;
BA_ "GenSigSNA" SG_ 816 ChargeReq "1h";
BA_ "GenSigStartValue" SG_ 816 ChargeReq 1;
BA_ "RID" SG_ 816 ChargeReq "2187 4465";
BA_ "FlexKomComment" SG_ 816 HVAC_CLNT_FLW_MIN "HVAC coolant flow minimum request";
BA_ "FlexKomIsMotorola" SG_ 816 HVAC_CLNT_FLW_MIN 1;
BA_ "FlexKomSID" SG_ 816 HVAC_CLNT_FLW_MIN 1527;
BA_ "FlexKomSigLaenge" SG_ 816 HVAC_CLNT_FLW_MIN 8;
BA_ "FlexKomSigName" SG_ 816 HVAC_CLNT_FLW_MIN "HVAC_CLNT_FLW_MIN";
BA_ "FlexKomSigStartPos" SG_ 816 HVAC_CLNT_FLW_MIN 47;
BA_ "FlexKomSigStartValue" SG_ 816 HVAC_CLNT_FLW_MIN "FFh";
BA_ "GenSigCycleTime" SG_ 816 HVAC_CLNT_FLW_MIN 1000;
BA_ "GenSigSendType" SG_ 816 HVAC_CLNT_FLW_MIN 5;
BA_ "GenSigSNA" SG_ 816 HVAC_CLNT_FLW_MIN "FFh";
BA_ "GenSigStartValue" SG_ 816 HVAC_CLNT_FLW_MIN 255;
BA_ "RID" SG_ 816 HVAC_CLNT_FLW_MIN "2885";
BA_ "FlexKomComment" SG_ 816 ICS_btn_16 "PPA pressed";
BA_ "FlexKomIsMotorola" SG_ 816 ICS_btn_16 1;
BA_ "FlexKomSID" SG_ 816 ICS_btn_16 1839;
BA_ "FlexKomSigLaenge" SG_ 816 ICS_btn_16 1;
BA_ "FlexKomSigName" SG_ 816 ICS_btn_16 "ICS_btn_16";
BA_ "FlexKomSigStartPos" SG_ 816 ICS_btn_16 51;
BA_ "FlexKomSigStartValue" SG_ 816 ICS_btn_16 "00h";
BA_ "GenSigCycleTime" SG_ 816 ICS_btn_16 1000;
BA_ "GenSigSendType" SG_ 816 ICS_btn_16 5;
BA_ "GenSigSNA" SG_ 816 ICS_btn_16 "0h";
BA_ "RID" SG_ 816 ICS_btn_16 "2085";
BA_ "FlexKomComment" SG_ 816 ICS_btn_17 "PTS Off pressed";
BA_ "FlexKomIsMotorola" SG_ 816 ICS_btn_17 1;
BA_ "FlexKomSID" SG_ 816 ICS_btn_17 1840;
BA_ "FlexKomSigLaenge" SG_ 816 ICS_btn_17 1;
BA_ "FlexKomSigName" SG_ 816 ICS_btn_17 "ICS_btn_17";
BA_ "FlexKomSigStartPos" SG_ 816 ICS_btn_17 52;
BA_ "FlexKomSigStartValue" SG_ 816 ICS_btn_17 "00h";
BA_ "GenSigCycleTime" SG_ 816 ICS_btn_17 1000;
BA_ "GenSigSendType" SG_ 816 ICS_btn_17 5;
BA_ "GenSigSNA" SG_ 816 ICS_btn_17 "0h";
BA_ "RID" SG_ 816 ICS_btn_17 "2096";
BA_ "FlexKomComment" SG_ 816 ICS_btn_18 "LDW Off pressed";
BA_ "FlexKomIsMotorola" SG_ 816 ICS_btn_18 1;
BA_ "FlexKomSID" SG_ 816 ICS_btn_18 1841;
BA_ "FlexKomSigLaenge" SG_ 816 ICS_btn_18 1;
BA_ "FlexKomSigName" SG_ 816 ICS_btn_18 "ICS_btn_18";
BA_ "FlexKomSigStartPos" SG_ 816 ICS_btn_18 53;
BA_ "FlexKomSigStartValue" SG_ 816 ICS_btn_18 "00h";
BA_ "GenSigCycleTime" SG_ 816 ICS_btn_18 1000;
BA_ "GenSigSendType" SG_ 816 ICS_btn_18 5;
BA_ "GenSigSNA" SG_ 816 ICS_btn_18 "0h";
BA_ "RID" SG_ 816 ICS_btn_18 "2090";
BA_ "FlexKomComment" SG_ 816 PLG_Stat "Power liftgate status";
BA_ "FlexKomIsMotorola" SG_ 816 PLG_Stat 1;
BA_ "FlexKomSID" SG_ 816 PLG_Stat 16;
BA_ "FlexKomSigLaenge" SG_ 816 PLG_Stat 4;
BA_ "FlexKomSigName" SG_ 816 PLG_Stat "PLG_Stat";
BA_ "FlexKomSigStartPos" SG_ 816 PLG_Stat 3;
BA_ "FlexKomSigStartValue" SG_ 816 PLG_Stat "00h";
BA_ "GenSigCycleTime" SG_ 816 PLG_Stat 1000;
BA_ "GenSigSendType" SG_ 816 PLG_Stat 5;
BA_ "GenSigSNA" SG_ 816 PLG_Stat "0h";
BA_ "GenSigTimeout_IC" SG_ 816 PLG_Stat 10500;
BA_ "RID" SG_ 816 PLG_Stat "1128";
BA_ "FlexKomComment" SG_ 816 TRAC_PSD "Traction on/off button pressed; [0] = Not Pressed,";
BA_ "FlexKomIsMotorola" SG_ 816 TRAC_PSD 1;
BA_ "FlexKomSID" SG_ 816 TRAC_PSD 424;
BA_ "FlexKomSigLaenge" SG_ 816 TRAC_PSD 1;
BA_ "FlexKomSigName" SG_ 816 TRAC_PSD "TRAC_PSD";
BA_ "FlexKomSigStartPos" SG_ 816 TRAC_PSD 19;
BA_ "FlexKomSigStartValue" SG_ 816 TRAC_PSD "00h";
BA_ "GenSigCycleTime" SG_ 816 TRAC_PSD 1000;
BA_ "GenSigSendType" SG_ 816 TRAC_PSD 5;
BA_ "GenSigSNA" SG_ 816 TRAC_PSD "0h";
BA_ "RID" SG_ 816 TRAC_PSD "1155";
BA_ "FlexKomComment" SG_ 816 phone_pop_up_active "Phone pop up is active; True = [1]";
BA_ "FlexKomIsMotorola" SG_ 816 phone_pop_up_active 1;
BA_ "FlexKomSID" SG_ 816 phone_pop_up_active 2527;
BA_ "FlexKomSigLaenge" SG_ 816 phone_pop_up_active 1;
BA_ "FlexKomSigName" SG_ 816 phone_pop_up_active "phone_pop_up_active";
BA_ "FlexKomSigStartPos" SG_ 816 phone_pop_up_active 30;
BA_ "FlexKomSigStartValue" SG_ 816 phone_pop_up_active "00h";
BA_ "GenSigCycleTime" SG_ 816 phone_pop_up_active 1000;
BA_ "GenSigSendType" SG_ 816 phone_pop_up_active 5;
BA_ "GenSigSNA" SG_ 816 phone_pop_up_active "0h";
BA_ "GenSigTimeout_IC" SG_ 816 phone_pop_up_active 10500;
BA_ "RID" SG_ 816 phone_pop_up_active "3052";
BA_ "FlexKomComment" SG_ 853 IBS_IBATT_QUIESCENT "Battery quiescent current";
BA_ "FlexKomIsMotorola" SG_ 853 IBS_IBATT_QUIESCENT 1;
BA_ "FlexKomSID" SG_ 853 IBS_IBATT_QUIESCENT 1854;
BA_ "FlexKomSigLaenge" SG_ 853 IBS_IBATT_QUIESCENT 8;
BA_ "FlexKomSigName" SG_ 853 IBS_IBATT_QUIESCENT "IBS_IBATT_QUIESCENT";
BA_ "FlexKomSigStartPos" SG_ 853 IBS_IBATT_QUIESCENT 63;
BA_ "FlexKomSigStartValue" SG_ 853 IBS_IBATT_QUIESCENT "FFh";
BA_ "GenSigCycleTime" SG_ 853 IBS_IBATT_QUIESCENT 1000;
BA_ "GenSigSNA" SG_ 853 IBS_IBATT_QUIESCENT "FFh";
BA_ "GenSigStartValue" SG_ 853 IBS_IBATT_QUIESCENT 255;
BA_ "RID" SG_ 853 IBS_IBATT_QUIESCENT "1808";
BA_ "FlexKomComment" SG_ 854 IBS2_IBATT_QUIESCENT "Battery 2 quiescent current";
BA_ "FlexKomIsMotorola" SG_ 854 IBS2_IBATT_QUIESCENT 1;
BA_ "FlexKomSID" SG_ 854 IBS2_IBATT_QUIESCENT 9812;
BA_ "FlexKomSigLaenge" SG_ 854 IBS2_IBATT_QUIESCENT 8;
BA_ "FlexKomSigName" SG_ 854 IBS2_IBATT_QUIESCENT "IBS2_IBATT_QUIESCENT";
BA_ "FlexKomSigStartPos" SG_ 854 IBS2_IBATT_QUIESCENT 63;
BA_ "FlexKomSigStartValue" SG_ 854 IBS2_IBATT_QUIESCENT "FFh";
BA_ "GenSigCycleTime" SG_ 854 IBS2_IBATT_QUIESCENT 1000;
BA_ "GenSigSNA" SG_ 854 IBS2_IBATT_QUIESCENT "FFh";
BA_ "GenSigStartValue" SG_ 854 IBS2_IBATT_QUIESCENT 255;
BA_ "RID" SG_ 854 IBS2_IBATT_QUIESCENT "9935";
BA_ "FlexKomComment" SG_ 799 IBS_R_Batt "Calculated battery resistance";
BA_ "FlexKomIsMotorola" SG_ 799 IBS_R_Batt 1;
BA_ "FlexKomSID" SG_ 799 IBS_R_Batt 1948;
BA_ "FlexKomSigLaenge" SG_ 799 IBS_R_Batt 16;
BA_ "FlexKomSigName" SG_ 799 IBS_R_Batt "IBS_R_Batt";
BA_ "FlexKomSigStartPos" SG_ 799 IBS_R_Batt 7;
BA_ "FlexKomSigStartValue" SG_ 799 IBS_R_Batt "07FFh";
BA_ "GenSigCycleTime" SG_ 799 IBS_R_Batt 1000;
BA_ "GenSigSNA" SG_ 799 IBS_R_Batt "7FFh";
BA_ "GenSigStartValue" SG_ 799 IBS_R_Batt 2047;
BA_ "RID" SG_ 799 IBS_R_Batt "1917";
BA_ "FlexKomComment" SG_ 799 IBS_R_Batt_25 "Batt resistance at 100% SOC and 25 degC";
BA_ "FlexKomIsMotorola" SG_ 799 IBS_R_Batt_25 1;
BA_ "FlexKomSID" SG_ 799 IBS_R_Batt_25 1947;
BA_ "FlexKomSigLaenge" SG_ 799 IBS_R_Batt_25 16;
BA_ "FlexKomSigName" SG_ 799 IBS_R_Batt_25 "IBS_R_Batt_25";
BA_ "FlexKomSigStartPos" SG_ 799 IBS_R_Batt_25 23;
BA_ "FlexKomSigStartValue" SG_ 799 IBS_R_Batt_25 "07FFh";
BA_ "GenSigCycleTime" SG_ 799 IBS_R_Batt_25 1000;
BA_ "GenSigSNA" SG_ 799 IBS_R_Batt_25 "7FFh";
BA_ "GenSigStartValue" SG_ 799 IBS_R_Batt_25 2047;
BA_ "RID" SG_ 799 IBS_R_Batt_25 "1912";
BA_ "FlexKomComment" SG_ 799 RainSensorFailSts "Fail present = 1";
BA_ "FlexKomIsMotorola" SG_ 799 RainSensorFailSts 1;
BA_ "FlexKomSID" SG_ 799 RainSensorFailSts 2046;
BA_ "FlexKomSigLaenge" SG_ 799 RainSensorFailSts 1;
BA_ "FlexKomSigName" SG_ 799 RainSensorFailSts "RainSensorFailSts";
BA_ "FlexKomSigStartPos" SG_ 799 RainSensorFailSts 63;
BA_ "FlexKomSigStartValue" SG_ 799 RainSensorFailSts "00h";
BA_ "GenSigCycleTime" SG_ 799 RainSensorFailSts 1000;
BA_ "GenSigSendType" SG_ 799 RainSensorFailSts 5;
BA_ "GenSigSNA" SG_ 799 RainSensorFailSts "0h";
BA_ "GenSigTimeout_IC" SG_ 799 RainSensorFailSts 10500;
BA_ "RID" SG_ 799 RainSensorFailSts "2039";
BA_ "FlexKomComment" SG_ 799 TGW_AUD_MD_CAB_DR "TGW audio mode for Cabin/Driver";
BA_ "FlexKomIsMotorola" SG_ 799 TGW_AUD_MD_CAB_DR 1;
BA_ "FlexKomSID" SG_ 799 TGW_AUD_MD_CAB_DR 672;
BA_ "FlexKomSigLaenge" SG_ 799 TGW_AUD_MD_CAB_DR 5;
BA_ "FlexKomSigName" SG_ 799 TGW_AUD_MD_CAB_DR "TGW_AUD_MD_CAB_DR";
BA_ "FlexKomSigStartPos" SG_ 799 TGW_AUD_MD_CAB_DR 7;
BA_ "FlexKomSigStartValue" SG_ 799 TGW_AUD_MD_CAB_DR "00h";
BA_ "GenSigCycleTime" SG_ 799 TGW_AUD_MD_CAB_DR 1000;
BA_ "GenSigSendType" SG_ 799 TGW_AUD_MD_CAB_DR 5;
BA_ "GenSigSNA" SG_ 799 TGW_AUD_MD_CAB_DR "1Fh";
BA_ "GenSigTimeout_IC" SG_ 799 TGW_AUD_MD_CAB_DR 10500;
BA_ "RID" SG_ 799 TGW_AUD_MD_CAB_DR "2058";
BA_ "FlexKomComment" SG_ 798 IBS2_R_Batt "Calculated battery resistance";
BA_ "FlexKomIsMotorola" SG_ 798 IBS2_R_Batt 1;
BA_ "FlexKomSID" SG_ 798 IBS2_R_Batt 9810;
BA_ "FlexKomSigLaenge" SG_ 798 IBS2_R_Batt 16;
BA_ "FlexKomSigName" SG_ 798 IBS2_R_Batt "IBS2_R_Batt";
BA_ "FlexKomSigStartPos" SG_ 798 IBS2_R_Batt 7;
BA_ "FlexKomSigStartValue" SG_ 798 IBS2_R_Batt "07FFh";
BA_ "GenSigCycleTime" SG_ 798 IBS2_R_Batt 1000;
BA_ "GenSigSNA" SG_ 798 IBS2_R_Batt "7FFh";
BA_ "GenSigStartValue" SG_ 798 IBS2_R_Batt 2047;
BA_ "RID" SG_ 798 IBS2_R_Batt "9957";
BA_ "FlexKomComment" SG_ 798 IBS2_R_Batt_25 "Batt resistance at 100% SOC and 25 degC";
BA_ "FlexKomIsMotorola" SG_ 798 IBS2_R_Batt_25 1;
BA_ "FlexKomSID" SG_ 798 IBS2_R_Batt_25 9811;
BA_ "FlexKomSigLaenge" SG_ 798 IBS2_R_Batt_25 16;
BA_ "FlexKomSigName" SG_ 798 IBS2_R_Batt_25 "IBS2_R_Batt_25";
BA_ "FlexKomSigStartPos" SG_ 798 IBS2_R_Batt_25 23;
BA_ "FlexKomSigStartValue" SG_ 798 IBS2_R_Batt_25 "07FFh";
BA_ "GenSigCycleTime" SG_ 798 IBS2_R_Batt_25 1000;
BA_ "GenSigSNA" SG_ 798 IBS2_R_Batt_25 "7FFh";
BA_ "GenSigStartValue" SG_ 798 IBS2_R_Batt_25 2047;
BA_ "RID" SG_ 798 IBS2_R_Batt_25 "9958";
BA_ "FlexKomComment" SG_ 817 PSD_LT_DisplayStat "Left power sliding door display status";
BA_ "FlexKomIsMotorola" SG_ 817 PSD_LT_DisplayStat 1;
BA_ "FlexKomSID" SG_ 817 PSD_LT_DisplayStat 2463;
BA_ "FlexKomSigLaenge" SG_ 817 PSD_LT_DisplayStat 4;
BA_ "FlexKomSigName" SG_ 817 PSD_LT_DisplayStat "PSD_LT_DisplayStat";
BA_ "FlexKomSigStartPos" SG_ 817 PSD_LT_DisplayStat 59;
BA_ "FlexKomSigStartValue" SG_ 817 PSD_LT_DisplayStat "00h";
BA_ "GenSigCycleTime" SG_ 817 PSD_LT_DisplayStat 1000;
BA_ "GenSigSendType" SG_ 817 PSD_LT_DisplayStat 5;
BA_ "GenSigSNA" SG_ 817 PSD_LT_DisplayStat "0h";
BA_ "GenSigTimeout_IC" SG_ 817 PSD_LT_DisplayStat 10500;
BA_ "RID" SG_ 817 PSD_LT_DisplayStat "2209";
BA_ "FlexKomComment" SG_ 817 PSD_RT_DisplayStat "Right power sliding door display status";
BA_ "FlexKomIsMotorola" SG_ 817 PSD_RT_DisplayStat 1;
BA_ "FlexKomSID" SG_ 817 PSD_RT_DisplayStat 2464;
BA_ "FlexKomSigLaenge" SG_ 817 PSD_RT_DisplayStat 4;
BA_ "FlexKomSigName" SG_ 817 PSD_RT_DisplayStat "PSD_RT_DisplayStat";
BA_ "FlexKomSigStartPos" SG_ 817 PSD_RT_DisplayStat 63;
BA_ "FlexKomSigStartValue" SG_ 817 PSD_RT_DisplayStat "00h";
BA_ "GenSigCycleTime" SG_ 817 PSD_RT_DisplayStat 1000;
BA_ "GenSigSendType" SG_ 817 PSD_RT_DisplayStat 5;
BA_ "GenSigSNA" SG_ 817 PSD_RT_DisplayStat "0h";
BA_ "GenSigTimeout_IC" SG_ 817 PSD_RT_DisplayStat 10500;
BA_ "RID" SG_ 817 PSD_RT_DisplayStat "3057";
BA_ "FlexKomComment" SG_ 579 Phone_Popup_setting_active "Phone call status popup active or not, Active=1";
BA_ "FlexKomIsMotorola" SG_ 579 Phone_Popup_setting_active 1;
BA_ "FlexKomSID" SG_ 579 Phone_Popup_setting_active 2745;
BA_ "FlexKomSigLaenge" SG_ 579 Phone_Popup_setting_active 1;
BA_ "FlexKomSigName" SG_ 579 Phone_Popup_setting_active "Phone_Popup_setting_active";
BA_ "FlexKomSigStartPos" SG_ 579 Phone_Popup_setting_active 55;
BA_ "FlexKomSigStartValue" SG_ 579 Phone_Popup_setting_active "00h";
BA_ "GenSigCycleTime" SG_ 579 Phone_Popup_setting_active 1000;
BA_ "GenSigSendType" SG_ 579 Phone_Popup_setting_active 5;
BA_ "GenSigSNA" SG_ 579 Phone_Popup_setting_active "0h";
BA_ "GenSigTimeout_IC" SG_ 579 Phone_Popup_setting_active 10500;
BA_ "RID" SG_ 579 Phone_Popup_setting_active "6384";
BA_ "FlexKomComment" SG_ 579 TGW_AUD_MD2_CAB_DR "TGW additional audio modes for Cabin/Driver";
BA_ "FlexKomIsMotorola" SG_ 579 TGW_AUD_MD2_CAB_DR 1;
BA_ "FlexKomSID" SG_ 579 TGW_AUD_MD2_CAB_DR 2717;
BA_ "FlexKomSigLaenge" SG_ 579 TGW_AUD_MD2_CAB_DR 6;
BA_ "FlexKomSigName" SG_ 579 TGW_AUD_MD2_CAB_DR "TGW_AUD_MD2_CAB_DR";
BA_ "FlexKomSigStartPos" SG_ 579 TGW_AUD_MD2_CAB_DR 29;
BA_ "FlexKomSigStartValue" SG_ 579 TGW_AUD_MD2_CAB_DR "00h";
BA_ "GenSigCycleTime" SG_ 579 TGW_AUD_MD2_CAB_DR 1000;
BA_ "GenSigSendType" SG_ 579 TGW_AUD_MD2_CAB_DR 5;
BA_ "GenSigSNA" SG_ 579 TGW_AUD_MD2_CAB_DR "3Fh";
BA_ "GenSigTimeout_IC" SG_ 579 TGW_AUD_MD2_CAB_DR 10500;
BA_ "RID" SG_ 579 TGW_AUD_MD2_CAB_DR "6336";
BA_ "FlexKomComment" SG_ 705 HVAC_Blwr_Perct "-";
BA_ "FlexKomIsMotorola" SG_ 705 HVAC_Blwr_Perct 1;
BA_ "FlexKomSID" SG_ 705 HVAC_Blwr_Perct 2511;
BA_ "FlexKomSigLaenge" SG_ 705 HVAC_Blwr_Perct 64;
BA_ "FlexKomSigName" SG_ 705 HVAC_Blwr_Perct "GW_LIN_I_C5_Pkt";
BA_ "FlexKomSigStartPos" SG_ 705 HVAC_Blwr_Perct 7;
BA_ "FlexKomSigStartValue" SG_ 705 HVAC_Blwr_Perct "0000FFFFFF7F7F7Fh";
BA_ "GenSigCycleTime" SG_ 705 HVAC_Blwr_Perct 1000;
BA_ "GenSigSendType" SG_ 705 HVAC_Blwr_Perct 5;
BA_ "GenSigSNA" SG_ 705 HVAC_Blwr_Perct "7Fh";
BA_ "GenSigStartValue" SG_ 705 HVAC_Blwr_Perct 127;
BA_ "RID" SG_ 705 HVAC_Blwr_Perct "2873";
BA_ "FlexKomComment" SG_ 705 HtrCorTmp_InTgt "-";
BA_ "FlexKomIsMotorola" SG_ 705 HtrCorTmp_InTgt 1;
BA_ "FlexKomSID" SG_ 705 HtrCorTmp_InTgt 2511;
BA_ "FlexKomSigLaenge" SG_ 705 HtrCorTmp_InTgt 64;
BA_ "FlexKomSigName" SG_ 705 HtrCorTmp_InTgt "GW_LIN_I_C5_Pkt";
BA_ "FlexKomSigStartPos" SG_ 705 HtrCorTmp_InTgt 7;
BA_ "FlexKomSigStartValue" SG_ 705 HtrCorTmp_InTgt "0000FFFFFF7F7F7Fh";
BA_ "GenSigCycleTime" SG_ 705 HtrCorTmp_InTgt 1000;
BA_ "GenSigSendType" SG_ 705 HtrCorTmp_InTgt 5;
BA_ "GenSigSNA" SG_ 705 HtrCorTmp_InTgt "FFh";
BA_ "GenSigStartValue" SG_ 705 HtrCorTmp_InTgt 255;
BA_ "RID" SG_ 705 HtrCorTmp_InTgt "2874";
BA_ "FlexKomComment" SG_ 705 R_Blw1_Pos "-";
BA_ "FlexKomIsMotorola" SG_ 705 R_Blw1_Pos 1;
BA_ "FlexKomSID" SG_ 705 R_Blw1_Pos 2511;
BA_ "FlexKomSigLaenge" SG_ 705 R_Blw1_Pos 64;
BA_ "FlexKomSigName" SG_ 705 R_Blw1_Pos "GW_LIN_I_C5_Pkt";
BA_ "FlexKomSigStartPos" SG_ 705 R_Blw1_Pos 7;
BA_ "FlexKomSigStartValue" SG_ 705 R_Blw1_Pos "0000FFFFFF7F7F7Fh";
BA_ "GenSigCycleTime" SG_ 705 R_Blw1_Pos 1000;
BA_ "GenSigSendType" SG_ 705 R_Blw1_Pos 5;
BA_ "GenSigSNA" SG_ 705 R_Blw1_Pos "7Fh";
BA_ "GenSigStartValue" SG_ 705 R_Blw1_Pos 127;
BA_ "RID" SG_ 705 R_Blw1_Pos "2875";
BA_ "FlexKomComment" SG_ 705 R_Temp1_Pos "-";
BA_ "FlexKomIsMotorola" SG_ 705 R_Temp1_Pos 1;
BA_ "FlexKomSID" SG_ 705 R_Temp1_Pos 2511;
BA_ "FlexKomSigLaenge" SG_ 705 R_Temp1_Pos 64;
BA_ "FlexKomSigName" SG_ 705 R_Temp1_Pos "GW_LIN_I_C5_Pkt";
BA_ "FlexKomSigStartPos" SG_ 705 R_Temp1_Pos 7;
BA_ "FlexKomSigStartValue" SG_ 705 R_Temp1_Pos "0000FFFFFF7F7F7Fh";
BA_ "GenSigCycleTime" SG_ 705 R_Temp1_Pos 1000;
BA_ "GenSigSendType" SG_ 705 R_Temp1_Pos 5;
BA_ "GenSigSNA" SG_ 705 R_Temp1_Pos "7Fh";
BA_ "GenSigStartValue" SG_ 705 R_Temp1_Pos 127;
BA_ "RID" SG_ 705 R_Temp1_Pos "2876";
BA_ "FlexKomComment" SG_ 705 VEH_INT_TEMP "-";
BA_ "FlexKomIsMotorola" SG_ 705 VEH_INT_TEMP 1;
BA_ "FlexKomSID" SG_ 705 VEH_INT_TEMP 2511;
BA_ "FlexKomSigLaenge" SG_ 705 VEH_INT_TEMP 64;
BA_ "FlexKomSigName" SG_ 705 VEH_INT_TEMP "GW_LIN_I_C5_Pkt";
BA_ "FlexKomSigStartPos" SG_ 705 VEH_INT_TEMP 7;
BA_ "FlexKomSigStartValue" SG_ 705 VEH_INT_TEMP "0000FFFFFF7F7F7Fh";
BA_ "GenSigCycleTime" SG_ 705 VEH_INT_TEMP 1000;
BA_ "GenSigSendType" SG_ 705 VEH_INT_TEMP 5;
BA_ "GenSigSNA" SG_ 705 VEH_INT_TEMP "FFFFh";
BA_ "GenSigStartValue" SG_ 705 VEH_INT_TEMP 65535;
BA_ "RID" SG_ 705 VEH_INT_TEMP "2879";
BA_ "FlexKomComment" SG_ 678 DispPopupSts "LDW message status in cluster";
BA_ "FlexKomIsMotorola" SG_ 678 DispPopupSts 1;
BA_ "FlexKomSID" SG_ 678 DispPopupSts 2019;
BA_ "FlexKomSigLaenge" SG_ 678 DispPopupSts 8;
BA_ "FlexKomSigName" SG_ 678 DispPopupSts "DispPopupSts";
BA_ "FlexKomSigStartPos" SG_ 678 DispPopupSts 31;
BA_ "FlexKomSigStartValue" SG_ 678 DispPopupSts "00h";
BA_ "GenSigCycleTime" SG_ 678 DispPopupSts 250;
BA_ "GenSigSNA" SG_ 678 DispPopupSts "FFh";
BA_ "GenSigTimeout_IC" SG_ 678 DispPopupSts 2625;
BA_ "FlexKomComment" SG_ 678 DisplaySts "LDW display status in cluster";
BA_ "FlexKomIsMotorola" SG_ 678 DisplaySts 1;
BA_ "FlexKomSID" SG_ 678 DisplaySts 2018;
BA_ "FlexKomSigLaenge" SG_ 678 DisplaySts 8;
BA_ "FlexKomSigName" SG_ 678 DisplaySts "DisplaySts";
BA_ "FlexKomSigStartPos" SG_ 678 DisplaySts 23;
BA_ "FlexKomSigStartValue" SG_ 678 DisplaySts "00h";
BA_ "GenSigCycleTime" SG_ 678 DisplaySts 250;
BA_ "GenSigSNA" SG_ 678 DisplaySts "FFh";
BA_ "GenSigTimeout_IC" SG_ 678 DisplaySts 2625;
BA_ "GenSigTimeout_ORC" SG_ 678 DisplaySts 875;
BA_ "FlexKomComment" SG_ 678 HALF_CHIME_REP_RATESts "LDW chime repetition rate; Continuous = [0]";
BA_ "FlexKomIsMotorola" SG_ 678 HALF_CHIME_REP_RATESts 1;
BA_ "FlexKomSID" SG_ 678 HALF_CHIME_REP_RATESts 2021;
BA_ "FlexKomSigLaenge" SG_ 678 HALF_CHIME_REP_RATESts 4;
BA_ "FlexKomSigName" SG_ 678 HALF_CHIME_REP_RATESts "HALF_CHIME_REP_RATESts";
BA_ "FlexKomSigStartPos" SG_ 678 HALF_CHIME_REP_RATESts 39;
BA_ "FlexKomSigStartValue" SG_ 678 HALF_CHIME_REP_RATESts "00h";
BA_ "GenSigCycleTime" SG_ 678 HALF_CHIME_REP_RATESts 250;
BA_ "GenSigSNA" SG_ 678 HALF_CHIME_REP_RATESts "0h";
BA_ "GenSigTimeout_CBC" SG_ 678 HALF_CHIME_REP_RATESts 2625;
BA_ "RID" SG_ 678 HALF_CHIME_REP_RATESts "2038";
BA_ "FlexKomComment" SG_ 678 HALF_CHIME_TYPESts "LDW chime type";
BA_ "FlexKomIsMotorola" SG_ 678 HALF_CHIME_TYPESts 1;
BA_ "FlexKomSID" SG_ 678 HALF_CHIME_TYPESts 2020;
BA_ "FlexKomSigLaenge" SG_ 678 HALF_CHIME_TYPESts 4;
BA_ "FlexKomSigName" SG_ 678 HALF_CHIME_TYPESts "HALF_CHIME_TYPESts";
BA_ "FlexKomSigStartPos" SG_ 678 HALF_CHIME_TYPESts 35;
BA_ "FlexKomSigStartValue" SG_ 678 HALF_CHIME_TYPESts "00h";
BA_ "GenSigCycleTime" SG_ 678 HALF_CHIME_TYPESts 250;
BA_ "GenSigSNA" SG_ 678 HALF_CHIME_TYPESts "Fh";
BA_ "GenSigTimeout_CBC" SG_ 678 HALF_CHIME_TYPESts 2625;
BA_ "RID" SG_ 678 HALF_CHIME_TYPESts "2017";
BA_ "FlexKomComment" SG_ 678 HALF_LF_CHIME_RQSts "LDW chime request for left side; true = [1]";
BA_ "FlexKomIsMotorola" SG_ 678 HALF_LF_CHIME_RQSts 1;
BA_ "FlexKomSID" SG_ 678 HALF_LF_CHIME_RQSts 2023;
BA_ "FlexKomSigLaenge" SG_ 678 HALF_LF_CHIME_RQSts 1;
BA_ "FlexKomSigName" SG_ 678 HALF_LF_CHIME_RQSts "HALF_LF_CHIME_RQSts";
BA_ "FlexKomSigStartPos" SG_ 678 HALF_LF_CHIME_RQSts 40;
BA_ "FlexKomSigStartValue" SG_ 678 HALF_LF_CHIME_RQSts "00h";
BA_ "GenSigCycleTime" SG_ 678 HALF_LF_CHIME_RQSts 250;
BA_ "GenSigSNA" SG_ 678 HALF_LF_CHIME_RQSts "0h";
BA_ "RID" SG_ 678 HALF_LF_CHIME_RQSts "2041";
BA_ "FlexKomComment" SG_ 678 HALF_RF_CHIME_RQSts "LDW chime request for right side; true = [1]";
BA_ "FlexKomIsMotorola" SG_ 678 HALF_RF_CHIME_RQSts 1;
BA_ "FlexKomSID" SG_ 678 HALF_RF_CHIME_RQSts 2022;
BA_ "FlexKomSigLaenge" SG_ 678 HALF_RF_CHIME_RQSts 1;
BA_ "FlexKomSigName" SG_ 678 HALF_RF_CHIME_RQSts "HALF_RF_CHIME_RQSts";
BA_ "FlexKomSigStartPos" SG_ 678 HALF_RF_CHIME_RQSts 41;
BA_ "FlexKomSigStartValue" SG_ 678 HALF_RF_CHIME_RQSts "00h";
BA_ "GenSigCycleTime" SG_ 678 HALF_RF_CHIME_RQSts 250;
BA_ "GenSigSNA" SG_ 678 HALF_RF_CHIME_RQSts "0h";
BA_ "RID" SG_ 678 HALF_RF_CHIME_RQSts "2020";
BA_ "FlexKomComment" SG_ 678 ISO_TelltaleSts "LDW telltale status in cluster";
BA_ "FlexKomIsMotorola" SG_ 678 ISO_TelltaleSts 1;
BA_ "FlexKomSID" SG_ 678 ISO_TelltaleSts 2015;
BA_ "FlexKomSigLaenge" SG_ 678 ISO_TelltaleSts 3;
BA_ "FlexKomSigName" SG_ 678 ISO_TelltaleSts "ISO_TelltaleSts";
BA_ "FlexKomSigStartPos" SG_ 678 ISO_TelltaleSts 2;
BA_ "FlexKomSigStartValue" SG_ 678 ISO_TelltaleSts "00h";
BA_ "GenSigCycleTime" SG_ 678 ISO_TelltaleSts 250;
BA_ "GenSigSNA" SG_ 678 ISO_TelltaleSts "7h";
BA_ "GenSigTimeout_IC" SG_ 678 ISO_TelltaleSts 2625;
BA_ "FlexKomComment" SG_ 678 SensitivitySts "LDW sensitivity level for display in cluster";
BA_ "FlexKomIsMotorola" SG_ 678 SensitivitySts 1;
BA_ "FlexKomSID" SG_ 678 SensitivitySts 2017;
BA_ "FlexKomSigLaenge" SG_ 678 SensitivitySts 3;
BA_ "FlexKomSigName" SG_ 678 SensitivitySts "SensitivitySts";
BA_ "FlexKomSigStartPos" SG_ 678 SensitivitySts 15;
BA_ "FlexKomSigStartValue" SG_ 678 SensitivitySts "00h";
BA_ "GenSigCycleTime" SG_ 678 SensitivitySts 250;
BA_ "GenSigSNA" SG_ 678 SensitivitySts "7h";
BA_ "GenSigTimeout_IC" SG_ 678 SensitivitySts 2625;
BA_ "FlexKomComment" SG_ 678 TrqIntensitySts "LDW torque intesity level for display in cluster";
BA_ "FlexKomIsMotorola" SG_ 678 TrqIntensitySts 1;
BA_ "FlexKomSID" SG_ 678 TrqIntensitySts 2016;
BA_ "FlexKomSigLaenge" SG_ 678 TrqIntensitySts 3;
BA_ "FlexKomSigName" SG_ 678 TrqIntensitySts "TrqIntensitySts";
BA_ "FlexKomSigStartPos" SG_ 678 TrqIntensitySts 12;
BA_ "FlexKomSigStartValue" SG_ 678 TrqIntensitySts "00h";
BA_ "GenSigCycleTime" SG_ 678 TrqIntensitySts 250;
BA_ "GenSigSNA" SG_ 678 TrqIntensitySts "7h";
BA_ "GenSigTimeout_IC" SG_ 678 TrqIntensitySts 2625;
BA_ "FlexKomComment" SG_ 658 CRC_292h "Half steering control packet";
BA_ "FlexKomIsMotorola" SG_ 658 CRC_292h 1;
BA_ "FlexKomSID" SG_ 658 CRC_292h 1908;
BA_ "FlexKomSigLaenge" SG_ 658 CRC_292h 48;
BA_ "FlexKomSigName" SG_ 658 CRC_292h "HaLF_StrCtrl";
BA_ "FlexKomSigStartPos" SG_ 658 CRC_292h 7;
BA_ "FlexKomSigStartValue" SG_ 658 CRC_292h "0000000000FFh";
BA_ "GenSigCycleTime" SG_ 658 CRC_292h 10;
BA_ "GenSigSNA" SG_ 658 CRC_292h "FFh";
BA_ "GenSigStartValue" SG_ 658 CRC_292h 255;
BA_ "FlexKomComment" SG_ 658 MC_292h "Half steering control packet";
BA_ "FlexKomIsMotorola" SG_ 658 MC_292h 1;
BA_ "FlexKomSID" SG_ 658 MC_292h 1908;
BA_ "FlexKomSigLaenge" SG_ 658 MC_292h 48;
BA_ "FlexKomSigName" SG_ 658 MC_292h "HaLF_StrCtrl";
BA_ "FlexKomSigStartPos" SG_ 658 MC_292h 7;
BA_ "FlexKomSigStartValue" SG_ 658 MC_292h "0000000000FFh";
BA_ "GenSigCycleTime" SG_ 658 MC_292h 10;
BA_ "GenSigSNA" SG_ 658 MC_292h "0h";
BA_ "FlexKomComment" SG_ 658 MTO_HALFDriveStyleSts "Half steering control packet";
BA_ "FlexKomIsMotorola" SG_ 658 MTO_HALFDriveStyleSts 1;
BA_ "FlexKomSID" SG_ 658 MTO_HALFDriveStyleSts 1908;
BA_ "FlexKomSigLaenge" SG_ 658 MTO_HALFDriveStyleSts 48;
BA_ "FlexKomSigName" SG_ 658 MTO_HALFDriveStyleSts "HaLF_StrCtrl";
BA_ "FlexKomSigStartPos" SG_ 658 MTO_HALFDriveStyleSts 7;
BA_ "FlexKomSigStartValue" SG_ 658 MTO_HALFDriveStyleSts "0000000000FFh";
BA_ "GenSigCycleTime" SG_ 658 MTO_HALFDriveStyleSts 10;
BA_ "GenSigSNA" SG_ 658 MTO_HALFDriveStyleSts "7h";
BA_ "FlexKomComment" SG_ 658 MTO_HALFSystemSts "Half steering control packet";
BA_ "FlexKomIsMotorola" SG_ 658 MTO_HALFSystemSts 1;
BA_ "FlexKomSID" SG_ 658 MTO_HALFSystemSts 1908;
BA_ "FlexKomSigLaenge" SG_ 658 MTO_HALFSystemSts 48;
BA_ "FlexKomSigName" SG_ 658 MTO_HALFSystemSts "HaLF_StrCtrl";
BA_ "FlexKomSigStartPos" SG_ 658 MTO_HALFSystemSts 7;
BA_ "FlexKomSigStartValue" SG_ 658 MTO_HALFSystemSts "0000000000FFh";
BA_ "GenSigCycleTime" SG_ 658 MTO_HALFSystemSts 10;
BA_ "GenSigSNA" SG_ 658 MTO_HALFSystemSts "0h";
BA_ "FlexKomComment" SG_ 658 MotorTorqueOverlayIntActivation "Half steering control packet";
BA_ "FlexKomIsMotorola" SG_ 658 MotorTorqueOverlayIntActivation 1;
BA_ "FlexKomSID" SG_ 658 MotorTorqueOverlayIntActivation 1908;
BA_ "FlexKomSigLaenge" SG_ 658 MotorTorqueOverlayIntActivation 48;
BA_ "FlexKomSigName" SG_ 658 MotorTorqueOverlayIntActivation "HaLF_StrCtrl";
BA_ "FlexKomSigStartPos" SG_ 658 MotorTorqueOverlayIntActivation 7;
BA_ "FlexKomSigStartValue" SG_ 658 MotorTorqueOverlayIntActivation "0000000000FFh";
BA_ "GenSigCycleTime" SG_ 658 MotorTorqueOverlayIntActivation 10;
BA_ "GenSigSNA" SG_ 658 MotorTorqueOverlayIntActivation "0h";
BA_ "FlexKomComment" SG_ 658 MotorTorqueOverlaySteeringReq "Half steering control packet";
BA_ "FlexKomIsMotorola" SG_ 658 MotorTorqueOverlaySteeringReq 1;
BA_ "FlexKomSID" SG_ 658 MotorTorqueOverlaySteeringReq 1908;
BA_ "FlexKomSigLaenge" SG_ 658 MotorTorqueOverlaySteeringReq 48;
BA_ "FlexKomSigName" SG_ 658 MotorTorqueOverlaySteeringReq "HaLF_StrCtrl";
BA_ "FlexKomSigStartPos" SG_ 658 MotorTorqueOverlaySteeringReq 7;
BA_ "FlexKomSigStartValue" SG_ 658 MotorTorqueOverlaySteeringReq "0000000000FFh";
BA_ "GenSigCycleTime" SG_ 658 MotorTorqueOverlaySteeringReq 10;
BA_ "GenSigSNA" SG_ 658 MotorTorqueOverlaySteeringReq "0h";
BA_ "FlexKomComment" SG_ 729 ConfigSts "Configuration status";
BA_ "FlexKomIsMotorola" SG_ 729 ConfigSts 1;
BA_ "FlexKomSID" SG_ 729 ConfigSts 1638;
BA_ "FlexKomSigLaenge" SG_ 729 ConfigSts 3;
BA_ "FlexKomSigName" SG_ 729 ConfigSts "ConfigSts";
BA_ "FlexKomSigStartPos" SG_ 729 ConfigSts 38;
BA_ "FlexKomSigStartValue" SG_ 729 ConfigSts "02h";
BA_ "GenSigCycleTime" SG_ 729 ConfigSts 100;
BA_ "GenSigSendType" SG_ 729 ConfigSts 5;
BA_ "GenSigSNA" SG_ 729 ConfigSts "7h";
BA_ "GenSigStartValue" SG_ 729 ConfigSts 2;
BA_ "RID" SG_ 729 ConfigSts "1622";
BA_ "FlexKomComment" SG_ 729 HALF_AHB_On "Auto high beam on request from the HALF ECU";
BA_ "FlexKomIsMotorola" SG_ 729 HALF_AHB_On 1;
BA_ "FlexKomSID" SG_ 729 HALF_AHB_On 1877;
BA_ "FlexKomSigLaenge" SG_ 729 HALF_AHB_On 1;
BA_ "FlexKomSigName" SG_ 729 HALF_AHB_On "HALF_AHB_On";
BA_ "FlexKomSigStartPos" SG_ 729 HALF_AHB_On 31;
BA_ "FlexKomSigStartValue" SG_ 729 HALF_AHB_On "00h";
BA_ "GenSigCycleTime" SG_ 729 HALF_AHB_On 100;
BA_ "GenSigSendType" SG_ 729 HALF_AHB_On 5;
BA_ "GenSigSNA" SG_ 729 HALF_AHB_On "0h";
BA_ "FlexKomComment" SG_ 729 LDW_LEDControlSts "LDW switch LED status";
BA_ "FlexKomIsMotorola" SG_ 729 LDW_LEDControlSts 1;
BA_ "FlexKomSID" SG_ 729 LDW_LEDControlSts 2024;
BA_ "FlexKomSigLaenge" SG_ 729 LDW_LEDControlSts 2;
BA_ "FlexKomSigName" SG_ 729 LDW_LEDControlSts "LDW_LEDControlSts";
BA_ "FlexKomSigStartPos" SG_ 729 LDW_LEDControlSts 25;
BA_ "FlexKomSigStartValue" SG_ 729 LDW_LEDControlSts "00h";
BA_ "GenSigCycleTime" SG_ 729 LDW_LEDControlSts 100;
BA_ "GenSigSendType" SG_ 729 LDW_LEDControlSts 5;
BA_ "GenSigSNA" SG_ 729 LDW_LEDControlSts "3h";
BA_ "GenSigTimeout_CBC" SG_ 729 LDW_LEDControlSts 1050;
BA_ "RID" SG_ 729 LDW_LEDControlSts "2019";
BA_ "FlexKomComment" SG_ 729 TorqueIntensitySts "LDW Torque Intesity Level";
BA_ "FlexKomIsMotorola" SG_ 729 TorqueIntensitySts 1;
BA_ "FlexKomSID" SG_ 729 TorqueIntensitySts 2025;
BA_ "FlexKomSigLaenge" SG_ 729 TorqueIntensitySts 3;
BA_ "FlexKomSigName" SG_ 729 TorqueIntensitySts "TorqueIntensitySts";
BA_ "FlexKomSigStartPos" SG_ 729 TorqueIntensitySts 28;
BA_ "FlexKomSigStartValue" SG_ 729 TorqueIntensitySts "00h";
BA_ "GenSigCycleTime" SG_ 729 TorqueIntensitySts 100;
BA_ "GenSigSendType" SG_ 729 TorqueIntensitySts 5;
BA_ "GenSigSNA" SG_ 729 TorqueIntensitySts "7h";
BA_ "GenSigTimeout_CBC" SG_ 729 TorqueIntensitySts 1050;
BA_ "RID" SG_ 729 TorqueIntensitySts "2037";
BA_ "FlexKomComment" SG_ 701 BatPwrUsage "HCP message 1 packet";
BA_ "FlexKomIsMotorola" SG_ 701 BatPwrUsage 1;
BA_ "FlexKomSID" SG_ 701 BatPwrUsage 2198;
BA_ "FlexKomSigLaenge" SG_ 701 BatPwrUsage 64;
BA_ "FlexKomSigName" SG_ 701 BatPwrUsage "HCP_1";
BA_ "FlexKomSigStartPos" SG_ 701 BatPwrUsage 7;
BA_ "FlexKomSigStartValue" SG_ 701 BatPwrUsage "7BFF0B0000FF01FFh";
BA_ "GenSigCycleTime" SG_ 701 BatPwrUsage 100;
BA_ "GenSigSNA" SG_ 701 BatPwrUsage "0h";
BA_ "GenSigTimeout_IC" SG_ 701 BatPwrUsage 1050;
BA_ "FlexKomComment" SG_ 701 BatPwrUsage_V "HCP message 1 packet";
BA_ "FlexKomIsMotorola" SG_ 701 BatPwrUsage_V 1;
BA_ "FlexKomSID" SG_ 701 BatPwrUsage_V 2198;
BA_ "FlexKomSigLaenge" SG_ 701 BatPwrUsage_V 64;
BA_ "FlexKomSigName" SG_ 701 BatPwrUsage_V "HCP_1";
BA_ "FlexKomSigStartPos" SG_ 701 BatPwrUsage_V 7;
BA_ "FlexKomSigStartValue" SG_ 701 BatPwrUsage_V "7BFF0B0000FF01FFh";
BA_ "GenSigCycleTime" SG_ 701 BatPwrUsage_V 100;
BA_ "GenSigSNA" SG_ 701 BatPwrUsage_V "0h";
BA_ "GenSigTimeout_IC" SG_ 701 BatPwrUsage_V 1050;
BA_ "FlexKomComment" SG_ 701 Est_Range "HCP message 1 packet";
BA_ "FlexKomIsMotorola" SG_ 701 Est_Range 1;
BA_ "FlexKomSID" SG_ 701 Est_Range 2198;
BA_ "FlexKomSigLaenge" SG_ 701 Est_Range 64;
BA_ "FlexKomSigName" SG_ 701 Est_Range "HCP_1";
BA_ "FlexKomSigStartPos" SG_ 701 Est_Range 7;
BA_ "FlexKomSigStartValue" SG_ 701 Est_Range "7BFF0B0000FF01FFh";
BA_ "GenSigCycleTime" SG_ 701 Est_Range 100;
BA_ "GenSigSNA" SG_ 701 Est_Range "FFh";
BA_ "GenSigStartValue" SG_ 701 Est_Range 255;
BA_ "GenSigTimeout_IC" SG_ 701 Est_Range 1050;
BA_ "FlexKomComment" SG_ 701 HEV_EVT_MD "HCP message 1 packet";
BA_ "FlexKomIsMotorola" SG_ 701 HEV_EVT_MD 1;
BA_ "FlexKomSID" SG_ 701 HEV_EVT_MD 2198;
BA_ "FlexKomSigLaenge" SG_ 701 HEV_EVT_MD 64;
BA_ "FlexKomSigName" SG_ 701 HEV_EVT_MD "HCP_1";
BA_ "FlexKomSigStartPos" SG_ 701 HEV_EVT_MD 7;
BA_ "FlexKomSigStartValue" SG_ 701 HEV_EVT_MD "7BFF0B0000FF01FFh";
BA_ "GenSigCycleTime" SG_ 701 HEV_EVT_MD 100;
BA_ "GenSigSNA" SG_ 701 HEV_EVT_MD "1h";
BA_ "GenSigStartValue" SG_ 701 HEV_EVT_MD 1;
BA_ "GenSigTimeout_CBC" SG_ 701 HEV_EVT_MD 10500;
BA_ "GenSigTimeout_IC" SG_ 701 HEV_EVT_MD 1050;
BA_ "RID" SG_ 701 HEV_EVT_MD "6517";
BA_ "FlexKomComment" SG_ 701 HEV_LMP_RQ "HCP message 1 packet";
BA_ "FlexKomIsMotorola" SG_ 701 HEV_LMP_RQ 1;
BA_ "FlexKomSID" SG_ 701 HEV_LMP_RQ 2198;
BA_ "FlexKomSigLaenge" SG_ 701 HEV_LMP_RQ 64;
BA_ "FlexKomSigName" SG_ 701 HEV_LMP_RQ "HCP_1";
BA_ "FlexKomSigStartPos" SG_ 701 HEV_LMP_RQ 7;
BA_ "FlexKomSigStartValue" SG_ 701 HEV_LMP_RQ "7BFF0B0000FF01FFh";
BA_ "GenSigCycleTime" SG_ 701 HEV_LMP_RQ 100;
BA_ "GenSigSNA" SG_ 701 HEV_LMP_RQ "3h";
BA_ "GenSigStartValue" SG_ 701 HEV_LMP_RQ 3;
BA_ "GenSigTimeout_IC" SG_ 701 HEV_LMP_RQ 1050;
BA_ "FlexKomComment" SG_ 701 R134a_PressSts "HCP message 1 packet";
BA_ "FlexKomIsMotorola" SG_ 701 R134a_PressSts 1;
BA_ "FlexKomSID" SG_ 701 R134a_PressSts 2198;
BA_ "FlexKomSigLaenge" SG_ 701 R134a_PressSts 64;
BA_ "FlexKomSigName" SG_ 701 R134a_PressSts "HCP_1";
BA_ "FlexKomSigStartPos" SG_ 701 R134a_PressSts 7;
BA_ "FlexKomSigStartValue" SG_ 701 R134a_PressSts "7BFF0B0000FF01FFh";
BA_ "GenSigCycleTime" SG_ 701 R134a_PressSts 100;
BA_ "GenSigSNA" SG_ 701 R134a_PressSts "1FFh";
BA_ "GenSigStartValue" SG_ 701 R134a_PressSts 511;
BA_ "GenSigTimeout_CBC" SG_ 701 R134a_PressSts 1050;
BA_ "RID" SG_ 701 R134a_PressSts "5059";
BA_ "FlexKomComment" SG_ 655 CabinPreCondReqStat "HCP 1000ms packet";
BA_ "FlexKomIsMotorola" SG_ 655 CabinPreCondReqStat 1;
BA_ "FlexKomSID" SG_ 655 CabinPreCondReqStat 2373;
BA_ "FlexKomSigLaenge" SG_ 655 CabinPreCondReqStat 64;
BA_ "FlexKomSigName" SG_ 655 CabinPreCondReqStat "HCP_1000";
BA_ "FlexKomSigStartPos" SG_ 655 CabinPreCondReqStat 7;
BA_ "FlexKomSigStartValue" SG_ 655 CabinPreCondReqStat "0000000000000000h";
BA_ "GenSigCycleTime" SG_ 655 CabinPreCondReqStat 1000;
BA_ "GenSigSendType" SG_ 655 CabinPreCondReqStat 5;
BA_ "GenSigSNA" SG_ 655 CabinPreCondReqStat "Fh";
BA_ "GenSigTimeout_CBC" SG_ 655 CabinPreCondReqStat 10500;
BA_ "RID" SG_ 655 CabinPreCondReqStat "2868";
BA_ "FlexKomComment" SG_ 655 ChargingLevel "HCP 1000ms packet";
BA_ "FlexKomIsMotorola" SG_ 655 ChargingLevel 1;
BA_ "FlexKomSID" SG_ 655 ChargingLevel 2373;
BA_ "FlexKomSigLaenge" SG_ 655 ChargingLevel 64;
BA_ "FlexKomSigName" SG_ 655 ChargingLevel "HCP_1000";
BA_ "FlexKomSigStartPos" SG_ 655 ChargingLevel 7;
BA_ "FlexKomSigStartValue" SG_ 655 ChargingLevel "0000000000000000h";
BA_ "GenSigCycleTime" SG_ 655 ChargingLevel 1000;
BA_ "GenSigSendType" SG_ 655 ChargingLevel 5;
BA_ "GenSigSNA" SG_ 655 ChargingLevel "Fh";
BA_ "GenSigTimeout_CBC" SG_ 655 ChargingLevel 10500;
BA_ "GenSigTimeout_IC" SG_ 655 ChargingLevel 10500;
BA_ "RID" SG_ 655 ChargingLevel "6518";
BA_ "FlexKomComment" SG_ 655 ChargingSysSts "HCP 1000ms packet";
BA_ "FlexKomIsMotorola" SG_ 655 ChargingSysSts 1;
BA_ "FlexKomSID" SG_ 655 ChargingSysSts 2373;
BA_ "FlexKomSigLaenge" SG_ 655 ChargingSysSts 64;
BA_ "FlexKomSigName" SG_ 655 ChargingSysSts "HCP_1000";
BA_ "FlexKomSigStartPos" SG_ 655 ChargingSysSts 7;
BA_ "FlexKomSigStartValue" SG_ 655 ChargingSysSts "0000000000000000h";
BA_ "GenSigCycleTime" SG_ 655 ChargingSysSts 1000;
BA_ "GenSigSendType" SG_ 655 ChargingSysSts 5;
BA_ "GenSigSNA" SG_ 655 ChargingSysSts "7h";
BA_ "GenSigTimeout_CBC" SG_ 655 ChargingSysSts 10500;
BA_ "GenSigTimeout_IC" SG_ 655 ChargingSysSts 10500;
BA_ "RID" SG_ 655 ChargingSysSts "6523";
BA_ "FlexKomComment" SG_ 655 ChrgSysFault "HCP 1000ms packet";
BA_ "FlexKomIsMotorola" SG_ 655 ChrgSysFault 1;
BA_ "FlexKomSID" SG_ 655 ChrgSysFault 2373;
BA_ "FlexKomSigLaenge" SG_ 655 ChrgSysFault 64;
BA_ "FlexKomSigName" SG_ 655 ChrgSysFault "HCP_1000";
BA_ "FlexKomSigStartPos" SG_ 655 ChrgSysFault 7;
BA_ "FlexKomSigStartValue" SG_ 655 ChrgSysFault "0000000000000000h";
BA_ "GenSigCycleTime" SG_ 655 ChrgSysFault 1000;
BA_ "GenSigSendType" SG_ 655 ChrgSysFault 5;
BA_ "GenSigSNA" SG_ 655 ChrgSysFault "0h";
BA_ "GenSigTimeout_IC" SG_ 655 ChrgSysFault 10500;
BA_ "FlexKomComment" SG_ 655 CompStat "HCP 1000ms packet";
BA_ "FlexKomIsMotorola" SG_ 655 CompStat 1;
BA_ "FlexKomSID" SG_ 655 CompStat 2373;
BA_ "FlexKomSigLaenge" SG_ 655 CompStat 64;
BA_ "FlexKomSigName" SG_ 655 CompStat "HCP_1000";
BA_ "FlexKomSigStartPos" SG_ 655 CompStat 7;
BA_ "FlexKomSigStartValue" SG_ 655 CompStat "0000000000000000h";
BA_ "GenSigCycleTime" SG_ 655 CompStat 1000;
BA_ "GenSigSendType" SG_ 655 CompStat 5;
BA_ "GenSigSNA" SG_ 655 CompStat "Fh";
BA_ "GenSigTimeout_CBC" SG_ 655 CompStat 10500;
BA_ "RID" SG_ 655 CompStat "3581 3587";
BA_ "FlexKomComment" SG_ 655 DriveReady "HCP 1000ms packet";
BA_ "FlexKomIsMotorola" SG_ 655 DriveReady 1;
BA_ "FlexKomSID" SG_ 655 DriveReady 2373;
BA_ "FlexKomSigLaenge" SG_ 655 DriveReady 64;
BA_ "FlexKomSigName" SG_ 655 DriveReady "HCP_1000";
BA_ "FlexKomSigStartPos" SG_ 655 DriveReady 7;
BA_ "FlexKomSigStartValue" SG_ 655 DriveReady "0000000000000000h";
BA_ "GenSigCycleTime" SG_ 655 DriveReady 1000;
BA_ "GenSigSendType" SG_ 655 DriveReady 5;
BA_ "GenSigSNA" SG_ 655 DriveReady "0h";
BA_ "GenSigTimeout_IC" SG_ 655 DriveReady 10500;
BA_ "FlexKomComment" SG_ 655 EstTimeofChrg_Lv1 "HCP 1000ms packet";
BA_ "FlexKomIsMotorola" SG_ 655 EstTimeofChrg_Lv1 1;
BA_ "FlexKomSID" SG_ 655 EstTimeofChrg_Lv1 2373;
BA_ "FlexKomSigLaenge" SG_ 655 EstTimeofChrg_Lv1 64;
BA_ "FlexKomSigName" SG_ 655 EstTimeofChrg_Lv1 "HCP_1000";
BA_ "FlexKomSigStartPos" SG_ 655 EstTimeofChrg_Lv1 7;
BA_ "FlexKomSigStartValue" SG_ 655 EstTimeofChrg_Lv1 "0000000000000000h";
BA_ "GenSigCycleTime" SG_ 655 EstTimeofChrg_Lv1 1000;
BA_ "GenSigSendType" SG_ 655 EstTimeofChrg_Lv1 5;
BA_ "GenSigSNA" SG_ 655 EstTimeofChrg_Lv1 "1FFFh";
BA_ "GenSigTimeout_CBC" SG_ 655 EstTimeofChrg_Lv1 10500;
BA_ "GenSigTimeout_IC" SG_ 655 EstTimeofChrg_Lv1 10500;
BA_ "RID" SG_ 655 EstTimeofChrg_Lv1 "6508";
BA_ "FlexKomComment" SG_ 655 EstTimeofChrg_Lv2 "HCP 1000ms packet";
BA_ "FlexKomIsMotorola" SG_ 655 EstTimeofChrg_Lv2 1;
BA_ "FlexKomSID" SG_ 655 EstTimeofChrg_Lv2 2373;
BA_ "FlexKomSigLaenge" SG_ 655 EstTimeofChrg_Lv2 64;
BA_ "FlexKomSigName" SG_ 655 EstTimeofChrg_Lv2 "HCP_1000";
BA_ "FlexKomSigStartPos" SG_ 655 EstTimeofChrg_Lv2 7;
BA_ "FlexKomSigStartValue" SG_ 655 EstTimeofChrg_Lv2 "0000000000000000h";
BA_ "GenSigCycleTime" SG_ 655 EstTimeofChrg_Lv2 1000;
BA_ "GenSigSendType" SG_ 655 EstTimeofChrg_Lv2 5;
BA_ "GenSigSNA" SG_ 655 EstTimeofChrg_Lv2 "7FFh";
BA_ "GenSigTimeout_CBC" SG_ 655 EstTimeofChrg_Lv2 10500;
BA_ "GenSigTimeout_IC" SG_ 655 EstTimeofChrg_Lv2 10500;
BA_ "RID" SG_ 655 EstTimeofChrg_Lv2 "6507";
BA_ "FlexKomComment" SG_ 655 HVBatCntctrStat "HCP 1000ms packet";
BA_ "FlexKomIsMotorola" SG_ 655 HVBatCntctrStat 1;
BA_ "FlexKomSID" SG_ 655 HVBatCntctrStat 2373;
BA_ "FlexKomSigLaenge" SG_ 655 HVBatCntctrStat 64;
BA_ "FlexKomSigName" SG_ 655 HVBatCntctrStat "HCP_1000";
BA_ "FlexKomSigStartPos" SG_ 655 HVBatCntctrStat 7;
BA_ "FlexKomSigStartValue" SG_ 655 HVBatCntctrStat "0000000000000000h";
BA_ "GenSigCycleTime" SG_ 655 HVBatCntctrStat 1000;
BA_ "GenSigSendType" SG_ 655 HVBatCntctrStat 5;
BA_ "GenSigSNA" SG_ 655 HVBatCntctrStat "7h";
BA_ "GenSigTimeout_IC" SG_ 655 HVBatCntctrStat 10500;
BA_ "FlexKomComment" SG_ 655 HtrCoreInletTemp "HCP 1000ms packet";
BA_ "FlexKomIsMotorola" SG_ 655 HtrCoreInletTemp 1;
BA_ "FlexKomSID" SG_ 655 HtrCoreInletTemp 2373;
BA_ "FlexKomSigLaenge" SG_ 655 HtrCoreInletTemp 64;
BA_ "FlexKomSigName" SG_ 655 HtrCoreInletTemp "HCP_1000";
BA_ "FlexKomSigStartPos" SG_ 655 HtrCoreInletTemp 7;
BA_ "FlexKomSigStartValue" SG_ 655 HtrCoreInletTemp "0000000000000000h";
BA_ "GenSigCycleTime" SG_ 655 HtrCoreInletTemp 1000;
BA_ "GenSigSendType" SG_ 655 HtrCoreInletTemp 5;
BA_ "GenSigSNA" SG_ 655 HtrCoreInletTemp "FFh";
BA_ "FlexKomComment" SG_ 655 MIL_OnRq_BPCM "HCP 1000ms packet";
BA_ "FlexKomIsMotorola" SG_ 655 MIL_OnRq_BPCM 1;
BA_ "FlexKomSID" SG_ 655 MIL_OnRq_BPCM 2373;
BA_ "FlexKomSigLaenge" SG_ 655 MIL_OnRq_BPCM 64;
BA_ "FlexKomSigName" SG_ 655 MIL_OnRq_BPCM "HCP_1000";
BA_ "FlexKomSigStartPos" SG_ 655 MIL_OnRq_BPCM 7;
BA_ "FlexKomSigStartValue" SG_ 655 MIL_OnRq_BPCM "0000000000000000h";
BA_ "GenSigCycleTime" SG_ 655 MIL_OnRq_BPCM 1000;
BA_ "GenSigSendType" SG_ 655 MIL_OnRq_BPCM 5;
BA_ "GenSigSNA" SG_ 655 MIL_OnRq_BPCM "0h";
BA_ "GenSigTimeout_IC" SG_ 655 MIL_OnRq_BPCM 10500;
BA_ "FlexKomComment" SG_ 655 PrplsnSysAtv "HCP 1000ms packet";
BA_ "FlexKomIsMotorola" SG_ 655 PrplsnSysAtv 1;
BA_ "FlexKomSID" SG_ 655 PrplsnSysAtv 2373;
BA_ "FlexKomSigLaenge" SG_ 655 PrplsnSysAtv 64;
BA_ "FlexKomSigName" SG_ 655 PrplsnSysAtv "HCP_1000";
BA_ "FlexKomSigStartPos" SG_ 655 PrplsnSysAtv 7;
BA_ "FlexKomSigStartValue" SG_ 655 PrplsnSysAtv "0000000000000000h";
BA_ "GenSigCycleTime" SG_ 655 PrplsnSysAtv 1000;
BA_ "GenSigSendType" SG_ 655 PrplsnSysAtv 5;
BA_ "GenSigSNA" SG_ 655 PrplsnSysAtv "0h";
BA_ "GenSigTimeout_IC" SG_ 655 PrplsnSysAtv 10500;
BA_ "RID" SG_ 655 PrplsnSysAtv "3065";
BA_ "FlexKomComment" SG_ 704 ElecClntHtrInletTemp "HCP message 2 packet";
BA_ "FlexKomIsMotorola" SG_ 704 ElecClntHtrInletTemp 1;
BA_ "FlexKomSID" SG_ 704 ElecClntHtrInletTemp 2512;
BA_ "FlexKomSigLaenge" SG_ 704 ElecClntHtrInletTemp 64;
BA_ "FlexKomSigName" SG_ 704 ElecClntHtrInletTemp "HCP_2";
BA_ "FlexKomSigStartPos" SG_ 704 ElecClntHtrInletTemp 7;
BA_ "FlexKomSigStartValue" SG_ 704 ElecClntHtrInletTemp "00001E000001FF00h";
BA_ "GenSigCycleTime" SG_ 704 ElecClntHtrInletTemp 1000;
BA_ "GenSigSendType" SG_ 704 ElecClntHtrInletTemp 5;
BA_ "GenSigSNA" SG_ 704 ElecClntHtrInletTemp "FFh";
BA_ "FlexKomComment" SG_ 704 ElecCoolantHtrPwr "HCP message 2 packet";
BA_ "FlexKomIsMotorola" SG_ 704 ElecCoolantHtrPwr 1;
BA_ "FlexKomSID" SG_ 704 ElecCoolantHtrPwr 2512;
BA_ "FlexKomSigLaenge" SG_ 704 ElecCoolantHtrPwr 64;
BA_ "FlexKomSigName" SG_ 704 ElecCoolantHtrPwr "HCP_2";
BA_ "FlexKomSigStartPos" SG_ 704 ElecCoolantHtrPwr 7;
BA_ "FlexKomSigStartValue" SG_ 704 ElecCoolantHtrPwr "00001E000001FF00h";
BA_ "GenSigCycleTime" SG_ 704 ElecCoolantHtrPwr 1000;
BA_ "GenSigSendType" SG_ 704 ElecCoolantHtrPwr 5;
BA_ "GenSigSNA" SG_ 704 ElecCoolantHtrPwr "FFh";
BA_ "GenSigTimeout_CBC" SG_ 704 ElecCoolantHtrPwr 10500;
BA_ "RID" SG_ 704 ElecCoolantHtrPwr "5018";
BA_ "FlexKomComment" SG_ 704 FRfShVlvSts "HCP message 2 packet";
BA_ "FlexKomIsMotorola" SG_ 704 FRfShVlvSts 1;
BA_ "FlexKomSID" SG_ 704 FRfShVlvSts 2512;
BA_ "FlexKomSigLaenge" SG_ 704 FRfShVlvSts 64;
BA_ "FlexKomSigName" SG_ 704 FRfShVlvSts "HCP_2";
BA_ "FlexKomSigStartPos" SG_ 704 FRfShVlvSts 7;
BA_ "FlexKomSigStartValue" SG_ 704 FRfShVlvSts "00001E000001FF00h";
BA_ "GenSigCycleTime" SG_ 704 FRfShVlvSts 1000;
BA_ "GenSigSendType" SG_ 704 FRfShVlvSts 5;
BA_ "GenSigSNA" SG_ 704 FRfShVlvSts "0h";
BA_ "RID" SG_ 704 FRfShVlvSts "2871";
BA_ "FlexKomComment" SG_ 704 HTAuxPmpMontrngRPM "HCP message 2 packet";
BA_ "FlexKomIsMotorola" SG_ 704 HTAuxPmpMontrngRPM 1;
BA_ "FlexKomSID" SG_ 704 HTAuxPmpMontrngRPM 2512;
BA_ "FlexKomSigLaenge" SG_ 704 HTAuxPmpMontrngRPM 64;
BA_ "FlexKomSigName" SG_ 704 HTAuxPmpMontrngRPM "HCP_2";
BA_ "FlexKomSigStartPos" SG_ 704 HTAuxPmpMontrngRPM 7;
BA_ "FlexKomSigStartValue" SG_ 704 HTAuxPmpMontrngRPM "00001E000001FF00h";
BA_ "GenSigCycleTime" SG_ 704 HTAuxPmpMontrngRPM 1000;
BA_ "GenSigSendType" SG_ 704 HTAuxPmpMontrngRPM 5;
BA_ "GenSigSNA" SG_ 704 HTAuxPmpMontrngRPM "3h";
BA_ "GenSigStartValue" SG_ 704 HTAuxPmpMontrngRPM 3;
BA_ "FlexKomComment" SG_ 704 HTAuxPmpRPMAct "HCP message 2 packet";
BA_ "FlexKomIsMotorola" SG_ 704 HTAuxPmpRPMAct 1;
BA_ "FlexKomSID" SG_ 704 HTAuxPmpRPMAct 2512;
BA_ "FlexKomSigLaenge" SG_ 704 HTAuxPmpRPMAct 64;
BA_ "FlexKomSigName" SG_ 704 HTAuxPmpRPMAct "HCP_2";
BA_ "FlexKomSigStartPos" SG_ 704 HTAuxPmpRPMAct 7;
BA_ "FlexKomSigStartValue" SG_ 704 HTAuxPmpRPMAct "00001E000001FF00h";
BA_ "GenSigCycleTime" SG_ 704 HTAuxPmpRPMAct 1000;
BA_ "GenSigSendType" SG_ 704 HTAuxPmpRPMAct 5;
BA_ "GenSigSNA" SG_ 704 HTAuxPmpRPMAct "FFh";
BA_ "GenSigTimeout_CBC" SG_ 704 HTAuxPmpRPMAct 10500;
BA_ "RID" SG_ 704 HTAuxPmpRPMAct "5020";
BA_ "FlexKomComment" SG_ 704 HTCabVlvPosn "HCP message 2 packet";
BA_ "FlexKomIsMotorola" SG_ 704 HTCabVlvPosn 1;
BA_ "FlexKomSID" SG_ 704 HTCabVlvPosn 2512;
BA_ "FlexKomSigLaenge" SG_ 704 HTCabVlvPosn 64;
BA_ "FlexKomSigName" SG_ 704 HTCabVlvPosn "HCP_2";
BA_ "FlexKomSigStartPos" SG_ 704 HTCabVlvPosn 7;
BA_ "FlexKomSigStartValue" SG_ 704 HTCabVlvPosn "00001E000001FF00h";
BA_ "GenSigCycleTime" SG_ 704 HTCabVlvPosn 1000;
BA_ "GenSigSendType" SG_ 704 HTCabVlvPosn 5;
BA_ "GenSigSNA" SG_ 704 HTCabVlvPosn "7Fh";
BA_ "GenSigTimeout_CBC" SG_ 704 HTCabVlvPosn 10500;
BA_ "RID" SG_ 704 HTCabVlvPosn "5017";
BA_ "FlexKomComment" SG_ 704 HTShtOffVlvReq "HCP message 2 packet";
BA_ "FlexKomIsMotorola" SG_ 704 HTShtOffVlvReq 1;
BA_ "FlexKomSID" SG_ 704 HTShtOffVlvReq 2512;
BA_ "FlexKomSigLaenge" SG_ 704 HTShtOffVlvReq 64;
BA_ "FlexKomSigName" SG_ 704 HTShtOffVlvReq "HCP_2";
BA_ "FlexKomSigStartPos" SG_ 704 HTShtOffVlvReq 7;
BA_ "FlexKomSigStartValue" SG_ 704 HTShtOffVlvReq "00001E000001FF00h";
BA_ "GenSigCycleTime" SG_ 704 HTShtOffVlvReq 1000;
BA_ "GenSigSendType" SG_ 704 HTShtOffVlvReq 5;
BA_ "GenSigSNA" SG_ 704 HTShtOffVlvReq "0h";
BA_ "RID" SG_ 704 HTShtOffVlvReq "3066";
BA_ "FlexKomComment" SG_ 704 HVBatCritCondT "HCP message 2 packet";
BA_ "FlexKomIsMotorola" SG_ 704 HVBatCritCondT 1;
BA_ "FlexKomSID" SG_ 704 HVBatCritCondT 2512;
BA_ "FlexKomSigLaenge" SG_ 704 HVBatCritCondT 64;
BA_ "FlexKomSigName" SG_ 704 HVBatCritCondT "HCP_2";
BA_ "FlexKomSigStartPos" SG_ 704 HVBatCritCondT 7;
BA_ "FlexKomSigStartValue" SG_ 704 HVBatCritCondT "00001E000001FF00h";
BA_ "GenSigCycleTime" SG_ 704 HVBatCritCondT 1000;
BA_ "GenSigSendType" SG_ 704 HVBatCritCondT 5;
BA_ "GenSigSNA" SG_ 704 HVBatCritCondT "0h";
BA_ "RID" SG_ 704 HVBatCritCondT "5019";
BA_ "FlexKomComment" SG_ 704 HVBat_CoolantLvlLo "HCP message 2 packet";
BA_ "FlexKomIsMotorola" SG_ 704 HVBat_CoolantLvlLo 1;
BA_ "FlexKomSID" SG_ 704 HVBat_CoolantLvlLo 2512;
BA_ "FlexKomSigLaenge" SG_ 704 HVBat_CoolantLvlLo 64;
BA_ "FlexKomSigName" SG_ 704 HVBat_CoolantLvlLo "HCP_2";
BA_ "FlexKomSigStartPos" SG_ 704 HVBat_CoolantLvlLo 7;
BA_ "FlexKomSigStartValue" SG_ 704 HVBat_CoolantLvlLo "00001E000001FF00h";
BA_ "GenSigCycleTime" SG_ 704 HVBat_CoolantLvlLo 1000;
BA_ "GenSigSendType" SG_ 704 HVBat_CoolantLvlLo 5;
BA_ "GenSigSNA" SG_ 704 HVBat_CoolantLvlLo "3h";
BA_ "GenSigStartValue" SG_ 704 HVBat_CoolantLvlLo 3;
BA_ "GenSigTimeout_IC" SG_ 704 HVBat_CoolantLvlLo 10500;
BA_ "FlexKomComment" SG_ 654 HCPCoachDisp "HCP_C1_Pkt message packet";
BA_ "FlexKomIsMotorola" SG_ 654 HCPCoachDisp 1;
BA_ "FlexKomSID" SG_ 654 HCPCoachDisp 2374;
BA_ "FlexKomSigLaenge" SG_ 654 HCPCoachDisp 64;
BA_ "FlexKomSigName" SG_ 654 HCPCoachDisp "HCP_C1_Pkt";
BA_ "FlexKomSigStartPos" SG_ 654 HCPCoachDisp 7;
BA_ "FlexKomSigStartValue" SG_ 654 HCPCoachDisp "00000000646400FFh";
BA_ "GenSigCycleTime" SG_ 654 HCPCoachDisp 100;
BA_ "GenSigSNA" SG_ 654 HCPCoachDisp "64h";
BA_ "GenSigStartValue" SG_ 654 HCPCoachDisp 100;
BA_ "GenSigTimeout_IC" SG_ 654 HCPCoachDisp 1050;
BA_ "FlexKomComment" SG_ 654 HCPCoachDispV "HCP_C1_Pkt message packet";
BA_ "FlexKomIsMotorola" SG_ 654 HCPCoachDispV 1;
BA_ "FlexKomSID" SG_ 654 HCPCoachDispV 2374;
BA_ "FlexKomSigLaenge" SG_ 654 HCPCoachDispV 64;
BA_ "FlexKomSigName" SG_ 654 HCPCoachDispV "HCP_C1_Pkt";
BA_ "FlexKomSigStartPos" SG_ 654 HCPCoachDispV 7;
BA_ "FlexKomSigStartValue" SG_ 654 HCPCoachDispV "00000000646400FFh";
BA_ "GenSigCycleTime" SG_ 654 HCPCoachDispV 100;
BA_ "GenSigSNA" SG_ 654 HCPCoachDispV "0h";
BA_ "GenSigTimeout_IC" SG_ 654 HCPCoachDispV 1050;
BA_ "FlexKomComment" SG_ 654 HCPOutputPwr "HCP_C1_Pkt message packet";
BA_ "FlexKomIsMotorola" SG_ 654 HCPOutputPwr 1;
BA_ "FlexKomSID" SG_ 654 HCPOutputPwr 2374;
BA_ "FlexKomSigLaenge" SG_ 654 HCPOutputPwr 64;
BA_ "FlexKomSigName" SG_ 654 HCPOutputPwr "HCP_C1_Pkt";
BA_ "FlexKomSigStartPos" SG_ 654 HCPOutputPwr 7;
BA_ "FlexKomSigStartValue" SG_ 654 HCPOutputPwr "00000000646400FFh";
BA_ "GenSigCycleTime" SG_ 654 HCPOutputPwr 100;
BA_ "GenSigSNA" SG_ 654 HCPOutputPwr "64h";
BA_ "GenSigStartValue" SG_ 654 HCPOutputPwr 100;
BA_ "GenSigTimeout_IC" SG_ 654 HCPOutputPwr 1050;
BA_ "FlexKomComment" SG_ 654 HCPOutputPwrV "HCP_C1_Pkt message packet";
BA_ "FlexKomIsMotorola" SG_ 654 HCPOutputPwrV 1;
BA_ "FlexKomSID" SG_ 654 HCPOutputPwrV 2374;
BA_ "FlexKomSigLaenge" SG_ 654 HCPOutputPwrV 64;
BA_ "FlexKomSigName" SG_ 654 HCPOutputPwrV "HCP_C1_Pkt";
BA_ "FlexKomSigStartPos" SG_ 654 HCPOutputPwrV 7;
BA_ "FlexKomSigStartValue" SG_ 654 HCPOutputPwrV "00000000646400FFh";
BA_ "GenSigCycleTime" SG_ 654 HCPOutputPwrV 100;
BA_ "GenSigSNA" SG_ 654 HCPOutputPwrV "0h";
BA_ "GenSigTimeout_IC" SG_ 654 HCPOutputPwrV 1050;
BA_ "FlexKomComment" SG_ 654 HCPPopUpMessage1 "HCP_C1_Pkt message packet";
BA_ "FlexKomIsMotorola" SG_ 654 HCPPopUpMessage1 1;
BA_ "FlexKomSID" SG_ 654 HCPPopUpMessage1 2374;
BA_ "FlexKomSigLaenge" SG_ 654 HCPPopUpMessage1 64;
BA_ "FlexKomSigName" SG_ 654 HCPPopUpMessage1 "HCP_C1_Pkt";
BA_ "FlexKomSigStartPos" SG_ 654 HCPPopUpMessage1 7;
BA_ "FlexKomSigStartValue" SG_ 654 HCPPopUpMessage1 "00000000646400FFh";
BA_ "GenSigCycleTime" SG_ 654 HCPPopUpMessage1 100;
BA_ "GenSigSNA" SG_ 654 HCPPopUpMessage1 "0h";
BA_ "GenSigTimeout_IC" SG_ 654 HCPPopUpMessage1 1050;
BA_ "FlexKomComment" SG_ 654 HCPPopUpMessage2 "HCP_C1_Pkt message packet";
BA_ "FlexKomIsMotorola" SG_ 654 HCPPopUpMessage2 1;
BA_ "FlexKomSID" SG_ 654 HCPPopUpMessage2 2374;
BA_ "FlexKomSigLaenge" SG_ 654 HCPPopUpMessage2 64;
BA_ "FlexKomSigName" SG_ 654 HCPPopUpMessage2 "HCP_C1_Pkt";
BA_ "FlexKomSigStartPos" SG_ 654 HCPPopUpMessage2 7;
BA_ "FlexKomSigStartValue" SG_ 654 HCPPopUpMessage2 "00000000646400FFh";
BA_ "GenSigCycleTime" SG_ 654 HCPPopUpMessage2 100;
BA_ "GenSigSNA" SG_ 654 HCPPopUpMessage2 "0h";
BA_ "GenSigTimeout_IC" SG_ 654 HCPPopUpMessage2 1050;
BA_ "FlexKomComment" SG_ 654 HCPPopUpMessage3 "HCP_C1_Pkt message packet";
BA_ "FlexKomIsMotorola" SG_ 654 HCPPopUpMessage3 1;
BA_ "FlexKomSID" SG_ 654 HCPPopUpMessage3 2374;
BA_ "FlexKomSigLaenge" SG_ 654 HCPPopUpMessage3 64;
BA_ "FlexKomSigName" SG_ 654 HCPPopUpMessage3 "HCP_C1_Pkt";
BA_ "FlexKomSigStartPos" SG_ 654 HCPPopUpMessage3 7;
BA_ "FlexKomSigStartValue" SG_ 654 HCPPopUpMessage3 "00000000646400FFh";
BA_ "GenSigCycleTime" SG_ 654 HCPPopUpMessage3 100;
BA_ "GenSigSNA" SG_ 654 HCPPopUpMessage3 "0h";
BA_ "GenSigTimeout_IC" SG_ 654 HCPPopUpMessage3 1050;
BA_ "FlexKomComment" SG_ 654 HCPPopUpMessage4 "HCP_C1_Pkt message packet";
BA_ "FlexKomIsMotorola" SG_ 654 HCPPopUpMessage4 1;
BA_ "FlexKomSID" SG_ 654 HCPPopUpMessage4 2374;
BA_ "FlexKomSigLaenge" SG_ 654 HCPPopUpMessage4 64;
BA_ "FlexKomSigName" SG_ 654 HCPPopUpMessage4 "HCP_C1_Pkt";
BA_ "FlexKomSigStartPos" SG_ 654 HCPPopUpMessage4 7;
BA_ "FlexKomSigStartValue" SG_ 654 HCPPopUpMessage4 "00000000646400FFh";
BA_ "GenSigCycleTime" SG_ 654 HCPPopUpMessage4 100;
BA_ "GenSigSNA" SG_ 654 HCPPopUpMessage4 "0h";
BA_ "GenSigTimeout_IC" SG_ 654 HCPPopUpMessage4 1050;
BA_ "FlexKomComment" SG_ 654 HCPPopUpMessage5 "HCP_C1_Pkt message packet";
BA_ "FlexKomIsMotorola" SG_ 654 HCPPopUpMessage5 1;
BA_ "FlexKomSID" SG_ 654 HCPPopUpMessage5 2374;
BA_ "FlexKomSigLaenge" SG_ 654 HCPPopUpMessage5 64;
BA_ "FlexKomSigName" SG_ 654 HCPPopUpMessage5 "HCP_C1_Pkt";
BA_ "FlexKomSigStartPos" SG_ 654 HCPPopUpMessage5 7;
BA_ "FlexKomSigStartValue" SG_ 654 HCPPopUpMessage5 "00000000646400FFh";
BA_ "GenSigCycleTime" SG_ 654 HCPPopUpMessage5 100;
BA_ "GenSigSNA" SG_ 654 HCPPopUpMessage5 "0h";
BA_ "GenSigTimeout_IC" SG_ 654 HCPPopUpMessage5 1050;
BA_ "FlexKomComment" SG_ 654 HCPPopUpMessage6 "HCP_C1_Pkt message packet";
BA_ "FlexKomIsMotorola" SG_ 654 HCPPopUpMessage6 1;
BA_ "FlexKomSID" SG_ 654 HCPPopUpMessage6 2374;
BA_ "FlexKomSigLaenge" SG_ 654 HCPPopUpMessage6 64;
BA_ "FlexKomSigName" SG_ 654 HCPPopUpMessage6 "HCP_C1_Pkt";
BA_ "FlexKomSigStartPos" SG_ 654 HCPPopUpMessage6 7;
BA_ "FlexKomSigStartValue" SG_ 654 HCPPopUpMessage6 "00000000646400FFh";
BA_ "GenSigCycleTime" SG_ 654 HCPPopUpMessage6 100;
BA_ "GenSigSNA" SG_ 654 HCPPopUpMessage6 "0h";
BA_ "GenSigTimeout_IC" SG_ 654 HCPPopUpMessage6 1050;
BA_ "FlexKomComment" SG_ 654 HCPPopUpMessage7 "HCP_C1_Pkt message packet";
BA_ "FlexKomIsMotorola" SG_ 654 HCPPopUpMessage7 1;
BA_ "FlexKomSID" SG_ 654 HCPPopUpMessage7 2374;
BA_ "FlexKomSigLaenge" SG_ 654 HCPPopUpMessage7 64;
BA_ "FlexKomSigName" SG_ 654 HCPPopUpMessage7 "HCP_C1_Pkt";
BA_ "FlexKomSigStartPos" SG_ 654 HCPPopUpMessage7 7;
BA_ "FlexKomSigStartValue" SG_ 654 HCPPopUpMessage7 "00000000646400FFh";
BA_ "GenSigCycleTime" SG_ 654 HCPPopUpMessage7 100;
BA_ "GenSigSNA" SG_ 654 HCPPopUpMessage7 "0h";
BA_ "GenSigTimeout_IC" SG_ 654 HCPPopUpMessage7 1050;
BA_ "FlexKomComment" SG_ 654 HCPPopUpMessage9 "HCP_C1_Pkt message packet";
BA_ "FlexKomIsMotorola" SG_ 654 HCPPopUpMessage9 1;
BA_ "FlexKomSID" SG_ 654 HCPPopUpMessage9 2374;
BA_ "FlexKomSigLaenge" SG_ 654 HCPPopUpMessage9 64;
BA_ "FlexKomSigName" SG_ 654 HCPPopUpMessage9 "HCP_C1_Pkt";
BA_ "FlexKomSigStartPos" SG_ 654 HCPPopUpMessage9 7;
BA_ "FlexKomSigStartValue" SG_ 654 HCPPopUpMessage9 "00000000646400FFh";
BA_ "GenSigCycleTime" SG_ 654 HCPPopUpMessage9 100;
BA_ "GenSigSNA" SG_ 654 HCPPopUpMessage9 "0h";
BA_ "FlexKomComment" SG_ 654 HybSysEmsMlfAtv "HCP_C1_Pkt message packet";
BA_ "FlexKomIsMotorola" SG_ 654 HybSysEmsMlfAtv 1;
BA_ "FlexKomSID" SG_ 654 HybSysEmsMlfAtv 2374;
BA_ "FlexKomSigLaenge" SG_ 654 HybSysEmsMlfAtv 64;
BA_ "FlexKomSigName" SG_ 654 HybSysEmsMlfAtv "HCP_C1_Pkt";
BA_ "FlexKomSigStartPos" SG_ 654 HybSysEmsMlfAtv 7;
BA_ "FlexKomSigStartValue" SG_ 654 HybSysEmsMlfAtv "00000000646400FFh";
BA_ "GenSigCycleTime" SG_ 654 HybSysEmsMlfAtv 100;
BA_ "GenSigSNA" SG_ 654 HybSysEmsMlfAtv "0h";
BA_ "FlexKomComment" SG_ 654 MIL_OnRq_HCP "HCP_C1_Pkt message packet";
BA_ "FlexKomIsMotorola" SG_ 654 MIL_OnRq_HCP 1;
BA_ "FlexKomSID" SG_ 654 MIL_OnRq_HCP 2374;
BA_ "FlexKomSigLaenge" SG_ 654 MIL_OnRq_HCP 64;
BA_ "FlexKomSigName" SG_ 654 MIL_OnRq_HCP "HCP_C1_Pkt";
BA_ "FlexKomSigStartPos" SG_ 654 MIL_OnRq_HCP 7;
BA_ "FlexKomSigStartValue" SG_ 654 MIL_OnRq_HCP "00000000646400FFh";
BA_ "GenSigCycleTime" SG_ 654 MIL_OnRq_HCP 100;
BA_ "GenSigSNA" SG_ 654 MIL_OnRq_HCP "0h";
BA_ "FlexKomComment" SG_ 878 BatPwrUsageDisp "HCP Info for Display";
BA_ "FlexKomIsMotorola" SG_ 878 BatPwrUsageDisp 1;
BA_ "FlexKomSID" SG_ 878 BatPwrUsageDisp 2549;
BA_ "FlexKomSigLaenge" SG_ 878 BatPwrUsageDisp 64;
BA_ "FlexKomSigName" SG_ 878 BatPwrUsageDisp "HCP_DISP";
BA_ "FlexKomSigStartPos" SG_ 878 BatPwrUsageDisp 7;
BA_ "FlexKomSigStartValue" SG_ 878 BatPwrUsageDisp "0000000000000000h";
BA_ "GenSigCycleTime" SG_ 878 BatPwrUsageDisp 500;
BA_ "GenSigSNA" SG_ 878 BatPwrUsageDisp "0h";
BA_ "GenSigTimeout_CBC" SG_ 878 BatPwrUsageDisp 10500;
BA_ "RID" SG_ 878 BatPwrUsageDisp "6520";
BA_ "FlexKomComment" SG_ 878 BatPwrUsageDisp_V "HCP Info for Display";
BA_ "FlexKomIsMotorola" SG_ 878 BatPwrUsageDisp_V 1;
BA_ "FlexKomSID" SG_ 878 BatPwrUsageDisp_V 2549;
BA_ "FlexKomSigLaenge" SG_ 878 BatPwrUsageDisp_V 64;
BA_ "FlexKomSigName" SG_ 878 BatPwrUsageDisp_V "HCP_DISP";
BA_ "FlexKomSigStartPos" SG_ 878 BatPwrUsageDisp_V 7;
BA_ "FlexKomSigStartValue" SG_ 878 BatPwrUsageDisp_V "0000000000000000h";
BA_ "GenSigCycleTime" SG_ 878 BatPwrUsageDisp_V 500;
BA_ "GenSigSNA" SG_ 878 BatPwrUsageDisp_V "0h";
BA_ "GenSigTimeout_CBC" SG_ 878 BatPwrUsageDisp_V 10500;
BA_ "RID" SG_ 878 BatPwrUsageDisp_V "6509";
BA_ "FlexKomComment" SG_ 878 EngPwrUsageDisp "HCP Info for Display";
BA_ "FlexKomIsMotorola" SG_ 878 EngPwrUsageDisp 1;
BA_ "FlexKomSID" SG_ 878 EngPwrUsageDisp 2549;
BA_ "FlexKomSigLaenge" SG_ 878 EngPwrUsageDisp 64;
BA_ "FlexKomSigName" SG_ 878 EngPwrUsageDisp "HCP_DISP";
BA_ "FlexKomSigStartPos" SG_ 878 EngPwrUsageDisp 7;
BA_ "FlexKomSigStartValue" SG_ 878 EngPwrUsageDisp "0000000000000000h";
BA_ "GenSigCycleTime" SG_ 878 EngPwrUsageDisp 500;
BA_ "GenSigSNA" SG_ 878 EngPwrUsageDisp "0h";
BA_ "GenSigTimeout_CBC" SG_ 878 EngPwrUsageDisp 10500;
BA_ "RID" SG_ 878 EngPwrUsageDisp "6506";
BA_ "FlexKomComment" SG_ 878 EngPwrUsageDisp_V "HCP Info for Display";
BA_ "FlexKomIsMotorola" SG_ 878 EngPwrUsageDisp_V 1;
BA_ "FlexKomSID" SG_ 878 EngPwrUsageDisp_V 2549;
BA_ "FlexKomSigLaenge" SG_ 878 EngPwrUsageDisp_V 64;
BA_ "FlexKomSigName" SG_ 878 EngPwrUsageDisp_V "HCP_DISP";
BA_ "FlexKomSigStartPos" SG_ 878 EngPwrUsageDisp_V 7;
BA_ "FlexKomSigStartValue" SG_ 878 EngPwrUsageDisp_V "0000000000000000h";
BA_ "GenSigCycleTime" SG_ 878 EngPwrUsageDisp_V 500;
BA_ "GenSigSNA" SG_ 878 EngPwrUsageDisp_V "0h";
BA_ "GenSigTimeout_CBC" SG_ 878 EngPwrUsageDisp_V 10500;
BA_ "RID" SG_ 878 EngPwrUsageDisp_V "6512";
BA_ "FlexKomComment" SG_ 878 HVACPwrUsageDisp "HCP Info for Display";
BA_ "FlexKomIsMotorola" SG_ 878 HVACPwrUsageDisp 1;
BA_ "FlexKomSID" SG_ 878 HVACPwrUsageDisp 2549;
BA_ "FlexKomSigLaenge" SG_ 878 HVACPwrUsageDisp 64;
BA_ "FlexKomSigName" SG_ 878 HVACPwrUsageDisp "HCP_DISP";
BA_ "FlexKomSigStartPos" SG_ 878 HVACPwrUsageDisp 7;
BA_ "FlexKomSigStartValue" SG_ 878 HVACPwrUsageDisp "0000000000000000h";
BA_ "GenSigCycleTime" SG_ 878 HVACPwrUsageDisp 500;
BA_ "GenSigSNA" SG_ 878 HVACPwrUsageDisp "0h";
BA_ "GenSigTimeout_CBC" SG_ 878 HVACPwrUsageDisp 10500;
BA_ "RID" SG_ 878 HVACPwrUsageDisp "6516";
BA_ "FlexKomComment" SG_ 878 HVACPwrUsageDisp_V "HCP Info for Display";
BA_ "FlexKomIsMotorola" SG_ 878 HVACPwrUsageDisp_V 1;
BA_ "FlexKomSID" SG_ 878 HVACPwrUsageDisp_V 2549;
BA_ "FlexKomSigLaenge" SG_ 878 HVACPwrUsageDisp_V 64;
BA_ "FlexKomSigName" SG_ 878 HVACPwrUsageDisp_V "HCP_DISP";
BA_ "FlexKomSigStartPos" SG_ 878 HVACPwrUsageDisp_V 7;
BA_ "FlexKomSigStartValue" SG_ 878 HVACPwrUsageDisp_V "0000000000000000h";
BA_ "GenSigCycleTime" SG_ 878 HVACPwrUsageDisp_V 500;
BA_ "GenSigSNA" SG_ 878 HVACPwrUsageDisp_V "0h";
BA_ "GenSigTimeout_CBC" SG_ 878 HVACPwrUsageDisp_V 10500;
BA_ "RID" SG_ 878 HVACPwrUsageDisp_V "6513";
BA_ "FlexKomComment" SG_ 878 HVBatSOCV_HCP "HCP Info for Display";
BA_ "FlexKomIsMotorola" SG_ 878 HVBatSOCV_HCP 1;
BA_ "FlexKomSID" SG_ 878 HVBatSOCV_HCP 2549;
BA_ "FlexKomSigLaenge" SG_ 878 HVBatSOCV_HCP 64;
BA_ "FlexKomSigName" SG_ 878 HVBatSOCV_HCP "HCP_DISP";
BA_ "FlexKomSigStartPos" SG_ 878 HVBatSOCV_HCP 7;
BA_ "FlexKomSigStartValue" SG_ 878 HVBatSOCV_HCP "0000000000000000h";
BA_ "GenSigCycleTime" SG_ 878 HVBatSOCV_HCP 500;
BA_ "GenSigSNA" SG_ 878 HVBatSOCV_HCP "0h";
BA_ "GenSigTimeout_CBC" SG_ 878 HVBatSOCV_HCP 10500;
BA_ "RID" SG_ 878 HVBatSOCV_HCP "6514";
BA_ "FlexKomComment" SG_ 878 HVBatSOC_HCP "HCP Info for Display";
BA_ "FlexKomIsMotorola" SG_ 878 HVBatSOC_HCP 1;
BA_ "FlexKomSID" SG_ 878 HVBatSOC_HCP 2549;
BA_ "FlexKomSigLaenge" SG_ 878 HVBatSOC_HCP 64;
BA_ "FlexKomSigName" SG_ 878 HVBatSOC_HCP "HCP_DISP";
BA_ "FlexKomSigStartPos" SG_ 878 HVBatSOC_HCP 7;
BA_ "FlexKomSigStartValue" SG_ 878 HVBatSOC_HCP "0000000000000000h";
BA_ "GenSigCycleTime" SG_ 878 HVBatSOC_HCP 500;
BA_ "GenSigSNA" SG_ 878 HVBatSOC_HCP "0h";
BA_ "GenSigTimeout_CBC" SG_ 878 HVBatSOC_HCP 10500;
BA_ "RID" SG_ 878 HVBatSOC_HCP "6519";
BA_ "FlexKomComment" SG_ 878 MtrPwrUsageDisp "HCP Info for Display";
BA_ "FlexKomIsMotorola" SG_ 878 MtrPwrUsageDisp 1;
BA_ "FlexKomSID" SG_ 878 MtrPwrUsageDisp 2549;
BA_ "FlexKomSigLaenge" SG_ 878 MtrPwrUsageDisp 64;
BA_ "FlexKomSigName" SG_ 878 MtrPwrUsageDisp "HCP_DISP";
BA_ "FlexKomSigStartPos" SG_ 878 MtrPwrUsageDisp 7;
BA_ "FlexKomSigStartValue" SG_ 878 MtrPwrUsageDisp "0000000000000000h";
BA_ "GenSigCycleTime" SG_ 878 MtrPwrUsageDisp 500;
BA_ "GenSigSNA" SG_ 878 MtrPwrUsageDisp "0h";
BA_ "FlexKomComment" SG_ 878 MtrPwrUsageDisp_V "HCP Info for Display";
BA_ "FlexKomIsMotorola" SG_ 878 MtrPwrUsageDisp_V 1;
BA_ "FlexKomSID" SG_ 878 MtrPwrUsageDisp_V 2549;
BA_ "FlexKomSigLaenge" SG_ 878 MtrPwrUsageDisp_V 64;
BA_ "FlexKomSigName" SG_ 878 MtrPwrUsageDisp_V "HCP_DISP";
BA_ "FlexKomSigStartPos" SG_ 878 MtrPwrUsageDisp_V 7;
BA_ "FlexKomSigStartValue" SG_ 878 MtrPwrUsageDisp_V "0000000000000000h";
BA_ "GenSigCycleTime" SG_ 878 MtrPwrUsageDisp_V 500;
BA_ "GenSigSNA" SG_ 878 MtrPwrUsageDisp_V "0h";
BA_ "FlexKomComment" SG_ 291 AHH_Apply_Release_Request ".";
BA_ "FlexKomIsMotorola" SG_ 291 AHH_Apply_Release_Request 1;
BA_ "FlexKomSID" SG_ 291 AHH_Apply_Release_Request 2222;
BA_ "FlexKomSigLaenge" SG_ 291 AHH_Apply_Release_Request 64;
BA_ "FlexKomSigName" SG_ 291 AHH_Apply_Release_Request "HCP_Torq_Status";
BA_ "FlexKomSigStartPos" SG_ 291 AHH_Apply_Release_Request 7;
BA_ "FlexKomSigStartValue" SG_ 291 AHH_Apply_Release_Request "00000000000000FFh";
BA_ "GenSigCycleTime" SG_ 291 AHH_Apply_Release_Request 10;
BA_ "GenSigSNA" SG_ 291 AHH_Apply_Release_Request "7h";
BA_ "FlexKomComment" SG_ 291 AHH_ModifyAccel_Req ".";
BA_ "FlexKomIsMotorola" SG_ 291 AHH_ModifyAccel_Req 1;
BA_ "FlexKomSID" SG_ 291 AHH_ModifyAccel_Req 2222;
BA_ "FlexKomSigLaenge" SG_ 291 AHH_ModifyAccel_Req 64;
BA_ "FlexKomSigName" SG_ 291 AHH_ModifyAccel_Req "HCP_Torq_Status";
BA_ "FlexKomSigStartPos" SG_ 291 AHH_ModifyAccel_Req 7;
BA_ "FlexKomSigStartValue" SG_ 291 AHH_ModifyAccel_Req "00000000000000FFh";
BA_ "GenSigCycleTime" SG_ 291 AHH_ModifyAccel_Req 10;
BA_ "GenSigSNA" SG_ 291 AHH_ModifyAccel_Req "0h";
BA_ "FlexKomComment" SG_ 291 CRC_123h ".";
BA_ "FlexKomIsMotorola" SG_ 291 CRC_123h 1;
BA_ "FlexKomSID" SG_ 291 CRC_123h 2222;
BA_ "FlexKomSigLaenge" SG_ 291 CRC_123h 64;
BA_ "FlexKomSigName" SG_ 291 CRC_123h "HCP_Torq_Status";
BA_ "FlexKomSigStartPos" SG_ 291 CRC_123h 7;
BA_ "FlexKomSigStartValue" SG_ 291 CRC_123h "00000000000000FFh";
BA_ "GenSigCycleTime" SG_ 291 CRC_123h 10;
BA_ "GenSigSNA" SG_ 291 CRC_123h "FFh";
BA_ "GenSigStartValue" SG_ 291 CRC_123h 255;
BA_ "FlexKomComment" SG_ 291 MC_123h ".";
BA_ "FlexKomIsMotorola" SG_ 291 MC_123h 1;
BA_ "FlexKomSID" SG_ 291 MC_123h 2222;
BA_ "FlexKomSigLaenge" SG_ 291 MC_123h 64;
BA_ "FlexKomSigName" SG_ 291 MC_123h "HCP_Torq_Status";
BA_ "FlexKomSigStartPos" SG_ 291 MC_123h 7;
BA_ "FlexKomSigStartValue" SG_ 291 MC_123h "00000000000000FFh";
BA_ "GenSigCycleTime" SG_ 291 MC_123h 10;
BA_ "GenSigSNA" SG_ 291 MC_123h "0h";
BA_ "FlexKomComment" SG_ 291 M_MAX_AXLE ".";
BA_ "FlexKomIsMotorola" SG_ 291 M_MAX_AXLE 1;
BA_ "FlexKomSID" SG_ 291 M_MAX_AXLE 2222;
BA_ "FlexKomSigLaenge" SG_ 291 M_MAX_AXLE 64;
BA_ "FlexKomSigName" SG_ 291 M_MAX_AXLE "HCP_Torq_Status";
BA_ "FlexKomSigStartPos" SG_ 291 M_MAX_AXLE 7;
BA_ "FlexKomSigStartValue" SG_ 291 M_MAX_AXLE "00000000000000FFh";
BA_ "GenSigCycleTime" SG_ 291 M_MAX_AXLE 10;
BA_ "GenSigSNA" SG_ 291 M_MAX_AXLE "1FFFh";
BA_ "FlexKomComment" SG_ 291 M_MIN_AXLE ".";
BA_ "FlexKomIsMotorola" SG_ 291 M_MIN_AXLE 1;
BA_ "FlexKomSID" SG_ 291 M_MIN_AXLE 2222;
BA_ "FlexKomSigLaenge" SG_ 291 M_MIN_AXLE 64;
BA_ "FlexKomSigName" SG_ 291 M_MIN_AXLE "HCP_Torq_Status";
BA_ "FlexKomSigStartPos" SG_ 291 M_MIN_AXLE 7;
BA_ "FlexKomSigStartValue" SG_ 291 M_MIN_AXLE "00000000000000FFh";
BA_ "GenSigCycleTime" SG_ 291 M_MIN_AXLE 10;
BA_ "GenSigSNA" SG_ 291 M_MIN_AXLE "1FFFh";
BA_ "FlexKomComment" SG_ 291 M_STA_AXLE ".";
BA_ "FlexKomIsMotorola" SG_ 291 M_STA_AXLE 1;
BA_ "FlexKomSID" SG_ 291 M_STA_AXLE 2222;
BA_ "FlexKomSigLaenge" SG_ 291 M_STA_AXLE 64;
BA_ "FlexKomSigName" SG_ 291 M_STA_AXLE "HCP_Torq_Status";
BA_ "FlexKomSigStartPos" SG_ 291 M_STA_AXLE 7;
BA_ "FlexKomSigStartValue" SG_ 291 M_STA_AXLE "00000000000000FFh";
BA_ "GenSigCycleTime" SG_ 291 M_STA_AXLE 10;
BA_ "GenSigSNA" SG_ 291 M_STA_AXLE "1FFFh";
BA_ "FlexKomComment" SG_ 560 AC_PT_Demand "Maximum A/C demand to powertrain";
BA_ "FlexKomIsMotorola" SG_ 560 AC_PT_Demand 1;
BA_ "FlexKomSID" SG_ 560 AC_PT_Demand 1945;
BA_ "FlexKomSigLaenge" SG_ 560 AC_PT_Demand 1;
BA_ "FlexKomSigName" SG_ 560 AC_PT_Demand "AC_PT_Demand";
BA_ "FlexKomSigStartPos" SG_ 560 AC_PT_Demand 5;
BA_ "FlexKomSigStartValue" SG_ 560 AC_PT_Demand "00h";
BA_ "GenSigCycleTime" SG_ 560 AC_PT_Demand 500;
BA_ "GenSigSendType" SG_ 560 AC_PT_Demand 5;
BA_ "GenSigSNA" SG_ 560 AC_PT_Demand "0h";
BA_ "RID" SG_ 560 AC_PT_Demand "1916";
BA_ "FlexKomComment" SG_ 560 AC_RQ "A/C clutch request; [1] = A/C Clutch requested; 0 ";
BA_ "FlexKomIsMotorola" SG_ 560 AC_RQ 1;
BA_ "FlexKomSID" SG_ 560 AC_RQ 27;
BA_ "FlexKomSigLaenge" SG_ 560 AC_RQ 1;
BA_ "FlexKomSigName" SG_ 560 AC_RQ "AC_RQ";
BA_ "FlexKomSigStartValue" SG_ 560 AC_RQ "00h";
BA_ "GenSigCycleTime" SG_ 560 AC_RQ 500;
BA_ "GenSigSendType" SG_ 560 AC_RQ 5;
BA_ "GenSigSNA" SG_ 560 AC_RQ "0h";
BA_ "RID" SG_ 560 AC_RQ "1237";
BA_ "FlexKomComment" SG_ 560 AC_SEL "Customer has selected A/C; [1] = A/C selected; 0 =";
BA_ "FlexKomIsMotorola" SG_ 560 AC_SEL 1;
BA_ "FlexKomSID" SG_ 560 AC_SEL 31;
BA_ "FlexKomSigLaenge" SG_ 560 AC_SEL 1;
BA_ "FlexKomSigName" SG_ 560 AC_SEL "AC_SEL";
BA_ "FlexKomSigStartPos" SG_ 560 AC_SEL 1;
BA_ "FlexKomSigStartValue" SG_ 560 AC_SEL "00h";
BA_ "GenSigCycleTime" SG_ 560 AC_SEL 500;
BA_ "GenSigSendType" SG_ 560 AC_SEL 5;
BA_ "GenSigSNA" SG_ 560 AC_SEL "0h";
BA_ "RID" SG_ 560 AC_SEL "1154";
BA_ "FlexKomComment" SG_ 560 DEFROST_SEL "Defrost select switch";
BA_ "FlexKomIsMotorola" SG_ 560 DEFROST_SEL 1;
BA_ "FlexKomSID" SG_ 560 DEFROST_SEL 28;
BA_ "FlexKomSigLaenge" SG_ 560 DEFROST_SEL 1;
BA_ "FlexKomSigName" SG_ 560 DEFROST_SEL "DEFROST_SEL";
BA_ "FlexKomSigStartPos" SG_ 560 DEFROST_SEL 2;
BA_ "FlexKomSigStartValue" SG_ 560 DEFROST_SEL "00h";
BA_ "GenSigCycleTime" SG_ 560 DEFROST_SEL 500;
BA_ "GenSigSendType" SG_ 560 DEFROST_SEL 5;
BA_ "GenSigSNA" SG_ 560 DEFROST_SEL "0h";
BA_ "RID" SG_ 560 DEFROST_SEL "1103";
BA_ "FlexKomComment" SG_ 560 EVAP_TEMP "AC evaporator temperature";
BA_ "FlexKomIsMotorola" SG_ 560 EVAP_TEMP 1;
BA_ "FlexKomSID" SG_ 560 EVAP_TEMP 29;
BA_ "FlexKomSigLaenge" SG_ 560 EVAP_TEMP 8;
BA_ "FlexKomSigName" SG_ 560 EVAP_TEMP "EVAP_TEMP";
BA_ "FlexKomSigStartPos" SG_ 560 EVAP_TEMP 15;
BA_ "FlexKomSigStartValue" SG_ 560 EVAP_TEMP "00h";
BA_ "GenSigCycleTime" SG_ 560 EVAP_TEMP 500;
BA_ "GenSigSendType" SG_ 560 EVAP_TEMP 5;
BA_ "GenSigSNA" SG_ 560 EVAP_TEMP "FFh";
BA_ "RID" SG_ 560 EVAP_TEMP "1096";
BA_ "FlexKomComment" SG_ 560 EVAP_TEMP_P1C "PDU for HVAC_A2";
BA_ "FlexKomIsMotorola" SG_ 560 EVAP_TEMP_P1C 1;
BA_ "FlexKomSID" SG_ 560 EVAP_TEMP_P1C 2867;
BA_ "FlexKomSigLaenge" SG_ 560 EVAP_TEMP_P1C 32;
BA_ "FlexKomSigName" SG_ 560 EVAP_TEMP_P1C "HVAC_A2_PDU";
BA_ "FlexKomSigStartPos" SG_ 560 EVAP_TEMP_P1C 39;
BA_ "FlexKomSigStartValue" SG_ 560 EVAP_TEMP_P1C "00000000h";
BA_ "GenSigCycleTime" SG_ 560 EVAP_TEMP_P1C 500;
BA_ "GenSigSNA" SG_ 560 EVAP_TEMP_P1C "7FFh";
BA_ "FlexKomComment" SG_ 560 EvapTempTar "Evaporator temperature target";
BA_ "FlexKomIsMotorola" SG_ 560 EvapTempTar 1;
BA_ "FlexKomSID" SG_ 560 EvapTempTar 30;
BA_ "FlexKomSigLaenge" SG_ 560 EvapTempTar 8;
BA_ "FlexKomSigName" SG_ 560 EvapTempTar "EvapTempTar";
BA_ "FlexKomSigStartPos" SG_ 560 EvapTempTar 23;
BA_ "FlexKomSigStartValue" SG_ 560 EvapTempTar "00h";
BA_ "GenSigCycleTime" SG_ 560 EvapTempTar 500;
BA_ "GenSigSendType" SG_ 560 EvapTempTar 5;
BA_ "GenSigSNA" SG_ 560 EvapTempTar "FFh";
BA_ "RID" SG_ 560 EvapTempTar "1247";
BA_ "FlexKomComment" SG_ 832 Est_Range_Disp "Estimated electric range for display";
BA_ "FlexKomIsMotorola" SG_ 832 Est_Range_Disp 1;
BA_ "FlexKomSID" SG_ 832 Est_Range_Disp 2543;
BA_ "FlexKomSigLaenge" SG_ 832 Est_Range_Disp 8;
BA_ "FlexKomSigName" SG_ 832 Est_Range_Disp "Est_Range_Disp";
BA_ "FlexKomSigStartPos" SG_ 832 Est_Range_Disp 39;
BA_ "FlexKomSigStartValue" SG_ 832 Est_Range_Disp "00h";
BA_ "GenSigCycleTime" SG_ 832 Est_Range_Disp 500;
BA_ "GenSigSNA" SG_ 832 Est_Range_Disp "FFh";
BA_ "GenSigTimeout_CBC" SG_ 832 Est_Range_Disp 5250;
BA_ "GenSigTimeout_ETM" SG_ 832 Est_Range_Disp 5250;
BA_ "RID" SG_ 832 Est_Range_Disp "6522";
BA_ "FlexKomComment" SG_ 832 VehSpdDisp "Vehicle speed - displayed";
BA_ "FlexKomIsMotorola" SG_ 832 VehSpdDisp 1;
BA_ "FlexKomSID" SG_ 832 VehSpdDisp 1430;
BA_ "FlexKomSigLaenge" SG_ 832 VehSpdDisp 16;
BA_ "FlexKomSigName" SG_ 832 VehSpdDisp "VehSpdDisp";
BA_ "FlexKomSigStartPos" SG_ 832 VehSpdDisp 55;
BA_ "FlexKomSigStartValue" SG_ 832 VehSpdDisp "FFFFh";
BA_ "GenSigCycleTime" SG_ 832 VehSpdDisp 500;
BA_ "GenSigSNA" SG_ 832 VehSpdDisp "FFFFh";
BA_ "GenSigStartValue" SG_ 832 VehSpdDisp 65535;
BA_ "GenSigTimeout_CBC" SG_ 832 VehSpdDisp 5250;
BA_ "RID" SG_ 832 VehSpdDisp "1057";
BA_ "FlexKomComment" SG_ 832 VehSpd_MPH "Vehicle speed signal is in miles per hour format";
BA_ "FlexKomIsMotorola" SG_ 832 VehSpd_MPH 1;
BA_ "FlexKomSID" SG_ 832 VehSpd_MPH 1585;
BA_ "FlexKomSigLaenge" SG_ 832 VehSpd_MPH 1;
BA_ "FlexKomSigName" SG_ 832 VehSpd_MPH "VehSpd_MPH";
BA_ "FlexKomSigStartPos" SG_ 832 VehSpd_MPH 47;
BA_ "FlexKomSigStartValue" SG_ 832 VehSpd_MPH "00h";
BA_ "GenSigCycleTime" SG_ 832 VehSpd_MPH 500;
BA_ "GenSigSNA" SG_ 832 VehSpd_MPH "0h";
BA_ "RID" SG_ 832 VehSpd_MPH "1330";
BA_ "FlexKomComment" SG_ 784 AvgFuelLvl "Average filtered fuel level in liters";
BA_ "FlexKomIsMotorola" SG_ 784 AvgFuelLvl 1;
BA_ "FlexKomSID" SG_ 784 AvgFuelLvl 848;
BA_ "FlexKomSigLaenge" SG_ 784 AvgFuelLvl 16;
BA_ "FlexKomSigName" SG_ 784 AvgFuelLvl "AvgFuelLvl";
BA_ "FlexKomSigStartPos" SG_ 784 AvgFuelLvl 7;
BA_ "FlexKomSigStartValue" SG_ 784 AvgFuelLvl "01FFh";
BA_ "GenSigCycleTime" SG_ 784 AvgFuelLvl 1000;
BA_ "GenSigSendType" SG_ 784 AvgFuelLvl 5;
BA_ "GenSigSNA" SG_ 784 AvgFuelLvl "1FFh";
BA_ "GenSigStartValue" SG_ 784 AvgFuelLvl 511;
BA_ "GenSigTimeout_CBC" SG_ 784 AvgFuelLvl 10500;
BA_ "GenSigTimeout_ETM" SG_ 784 AvgFuelLvl 10500;
BA_ "RID" SG_ 784 AvgFuelLvl "1196";
BA_ "FlexKomComment" SG_ 784 FuelLvlLow "Fuel level low";
BA_ "FlexKomIsMotorola" SG_ 784 FuelLvlLow 1;
BA_ "FlexKomSID" SG_ 784 FuelLvlLow 1049;
BA_ "FlexKomSigLaenge" SG_ 784 FuelLvlLow 1;
BA_ "FlexKomSigName" SG_ 784 FuelLvlLow "FuelLvlLow";
BA_ "FlexKomSigStartPos" SG_ 784 FuelLvlLow 6;
BA_ "FlexKomSigStartValue" SG_ 784 FuelLvlLow "00h";
BA_ "GenSigCycleTime" SG_ 784 FuelLvlLow 1000;
BA_ "GenSigSendType" SG_ 784 FuelLvlLow 5;
BA_ "GenSigSNA" SG_ 784 FuelLvlLow "0h";
BA_ "GenSigTimeout_CBC" SG_ 784 FuelLvlLow 10500;
BA_ "FlexKomComment" SG_ 784 ODO "Odometer";
BA_ "FlexKomIsMotorola" SG_ 784 ODO 1;
BA_ "FlexKomSID" SG_ 784 ODO 804;
BA_ "FlexKomSigLaenge" SG_ 784 ODO 24;
BA_ "FlexKomSigName" SG_ 784 ODO "ODO";
BA_ "FlexKomSigStartPos" SG_ 784 ODO 39;
BA_ "FlexKomSigStartValue" SG_ 784 ODO "FFFFFFh";
BA_ "GenSigCycleTime" SG_ 784 ODO 1000;
BA_ "GenSigSendType" SG_ 784 ODO 5;
BA_ "GenSigSNA" SG_ 784 ODO "FFFFFFh";
BA_ "GenSigStartValue" SG_ 784 ODO 16777215;
BA_ "GenSigTimeout_CBC" SG_ 784 ODO 10500;
BA_ "GenSigTimeout_EPS" SG_ 784 ODO 10500;
BA_ "GenSigTimeout_RHSC2" SG_ 784 ODO 10500;
BA_ "GenSigTimeout_ORC" SG_ 784 ODO 3500;
BA_ "GenSigTimeout_RF_HUB" SG_ 784 ODO 10500;
BA_ "GenSigTimeout_SCCM" SG_ 784 ODO 10500;
BA_ "RID" SG_ 784 ODO "1177 2112";
BA_ "FlexKomComment" SG_ 784 OilChgRst "Oil change reminder reset request";
BA_ "FlexKomIsMotorola" SG_ 784 OilChgRst 1;
BA_ "FlexKomSID" SG_ 784 OilChgRst 1819;
BA_ "FlexKomSigLaenge" SG_ 784 OilChgRst 1;
BA_ "FlexKomSigName" SG_ 784 OilChgRst "OilChgRst";
BA_ "FlexKomSigStartPos" SG_ 784 OilChgRst 29;
BA_ "FlexKomSigStartValue" SG_ 784 OilChgRst "00h";
BA_ "GenSigCycleTime" SG_ 784 OilChgRst 1000;
BA_ "GenSigSendType" SG_ 784 OilChgRst 5;
BA_ "GenSigSNA" SG_ 784 OilChgRst "0h";
BA_ "FlexKomComment" SG_ 784 PTS_MODE_SELECTION "Park assist maneuver selection for PTS";
BA_ "FlexKomIsMotorola" SG_ 784 PTS_MODE_SELECTION 1;
BA_ "FlexKomSID" SG_ 784 PTS_MODE_SELECTION 1910;
BA_ "FlexKomSigLaenge" SG_ 784 PTS_MODE_SELECTION 3;
BA_ "FlexKomSigName" SG_ 784 PTS_MODE_SELECTION "PTS_MODE_SELECTION";
BA_ "FlexKomSigStartPos" SG_ 784 PTS_MODE_SELECTION 62;
BA_ "FlexKomSigStartValue" SG_ 784 PTS_MODE_SELECTION "00h";
BA_ "GenSigCycleTime" SG_ 784 PTS_MODE_SELECTION 1000;
BA_ "GenSigSendType" SG_ 784 PTS_MODE_SELECTION 5;
BA_ "GenSigSNA" SG_ 784 PTS_MODE_SELECTION "7h";
BA_ "GenSigTimeout_PTS" SG_ 784 PTS_MODE_SELECTION 10500;
BA_ "FlexKomComment" SG_ 784 SBR_MuteRq "Seatbelt reminder audio mute request; Mute = [1]";
BA_ "FlexKomIsMotorola" SG_ 784 SBR_MuteRq 1;
BA_ "FlexKomSID" SG_ 784 SBR_MuteRq 2303;
BA_ "FlexKomSigLaenge" SG_ 784 SBR_MuteRq 1;
BA_ "FlexKomSigName" SG_ 784 SBR_MuteRq "SBR_MuteRq";
BA_ "FlexKomSigStartPos" SG_ 784 SBR_MuteRq 63;
BA_ "FlexKomSigStartValue" SG_ 784 SBR_MuteRq "00h";
BA_ "GenSigCycleTime" SG_ 784 SBR_MuteRq 1000;
BA_ "GenSigSendType" SG_ 784 SBR_MuteRq 5;
BA_ "GenSigSNA" SG_ 784 SBR_MuteRq "0h";
BA_ "RID" SG_ 784 SBR_MuteRq "2156";
BA_ "FlexKomComment" SG_ 784 SRS_LMP_STAT "Airbag indicator lamp status";
BA_ "FlexKomIsMotorola" SG_ 784 SRS_LMP_STAT 1;
BA_ "FlexKomSID" SG_ 784 SRS_LMP_STAT 851;
BA_ "FlexKomSigLaenge" SG_ 784 SRS_LMP_STAT 2;
BA_ "FlexKomSigName" SG_ 784 SRS_LMP_STAT "SRS_LMP_STAT";
BA_ "FlexKomSigStartPos" SG_ 784 SRS_LMP_STAT 5;
BA_ "FlexKomSigStartValue" SG_ 784 SRS_LMP_STAT "00h";
BA_ "GenSigCycleTime" SG_ 784 SRS_LMP_STAT 1000;
BA_ "GenSigSendType" SG_ 784 SRS_LMP_STAT 5;
BA_ "GenSigSNA" SG_ 784 SRS_LMP_STAT "3h";
BA_ "GenSigTimeout_ETM" SG_ 784 SRS_LMP_STAT 10500;
BA_ "GenSigTimeout_ORC" SG_ 784 SRS_LMP_STAT 3500;
BA_ "FlexKomComment" SG_ 882 CapacityUnit "Fuel capacity units";
BA_ "FlexKomIsMotorola" SG_ 882 CapacityUnit 1;
BA_ "FlexKomSID" SG_ 882 CapacityUnit 2001;
BA_ "FlexKomSigLaenge" SG_ 882 CapacityUnit 2;
BA_ "FlexKomSigName" SG_ 882 CapacityUnit "CapacityUnit";
BA_ "FlexKomSigStartPos" SG_ 882 CapacityUnit 39;
BA_ "FlexKomSigStartValue" SG_ 882 CapacityUnit "00h";
BA_ "GenSigCycleTime" SG_ 882 CapacityUnit 1000;
BA_ "GenSigSendType" SG_ 882 CapacityUnit 5;
BA_ "GenSigSNA" SG_ 882 CapacityUnit "0h";
BA_ "GenSigTimeout_CBC" SG_ 882 CapacityUnit 10500;
BA_ "RID" SG_ 882 CapacityUnit "1999";
BA_ "FlexKomComment" SG_ 882 ConsumptionUnit "Fuel consumption units";
BA_ "FlexKomIsMotorola" SG_ 882 ConsumptionUnit 1;
BA_ "FlexKomSID" SG_ 882 ConsumptionUnit 2005;
BA_ "FlexKomSigLaenge" SG_ 882 ConsumptionUnit 3;
BA_ "FlexKomSigName" SG_ 882 ConsumptionUnit "ConsumptionUnit";
BA_ "FlexKomSigStartPos" SG_ 882 ConsumptionUnit 55;
BA_ "FlexKomSigStartValue" SG_ 882 ConsumptionUnit "00h";
BA_ "GenSigCycleTime" SG_ 882 ConsumptionUnit 1000;
BA_ "GenSigSendType" SG_ 882 ConsumptionUnit 5;
BA_ "GenSigSNA" SG_ 882 ConsumptionUnit "7h";
BA_ "GenSigTimeout_CBC" SG_ 882 ConsumptionUnit 10500;
BA_ "RID" SG_ 882 ConsumptionUnit "2002";
BA_ "FlexKomComment" SG_ 882 DistanceUnit "Distance (odometer) units; Miles = [1]";
BA_ "FlexKomIsMotorola" SG_ 882 DistanceUnit 1;
BA_ "FlexKomSID" SG_ 882 DistanceUnit 2002;
BA_ "FlexKomSigLaenge" SG_ 882 DistanceUnit 1;
BA_ "FlexKomSigName" SG_ 882 DistanceUnit "DistanceUnit";
BA_ "FlexKomSigStartPos" SG_ 882 DistanceUnit 50;
BA_ "FlexKomSigStartValue" SG_ 882 DistanceUnit "00h";
BA_ "GenSigCycleTime" SG_ 882 DistanceUnit 1000;
BA_ "GenSigSendType" SG_ 882 DistanceUnit 5;
BA_ "GenSigSNA" SG_ 882 DistanceUnit "0h";
BA_ "RID" SG_ 882 DistanceUnit "1992";
BA_ "FlexKomComment" SG_ 882 Early_Fuel_TeenKey "Teen Key packet";
BA_ "FlexKomIsMotorola" SG_ 882 Early_Fuel_TeenKey 1;
BA_ "FlexKomSID" SG_ 882 Early_Fuel_TeenKey 2677;
BA_ "FlexKomSigLaenge" SG_ 882 Early_Fuel_TeenKey 2;
BA_ "FlexKomSigName" SG_ 882 Early_Fuel_TeenKey "TeenKey_Pkt";
BA_ "FlexKomSigStartPos" SG_ 882 Early_Fuel_TeenKey 27;
BA_ "FlexKomSigStartValue" SG_ 882 Early_Fuel_TeenKey "00h";
BA_ "GenSigCycleTime" SG_ 882 Early_Fuel_TeenKey 1000;
BA_ "GenSigSendType" SG_ 882 Early_Fuel_TeenKey 5;
BA_ "GenSigSNA" SG_ 882 Early_Fuel_TeenKey "0h";
BA_ "RID" SG_ 882 Early_Fuel_TeenKey "6290";
BA_ "FlexKomComment" SG_ 882 Fuel_Popup_TeenKey "Teen Key packet";
BA_ "FlexKomIsMotorola" SG_ 882 Fuel_Popup_TeenKey 1;
BA_ "FlexKomSID" SG_ 882 Fuel_Popup_TeenKey 2677;
BA_ "FlexKomSigLaenge" SG_ 882 Fuel_Popup_TeenKey 2;
BA_ "FlexKomSigName" SG_ 882 Fuel_Popup_TeenKey "TeenKey_Pkt";
BA_ "FlexKomSigStartPos" SG_ 882 Fuel_Popup_TeenKey 27;
BA_ "FlexKomSigStartValue" SG_ 882 Fuel_Popup_TeenKey "00h";
BA_ "GenSigCycleTime" SG_ 882 Fuel_Popup_TeenKey 1000;
BA_ "GenSigSendType" SG_ 882 Fuel_Popup_TeenKey 5;
BA_ "GenSigSNA" SG_ 882 Fuel_Popup_TeenKey "0h";
BA_ "RID" SG_ 882 Fuel_Popup_TeenKey "6294";
BA_ "FlexKomComment" SG_ 882 LANG_C "Configuration status";
BA_ "FlexKomIsMotorola" SG_ 882 LANG_C 1;
BA_ "FlexKomSID" SG_ 882 LANG_C 1804;
BA_ "FlexKomSigLaenge" SG_ 882 LANG_C 6;
BA_ "FlexKomSigName" SG_ 882 LANG_C "CFG_STAT_C";
BA_ "FlexKomSigStartPos" SG_ 882 LANG_C 15;
BA_ "FlexKomSigStartValue" SG_ 882 LANG_C "3Eh";
BA_ "GenSigCycleTime" SG_ 882 LANG_C 1000;
BA_ "GenSigSendType" SG_ 882 LANG_C 5;
BA_ "GenSigSNA" SG_ 882 LANG_C "1Fh";
BA_ "GenSigStartValue" SG_ 882 LANG_C 31;
BA_ "GenSigTimeout_CBC" SG_ 882 LANG_C 10500;
BA_ "RID" SG_ 882 LANG_C "1797";
BA_ "FlexKomComment" SG_ 882 PowerUnit "Power units";
BA_ "FlexKomIsMotorola" SG_ 882 PowerUnit 1;
BA_ "FlexKomSID" SG_ 882 PowerUnit 1999;
BA_ "FlexKomSigLaenge" SG_ 882 PowerUnit 2;
BA_ "FlexKomSigName" SG_ 882 PowerUnit "PowerUnit";
BA_ "FlexKomSigStartPos" SG_ 882 PowerUnit 35;
BA_ "FlexKomSigStartValue" SG_ 882 PowerUnit "00h";
BA_ "GenSigCycleTime" SG_ 882 PowerUnit 1000;
BA_ "GenSigSendType" SG_ 882 PowerUnit 5;
BA_ "GenSigSNA" SG_ 882 PowerUnit "0h";
BA_ "GenSigTimeout_CBC" SG_ 882 PowerUnit 10500;
BA_ "RID" SG_ 882 PowerUnit "2007";
BA_ "FlexKomComment" SG_ 882 PressureUnit "Pressure units";
BA_ "FlexKomIsMotorola" SG_ 882 PressureUnit 1;
BA_ "FlexKomSID" SG_ 882 PressureUnit 2000;
BA_ "FlexKomSigLaenge" SG_ 882 PressureUnit 2;
BA_ "FlexKomSigName" SG_ 882 PressureUnit "PressureUnit";
BA_ "FlexKomSigStartPos" SG_ 882 PressureUnit 37;
BA_ "FlexKomSigStartValue" SG_ 882 PressureUnit "00h";
BA_ "GenSigCycleTime" SG_ 882 PressureUnit 1000;
BA_ "GenSigSendType" SG_ 882 PressureUnit 5;
BA_ "GenSigSNA" SG_ 882 PressureUnit "0h";
BA_ "GenSigTimeout_CBC" SG_ 882 PressureUnit 10500;
BA_ "RID" SG_ 882 PressureUnit "1998";
BA_ "FlexKomComment" SG_ 882 RDY_DRV_STAT_CSO "Ready to drive popup status enable/disable; Disabl";
BA_ "FlexKomIsMotorola" SG_ 882 RDY_DRV_STAT_CSO 1;
BA_ "FlexKomSID" SG_ 882 RDY_DRV_STAT_CSO 2592;
BA_ "FlexKomSigLaenge" SG_ 882 RDY_DRV_STAT_CSO 1;
BA_ "FlexKomSigName" SG_ 882 RDY_DRV_STAT_CSO "RDY_DRV_STAT_CSO";
BA_ "FlexKomSigStartPos" SG_ 882 RDY_DRV_STAT_CSO 17;
BA_ "FlexKomSigStartValue" SG_ 882 RDY_DRV_STAT_CSO "00h";
BA_ "GenSigCycleTime" SG_ 882 RDY_DRV_STAT_CSO 1000;
BA_ "GenSigSendType" SG_ 882 RDY_DRV_STAT_CSO 5;
BA_ "GenSigSNA" SG_ 882 RDY_DRV_STAT_CSO "0h";
BA_ "RID" SG_ 882 RDY_DRV_STAT_CSO "5028";
BA_ "FlexKomComment" SG_ 882 SpeedUnit "Speed (speedometer) units; Miles = [1]";
BA_ "FlexKomIsMotorola" SG_ 882 SpeedUnit 1;
BA_ "FlexKomSID" SG_ 882 SpeedUnit 2004;
BA_ "FlexKomSigLaenge" SG_ 882 SpeedUnit 1;
BA_ "FlexKomSigName" SG_ 882 SpeedUnit "SpeedUnit";
BA_ "FlexKomSigStartPos" SG_ 882 SpeedUnit 51;
BA_ "FlexKomSigStartValue" SG_ 882 SpeedUnit "00h";
BA_ "GenSigCycleTime" SG_ 882 SpeedUnit 1000;
BA_ "GenSigSendType" SG_ 882 SpeedUnit 5;
BA_ "GenSigSNA" SG_ 882 SpeedUnit "0h";
BA_ "RID" SG_ 882 SpeedUnit "2000";
BA_ "FlexKomComment" SG_ 882 TemperatureUnit "Temperature units; Farenheit = [1]";
BA_ "FlexKomIsMotorola" SG_ 882 TemperatureUnit 1;
BA_ "FlexKomSID" SG_ 882 TemperatureUnit 2003;
BA_ "FlexKomSigLaenge" SG_ 882 TemperatureUnit 1;
BA_ "FlexKomSigName" SG_ 882 TemperatureUnit "TemperatureUnit";
BA_ "FlexKomSigStartPos" SG_ 882 TemperatureUnit 52;
BA_ "FlexKomSigStartValue" SG_ 882 TemperatureUnit "00h";
BA_ "GenSigCycleTime" SG_ 882 TemperatureUnit 1000;
BA_ "GenSigSendType" SG_ 882 TemperatureUnit 5;
BA_ "GenSigSNA" SG_ 882 TemperatureUnit "0h";
BA_ "RID" SG_ 882 TemperatureUnit "2004";
BA_ "FlexKomComment" SG_ 882 TorqueUnit "Torque units; Foot Pounds (ft-lb) = [1]";
BA_ "FlexKomIsMotorola" SG_ 882 TorqueUnit 1;
BA_ "FlexKomSID" SG_ 882 TorqueUnit 1998;
BA_ "FlexKomSigLaenge" SG_ 882 TorqueUnit 1;
BA_ "FlexKomSigName" SG_ 882 TorqueUnit "TorqueUnit";
BA_ "FlexKomSigStartPos" SG_ 882 TorqueUnit 7;
BA_ "FlexKomSigStartValue" SG_ 882 TorqueUnit "00h";
BA_ "GenSigCycleTime" SG_ 882 TorqueUnit 1000;
BA_ "GenSigSendType" SG_ 882 TorqueUnit 5;
BA_ "GenSigSNA" SG_ 882 TorqueUnit "0h";
BA_ "RID" SG_ 882 TorqueUnit "1994";
BA_ "FlexKomComment" SG_ 782 Gas_Range "IC_A5 packet";
BA_ "FlexKomIsMotorola" SG_ 782 Gas_Range 1;
BA_ "FlexKomSID" SG_ 782 Gas_Range 2522;
BA_ "FlexKomSigLaenge" SG_ 782 Gas_Range 64;
BA_ "FlexKomSigName" SG_ 782 Gas_Range "IC_A5_Pkt";
BA_ "FlexKomSigStartPos" SG_ 782 Gas_Range 7;
BA_ "FlexKomSigStartValue" SG_ 782 Gas_Range "03FF07FF00000000h";
BA_ "GenSigCycleTime" SG_ 782 Gas_Range 1000;
BA_ "GenSigSendType" SG_ 782 Gas_Range 5;
BA_ "GenSigSNA" SG_ 782 Gas_Range "3FFh";
BA_ "GenSigStartValue" SG_ 782 Gas_Range 1023;
BA_ "GenSigTimeout_CBC" SG_ 782 Gas_Range 10500;
BA_ "RID" SG_ 782 Gas_Range "3068";
BA_ "FlexKomComment" SG_ 782 Total_Range "IC_A5 packet";
BA_ "FlexKomIsMotorola" SG_ 782 Total_Range 1;
BA_ "FlexKomSID" SG_ 782 Total_Range 2522;
BA_ "FlexKomSigLaenge" SG_ 782 Total_Range 64;
BA_ "FlexKomSigName" SG_ 782 Total_Range "IC_A5_Pkt";
BA_ "FlexKomSigStartPos" SG_ 782 Total_Range 7;
BA_ "FlexKomSigStartValue" SG_ 782 Total_Range "03FF07FF00000000h";
BA_ "GenSigCycleTime" SG_ 782 Total_Range 1000;
BA_ "GenSigSendType" SG_ 782 Total_Range 5;
BA_ "GenSigSNA" SG_ 782 Total_Range "7FFh";
BA_ "GenSigStartValue" SG_ 782 Total_Range 2047;
BA_ "GenSigTimeout_CBC" SG_ 782 Total_Range 10500;
BA_ "RID" SG_ 782 Total_Range "3064";
BA_ "FlexKomComment" SG_ 938 A_EV_Kilometers "IC Trip data packet 1";
BA_ "FlexKomIsMotorola" SG_ 938 A_EV_Kilometers 1;
BA_ "FlexKomSID" SG_ 938 A_EV_Kilometers 2585;
BA_ "FlexKomSigLaenge" SG_ 938 A_EV_Kilometers 64;
BA_ "FlexKomSigName" SG_ 938 A_EV_Kilometers "IC_TripData_Pkt_1";
BA_ "FlexKomSigStartPos" SG_ 938 A_EV_Kilometers 7;
BA_ "FlexKomSigStartValue" SG_ 938 A_EV_Kilometers "0000000000000000h";
BA_ "GenSigCycleTime" SG_ 938 A_EV_Kilometers 1000;
BA_ "GenSigSNA" SG_ 938 A_EV_Kilometers "FFFFFFh";
BA_ "GenSigTimeout_ETM" SG_ 938 A_EV_Kilometers 10500;
BA_ "FlexKomComment" SG_ 938 A_EV_Miles "IC Trip data packet 1";
BA_ "FlexKomIsMotorola" SG_ 938 A_EV_Miles 1;
BA_ "FlexKomSID" SG_ 938 A_EV_Miles 2585;
BA_ "FlexKomSigLaenge" SG_ 938 A_EV_Miles 64;
BA_ "FlexKomSigName" SG_ 938 A_EV_Miles "IC_TripData_Pkt_1";
BA_ "FlexKomSigStartPos" SG_ 938 A_EV_Miles 7;
BA_ "FlexKomSigStartValue" SG_ 938 A_EV_Miles "0000000000000000h";
BA_ "GenSigCycleTime" SG_ 938 A_EV_Miles 1000;
BA_ "GenSigSNA" SG_ 938 A_EV_Miles "FFFFFFh";
BA_ "GenSigTimeout_ETM" SG_ 938 A_EV_Miles 10500;
BA_ "FlexKomComment" SG_ 938 A_MPG "IC Trip data packet 1";
BA_ "FlexKomIsMotorola" SG_ 938 A_MPG 1;
BA_ "FlexKomSID" SG_ 938 A_MPG 2585;
BA_ "FlexKomSigLaenge" SG_ 938 A_MPG 64;
BA_ "FlexKomSigName" SG_ 938 A_MPG "IC_TripData_Pkt_1";
BA_ "FlexKomSigStartPos" SG_ 938 A_MPG 7;
BA_ "FlexKomSigStartValue" SG_ 938 A_MPG "0000000000000000h";
BA_ "GenSigCycleTime" SG_ 938 A_MPG 1000;
BA_ "GenSigSNA" SG_ 938 A_MPG "3FFh";
BA_ "GenSigTimeout_ETM" SG_ 938 A_MPG 10500;
BA_ "FlexKomComment" SG_ 939 A_Hybrid_Kilometers "IC Trip data packet 2";
BA_ "FlexKomIsMotorola" SG_ 939 A_Hybrid_Kilometers 1;
BA_ "FlexKomSID" SG_ 939 A_Hybrid_Kilometers 2584;
BA_ "FlexKomSigLaenge" SG_ 939 A_Hybrid_Kilometers 64;
BA_ "FlexKomSigName" SG_ 939 A_Hybrid_Kilometers "IC_TripData_Pkt_2";
BA_ "FlexKomSigStartPos" SG_ 939 A_Hybrid_Kilometers 7;
BA_ "FlexKomSigStartValue" SG_ 939 A_Hybrid_Kilometers "0000000000000000h";
BA_ "GenSigCycleTime" SG_ 939 A_Hybrid_Kilometers 1000;
BA_ "GenSigSNA" SG_ 939 A_Hybrid_Kilometers "FFFFFFh";
BA_ "GenSigTimeout_ETM" SG_ 939 A_Hybrid_Kilometers 10500;
BA_ "FlexKomComment" SG_ 939 A_Hybrid_Miles "IC Trip data packet 2";
BA_ "FlexKomIsMotorola" SG_ 939 A_Hybrid_Miles 1;
BA_ "FlexKomSID" SG_ 939 A_Hybrid_Miles 2584;
BA_ "FlexKomSigLaenge" SG_ 939 A_Hybrid_Miles 64;
BA_ "FlexKomSigName" SG_ 939 A_Hybrid_Miles "IC_TripData_Pkt_2";
BA_ "FlexKomSigStartPos" SG_ 939 A_Hybrid_Miles 7;
BA_ "FlexKomSigStartValue" SG_ 939 A_Hybrid_Miles "0000000000000000h";
BA_ "GenSigCycleTime" SG_ 939 A_Hybrid_Miles 1000;
BA_ "GenSigSNA" SG_ 939 A_Hybrid_Miles "FFFFFFh";
BA_ "GenSigTimeout_ETM" SG_ 939 A_Hybrid_Miles 10500;
BA_ "FlexKomComment" SG_ 939 A_KMpL "IC Trip data packet 2";
BA_ "FlexKomIsMotorola" SG_ 939 A_KMpL 1;
BA_ "FlexKomSID" SG_ 939 A_KMpL 2584;
BA_ "FlexKomSigLaenge" SG_ 939 A_KMpL 64;
BA_ "FlexKomSigName" SG_ 939 A_KMpL "IC_TripData_Pkt_2";
BA_ "FlexKomSigStartPos" SG_ 939 A_KMpL 7;
BA_ "FlexKomSigStartValue" SG_ 939 A_KMpL "0000000000000000h";
BA_ "GenSigCycleTime" SG_ 939 A_KMpL 1000;
BA_ "GenSigSNA" SG_ 939 A_KMpL "3FFh";
BA_ "GenSigTimeout_ETM" SG_ 939 A_KMpL 10500;
BA_ "FlexKomComment" SG_ 940 A_Total_Dist_Kilometers "IC Trip data packet 3";
BA_ "FlexKomIsMotorola" SG_ 940 A_Total_Dist_Kilometers 1;
BA_ "FlexKomSID" SG_ 940 A_Total_Dist_Kilometers 2583;
BA_ "FlexKomSigLaenge" SG_ 940 A_Total_Dist_Kilometers 64;
BA_ "FlexKomSigName" SG_ 940 A_Total_Dist_Kilometers "IC_TripData_Pkt_3";
BA_ "FlexKomSigStartPos" SG_ 940 A_Total_Dist_Kilometers 7;
BA_ "FlexKomSigStartValue" SG_ 940 A_Total_Dist_Kilometers "0000000000000000h";
BA_ "GenSigCycleTime" SG_ 940 A_Total_Dist_Kilometers 1000;
BA_ "GenSigSNA" SG_ 940 A_Total_Dist_Kilometers "FFFFFFh";
BA_ "GenSigTimeout_ETM" SG_ 940 A_Total_Dist_Kilometers 10500;
BA_ "FlexKomComment" SG_ 940 A_Total_Dist_Miles "IC Trip data packet 3";
BA_ "FlexKomIsMotorola" SG_ 940 A_Total_Dist_Miles 1;
BA_ "FlexKomSID" SG_ 940 A_Total_Dist_Miles 2583;
BA_ "FlexKomSigLaenge" SG_ 940 A_Total_Dist_Miles 64;
BA_ "FlexKomSigName" SG_ 940 A_Total_Dist_Miles "IC_TripData_Pkt_3";
BA_ "FlexKomSigStartPos" SG_ 940 A_Total_Dist_Miles 7;
BA_ "FlexKomSigStartValue" SG_ 940 A_Total_Dist_Miles "0000000000000000h";
BA_ "GenSigCycleTime" SG_ 940 A_Total_Dist_Miles 1000;
BA_ "GenSigSNA" SG_ 940 A_Total_Dist_Miles "FFFFFFh";
BA_ "GenSigTimeout_ETM" SG_ 940 A_Total_Dist_Miles 10500;
BA_ "FlexKomComment" SG_ 941 B_EV_Kilometers "IC Trip data packet 4";
BA_ "FlexKomIsMotorola" SG_ 941 B_EV_Kilometers 1;
BA_ "FlexKomSID" SG_ 941 B_EV_Kilometers 2582;
BA_ "FlexKomSigLaenge" SG_ 941 B_EV_Kilometers 64;
BA_ "FlexKomSigName" SG_ 941 B_EV_Kilometers "IC_TripData_Pkt_4";
BA_ "FlexKomSigStartPos" SG_ 941 B_EV_Kilometers 7;
BA_ "FlexKomSigStartValue" SG_ 941 B_EV_Kilometers "0000000000000000h";
BA_ "GenSigCycleTime" SG_ 941 B_EV_Kilometers 1000;
BA_ "GenSigSNA" SG_ 941 B_EV_Kilometers "FFFFFFh";
BA_ "GenSigTimeout_ETM" SG_ 941 B_EV_Kilometers 10500;
BA_ "FlexKomComment" SG_ 941 B_EV_Miles "IC Trip data packet 4";
BA_ "FlexKomIsMotorola" SG_ 941 B_EV_Miles 1;
BA_ "FlexKomSID" SG_ 941 B_EV_Miles 2582;
BA_ "FlexKomSigLaenge" SG_ 941 B_EV_Miles 64;
BA_ "FlexKomSigName" SG_ 941 B_EV_Miles "IC_TripData_Pkt_4";
BA_ "FlexKomSigStartPos" SG_ 941 B_EV_Miles 7;
BA_ "FlexKomSigStartValue" SG_ 941 B_EV_Miles "0000000000000000h";
BA_ "GenSigCycleTime" SG_ 941 B_EV_Miles 1000;
BA_ "GenSigSNA" SG_ 941 B_EV_Miles "FFFFFFh";
BA_ "GenSigTimeout_ETM" SG_ 941 B_EV_Miles 10500;
BA_ "FlexKomComment" SG_ 941 B_MPG "IC Trip data packet 4";
BA_ "FlexKomIsMotorola" SG_ 941 B_MPG 1;
BA_ "FlexKomSID" SG_ 941 B_MPG 2582;
BA_ "FlexKomSigLaenge" SG_ 941 B_MPG 64;
BA_ "FlexKomSigName" SG_ 941 B_MPG "IC_TripData_Pkt_4";
BA_ "FlexKomSigStartPos" SG_ 941 B_MPG 7;
BA_ "FlexKomSigStartValue" SG_ 941 B_MPG "0000000000000000h";
BA_ "GenSigCycleTime" SG_ 941 B_MPG 1000;
BA_ "GenSigSNA" SG_ 941 B_MPG "3FFh";
BA_ "GenSigTimeout_ETM" SG_ 941 B_MPG 10500;
BA_ "FlexKomComment" SG_ 942 B_Hybrid_Kilometers "IC Trip data packet 5";
BA_ "FlexKomIsMotorola" SG_ 942 B_Hybrid_Kilometers 1;
BA_ "FlexKomSID" SG_ 942 B_Hybrid_Kilometers 2581;
BA_ "FlexKomSigLaenge" SG_ 942 B_Hybrid_Kilometers 64;
BA_ "FlexKomSigName" SG_ 942 B_Hybrid_Kilometers "IC_TripData_Pkt_5";
BA_ "FlexKomSigStartPos" SG_ 942 B_Hybrid_Kilometers 7;
BA_ "FlexKomSigStartValue" SG_ 942 B_Hybrid_Kilometers "0000000000000000h";
BA_ "GenSigCycleTime" SG_ 942 B_Hybrid_Kilometers 1000;
BA_ "GenSigSNA" SG_ 942 B_Hybrid_Kilometers "FFFFFFh";
BA_ "GenSigTimeout_ETM" SG_ 942 B_Hybrid_Kilometers 10500;
BA_ "FlexKomComment" SG_ 942 B_Hybrid_Miles "IC Trip data packet 5";
BA_ "FlexKomIsMotorola" SG_ 942 B_Hybrid_Miles 1;
BA_ "FlexKomSID" SG_ 942 B_Hybrid_Miles 2581;
BA_ "FlexKomSigLaenge" SG_ 942 B_Hybrid_Miles 64;
BA_ "FlexKomSigName" SG_ 942 B_Hybrid_Miles "IC_TripData_Pkt_5";
BA_ "FlexKomSigStartPos" SG_ 942 B_Hybrid_Miles 7;
BA_ "FlexKomSigStartValue" SG_ 942 B_Hybrid_Miles "0000000000000000h";
BA_ "GenSigCycleTime" SG_ 942 B_Hybrid_Miles 1000;
BA_ "GenSigSNA" SG_ 942 B_Hybrid_Miles "FFFFFFh";
BA_ "GenSigTimeout_ETM" SG_ 942 B_Hybrid_Miles 10500;
BA_ "FlexKomComment" SG_ 942 B_KMpL "IC Trip data packet 5";
BA_ "FlexKomIsMotorola" SG_ 942 B_KMpL 1;
BA_ "FlexKomSID" SG_ 942 B_KMpL 2581;
BA_ "FlexKomSigLaenge" SG_ 942 B_KMpL 64;
BA_ "FlexKomSigName" SG_ 942 B_KMpL "IC_TripData_Pkt_5";
BA_ "FlexKomSigStartPos" SG_ 942 B_KMpL 7;
BA_ "FlexKomSigStartValue" SG_ 942 B_KMpL "0000000000000000h";
BA_ "GenSigCycleTime" SG_ 942 B_KMpL 1000;
BA_ "GenSigSNA" SG_ 942 B_KMpL "3FFh";
BA_ "GenSigTimeout_ETM" SG_ 942 B_KMpL 10500;
VAL_ 983 EC_ECUCfg10_Stat 0 "NA" 1 "PROGAMMED" 2 "REQUEST_DATA" 3 "SNA" ;
VAL_ 982 EC_ECUCfg11_Stat 0 "NA" 1 "PROGAMMED" 2 "REQUEST_DATA" 3 "SNA" ;
VAL_ 981 EC_ECUCfg12_Stat 0 "NA" 1 "PROGAMMED" 2 "REQUEST_DATA" 3 "SNA" ;
VAL_ 980 EC_ECUCfg13_Stat 0 "NA" 1 "PROGAMMED" 2 "REQUEST_DATA" 3 "SNA" ;
VAL_ 979 EC_ECUCfg14_Stat 0 "NA" 1 "PROGAMMED" 2 "REQUEST_DATA" 3 "SNA" ;
VAL_ 706 EC_ECUCfg15_Stat 0 "NA" 1 "PROGAMMED" 2 "REQUEST_DATA" 3 "SNA" ;
VAL_ 709 EC_ECUCfg16_Stat 0 "NA" 1 "PROGAMMED" 2 "REQUEST_DATA" 3 "SNA" ;
VAL_ 710 EC_ECUCfg17_Stat 0 "NA" 1 "PROGAMMED" 2 "REQUEST_DATA" 3 "SNA" ;
VAL_ 1009 EC_ECUCfg2_Stat 0 "NA" 1 "PROGAMMED" 2 "REQUEST_DATA" 3 "SNA" ;
VAL_ 1010 EC_ECUCfg3_Stat 0 "NA" 1 "PROGAMMED" 2 "REQUEST_DATA" 3 "SNA" ;
VAL_ 1011 EC_ECUCfg4_Stat 0 "NA" 1 "PROGAMMED" 2 "REQUEST_DATA" 3 "SNA" ;
VAL_ 1012 EC_ECUCfg5_Stat 0 "NA" 1 "PROGAMMED" 2 "REQUEST_DATA" 3 "SNA" ;
VAL_ 1013 EC_ECUCfg6_Stat 0 "NA" 1 "PROGAMMED" 2 "REQUEST_DATA" 3 "SNA" ;
VAL_ 1014 EC_ECUCfg7_Stat 0 "NA" 1 "PROGAMMED" 2 "REQUEST_DATA" 3 "SNA" ;
VAL_ 1015 EC_ECUCfg8_Stat 0 "NA" 1 "PROGAMMED" 2 "REQUEST_DATA" 3 "SNA" ;
VAL_ 984 EC_ECUCfg9_Stat 0 "NA" 1 "PROGAMMED" 2 "REQUEST_DATA" 3 "SNA" ;
VAL_ 908 GPS_Date_Day 255 "SNA" ;
VAL_ 908 GPS_Date_Month 255 "SNA" ;
VAL_ 908 GPS_Date_Year 65535 "SNA" ;
VAL_ 908 GPS_UTC_Hour 255 "SNA" ;
VAL_ 908 GPS_UTC_Minute 255 "SNA" ;
VAL_ 908 GPS_UTC_Second 65535 "SNA" ;
VAL_ 974 DRV_TEMP_DR_POS 127 "SNA" ;
VAL_ 974 FT_HVAC_BLW_FN_SP 127 "SNA" ;
VAL_ 974 PAS_TEMP_DR_POS 127 "SNA" ;
VAL_ 901 IBS2_Q_received 65535 "SNA" ;
VAL_ 901 IBS2_Q_released 65535 "SNA" ;
VAL_ 901 IBS2_Tm_Lst_Reset_Days 4095 "SNA" ;
VAL_ 901 IBS2_Tm_Lst_Reset_Sec 65535 "SNA" ;
VAL_ 639 IBS_Q_received 65535 "SNA" ;
VAL_ 639 IBS_Q_released 65535 "SNA" ;
VAL_ 639 IBS_Tm_Lst_Reset_Days 4095 "SNA" ;
VAL_ 639 IBS_Tm_Lst_Reset_Sec 65535 "SNA" ;
VAL_ 816 HVAC_CLNT_FLW_MIN 0 "OPEN" 254 "CLOSE" 255 "SNA" ;
VAL_ 816 PLG_Stat 0 "OK" 1 "UNLK" 2 "PK" 3 "DSBL" 4 "CLS_FG" 5 "OBS_DET" 6 "MAN_CLS" 7 "COLD" 8 "HOT" 10 "HF_CNTMNTD" 11 "RMP_OBS" 12 "RMP_SRVC" 13 "RMP_STOPPED" 14 "RMP_DPLY" 15 "RMP_STOW" ;
VAL_ 853 IBS_IBATT_QUIESCENT 253 "MEAS_NOT_DONE" 254 "MEAS_GT_1A" 255 "SNA" ;
VAL_ 854 IBS2_IBATT_QUIESCENT 253 "MEAS_NOT_DONE" 254 "MEAS_GT_1A" 255 "SNA" ;
VAL_ 799 IBS_R_Batt 2047 "SNA" ;
VAL_ 799 IBS_R_Batt_25 2047 "SNA" ;
VAL_ 799 TGW_AUD_MD_CAB_DR 0 "AM_SEL" 1 "FM_SEL" 2 "MW_SEL" 3 "LW_SEL" 4 "INT_Disk_SEL" 5 "INT_HDD_SEL" 6 "INT_AUX_SEL" 7 "INT_SLOT_SEL" 8 "USB3_SEL" 9 "SDAR1_SEL" 10 "SW_SEL" 11 "VES_DVD1_SEL" 12 "TMM_SEL" 13 "VES_AUX1_SEL" 14 "VES_AUX2_SEL" 15 "SDARV_SEL" 16 "PPR_SEL" 18 "DAB_SEL" 19 "TGW_USB1_SEL" 20 "ES_SEL" 21 "VES_AUX3_SEL" 22 "VES_AUX4_SEL" 23 "PASS_BT1_SEL" 24 "TV_SEL" 25 "USB2_SEL" 26 "APPS_SEL" 27 "AUD_MUTED" 28 "IR_OFF" 29 "RAD_OFF" 30 "RAD_LOCK" 31 "SNA" ;
VAL_ 798 IBS2_R_Batt 2047 "SNA" ;
VAL_ 798 IBS2_R_Batt_25 2047 "SNA" ;
VAL_ 817 PSD_LT_DisplayStat 0 "OK" 1 "UNLK" 2 "PK" 3 "DSBL" 4 "OLO" 5 "OBS_DET" 6 "MAN_CLS" 9 "FUEL_DR" 10 "HF_CNTMNTD" 11 "RMP_OBS" 12 "RMP_SRVC" 13 "RMP_STOPPED" 14 "RMP_DPLY" 15 "RMP_STOW" ;
VAL_ 817 PSD_RT_DisplayStat 0 "OK" 1 "UNLK" 2 "PK" 3 "DSBL" 4 "OLO" 5 "OBS_DET" 6 "MAN_CLS" 9 "FUEL_DR" 10 "HF_CNTMNTD" 11 "RMP_OBS" 12 "RMP_SRVC" 13 "RMP_STOPPED" 14 "RMP_DPLY" 15 "RMP_STOW" ;
VAL_ 579 TGW_AUD_MD2_CAB_DR 0 "NONE" 1 "Android_Auto" 2 "Apple_CarPlay" 3 "Music_Muted" ;
VAL_ 705 HVAC_Blwr_Perct 127 "SNA" ;
VAL_ 705 HtrCorTmp_InTgt 255 "SNA" ;
VAL_ 705 R_Blw1_Pos 127 "SNA" ;
VAL_ 705 R_Temp1_Pos 127 "SNA" ;
VAL_ 705 VEH_INT_TEMP 65535 "SNA" ;
VAL_ 678 DispPopupSts 0 "NONE" 1 "MESS1" 2 "MESS2" 3 "MESS3" 4 "MESS4" 5 "MESS5" 6 "MESS6" 7 "MESS7" 8 "MESS8" 9 "MESS9" 10 "MESS10" 11 "MESS11" 12 "MESS12" 13 "MESS13" 14 "MESS14" 15 "MESS15" 16 "MESS16" 17 "MESS17" 18 "MESS18" 19 "MESS19" 20 "MESS20" 21 "MESS21" 22 "MESS22" 255 "SNA" ;
VAL_ 678 DisplaySts 0 "OFF" 1 "MESS1" 2 "MESS2" 3 "MESS3" 4 "MESS4" 5 "MESS5" 6 "MESS6" 7 "MESS7" 8 "MESS8" 9 "MESS9" 10 "MESS10" 11 "MESS11" 12 "MESS12" 97 "MESS13" 98 "MESS14" 99 "MESS15" 100 "ESS16" 101 "ESS17" 102 "MESS18" 103 "ESS19" 104 "MESS20" 105 "ESS21" 106 "MESS22" 107 "MESS23" 108 "MESS24" 160 "MESS25" 161 "MESS26" 240 "MESS27" 255 "SNA" ;
VAL_ 678 HALF_CHIME_TYPESts 0 "NONE" 2 "HALF_MAS" 6 "HALF" 15 "SNA" ;
VAL_ 678 ISO_TelltaleSts 0 "OFF" 1 "WHITE" 2 "GREEN" 3 "YELLOW" 4 "YELLOW_F" 7 "SNA" ;
VAL_ 678 SensitivitySts 0 "OFF" 1 "S1" 2 "S2" 3 "S3" 4 "S4" 5 "S5" 7 "SNA" ;
VAL_ 678 TrqIntensitySts 0 "OFF" 1 "T1" 2 "T2" 3 "T3" 7 "SNA" ;
VAL_ 658 MTO_HALFDriveStyleSts 0 "NORMAL" 1 "CITY" 2 "SPORT" 3 "WINTER" 4 "SPORT_PLUS" 5 "TRACPLUS" 7 "SNA" ;
VAL_ 729 ConfigSts 0 "LEAST" 1 "LESS" 2 "MID" 3 "MORE" 4 "MOST" 7 "SNA" ;
VAL_ 729 LDW_LEDControlSts 0 "OFF" 1 "CONT" 2 "BLINK" 3 "SNA" ;
VAL_ 729 TorqueIntensitySts 0 "T1" 1 "T2" 2 "T3" 7 "SNA" ;
VAL_ 701 BatPwrUsage_V 0 "Valid" 1 "Not_Valid" ;
VAL_ 701 Est_Range 255 "SNA" ;
VAL_ 701 HEV_LMP_RQ 0 "OFF" 1 "ON" 2 "BLINK" 3 "SNA" ;
VAL_ 701 R134a_PressSts 511 "SNA" ;
VAL_ 655 CabinPreCondReqStat 0 "DEFAULT" 1 "PRE" 2 "SPR" 3 "PRE_OFF" 4 "PRF" 5 "NOT_OK" 6 "BCC" 7 "BCS" 15 "SNA" ;
VAL_ 655 ChargingLevel 0 "Default_NoLevel" 1 "Level_1_AC" 2 "Level_2_AC" 3 "Level_3_AC" 4 "Level_1_DC" 5 "Level_2_DC" 6 "PlugInNotDet" 7 "PPI_1_No_Drive" 8 "PPI_2_OK_Drive" 15 "SNA" ;
VAL_ 655 ChargingSysSts 0 "NotCharging" 1 "Charging" 2 "ChargeInterrupted" 3 "ChargeComplete" 7 "SNA" ;
VAL_ 655 CompStat 0 "NormalOperation" 1 "DegradedOperation" 2 "Inoperative" 3 "Reserved1" 4 "Reserved2" 5 "Reserved3" 6 "Reserved4" 15 "SNA" ;
VAL_ 655 EstTimeofChrg_Lv1 8191 "SNA" ;
VAL_ 655 EstTimeofChrg_Lv2 2047 "SNA" ;
VAL_ 655 HVBatCntctrStat 0 "Open" 1 "Precharging" 2 "Closed" 3 "Precharge_Failed" 4 "Precharge_Inhibited" 7 "SNA" ;
VAL_ 655 HtrCoreInletTemp 255 "SNA" ;
VAL_ 655 MIL_OnRq_BPCM 0 "FALSE" 1 "TRUE" ;
VAL_ 704 ElecClntHtrInletTemp 255 "SNA" ;
VAL_ 704 ElecCoolantHtrPwr 255 "SNA" ;
VAL_ 704 HTAuxPmpMontrngRPM 0 "TRUE" 1 "FALSE" 3 "SNA" ;
VAL_ 704 HTAuxPmpRPMAct 255 "SNA" ;
VAL_ 704 HTCabVlvPosn 127 "SNA" ;
VAL_ 704 HVBat_CoolantLvlLo 0 "FALSE" 1 "TRUE" 3 "SNA" ;
VAL_ 291 AHH_Apply_Release_Request 0 "No_Request" 1 "Apply" 2 "Blend_Release" 3 "Spare" 4 "Fast torque release" 5 "Apply_EPB" 6 "Apply_HYD" 7 "SNA" ;
VAL_ 291 M_MAX_AXLE 8191 "SNA" ;
VAL_ 291 M_MIN_AXLE 8191 "SNA" ;
VAL_ 291 M_STA_AXLE 8191 "SNA" ;
VAL_ 560 EVAP_TEMP 255 "SNA" ;
VAL_ 560 EVAP_TEMP_P1C 2047 "SNA" ;
VAL_ 560 EvapTempTar 255 "SNA" ;
VAL_ 832 Est_Range_Disp 255 "SNA" ;
VAL_ 832 VehSpdDisp 65535 "SNA" ;
VAL_ 784 AvgFuelLvl 511 "SNA" ;
VAL_ 784 ODO 16777215 "SNA" ;
VAL_ 784 PTS_MODE_SELECTION 0 "None" 1 "PARA" 2 "PERP" 3 "PULL_OUT" 4 "OVER" 7 "SNA" ;
VAL_ 784 SRS_LMP_STAT 0 "SRS_LMP_OFF" 1 "SRS_LMP_ON" 2 "SRS_LMP_ON_IC" 3 "SNA" ;
VAL_ 882 CapacityUnit 0 "L" 1 "G_UK" 2 "G_US" ;
VAL_ 882 ConsumptionUnit 0 "KMPL" 1 "LP100KM" 2 "MPG_UK" 3 "MPG_US" 7 "SNA" ;
VAL_ 882 LANG_C 0 "GERMAN" 1 "US_ENGLISH" 2 "FRENCH" 3 "ITALIAN" 4 "SPANISH" 5 "JAPANESE" 6 "PORTUGESE" 7 "DUTCH" 8 "UK_ENGLISH" 9 "MANDARIN_S" 10 "RUSSIAN" 11 "KOREAN" 12 "ARABIC" 13 "BRAZILIAN" 14 "MANDARIN_T" 15 "HINDI" 16 "TURKISH" 17 "POLISH" 31 "LANG_NO_CHG" ;
VAL_ 882 PowerUnit 0 "KW" 1 "HP_UK" 2 "HP_US" ;
VAL_ 882 PressureUnit 0 "KPA" 1 "BAR" 2 "PSI" ;
VAL_ 782 Gas_Range 1023 "SNA" ;
VAL_ 782 Total_Range 2047 "SNA" ;
VAL_ 938 A_EV_Kilometers 16777215 "SNA" ;
VAL_ 938 A_EV_Miles 16777215 "SNA" ;
VAL_ 938 A_MPG 1023 "SNA" ;
VAL_ 939 A_Hybrid_Kilometers 16777215 "SNA" ;
VAL_ 939 A_Hybrid_Miles 16777215 "SNA" ;
VAL_ 939 A_KMpL 1023 "SNA" ;
VAL_ 940 A_Total_Dist_Kilometers 16777215 "SNA" ;
VAL_ 940 A_Total_Dist_Miles 16777215 "SNA" ;
VAL_ 941 B_EV_Kilometers 16777215 "SNA" ;
VAL_ 941 B_EV_Miles 16777215 "SNA" ;
VAL_ 941 B_MPG 1023 "SNA" ;
VAL_ 942 B_Hybrid_Kilometers 16777215 "SNA" ;
VAL_ 942 B_Hybrid_Miles 16777215 "SNA" ;
VAL_ 942 B_KMpL 1023 "SNA" ;
